VERSION ""

NS_ :

BS_:

BU_: ICC_ICE DVR EPC BBCM PCL PLG EAMP CMSM SBOX AVAS FLZCU RXCU_HCU CGW TBOX BNCM CWC FRZCU

BO_ 1211 FLZCU_26: 32 FLZCU
 SG_ FLZCU_FLSeatHeiFb : 23|7@0+ (1,-1) [-1|100] "%"  ICC_ICE,BBCM,PCL
 SG_ FLZCU_FLSeatLvlFb : 31|7@0+ (1,-1) [-1|100] "%"  ICC_ICE,BBCM,PCL
 SG_ FLZCU_FLSeatBackAgFb : 39|7@0+ (1,-1) [-1|100] "%"  ICC_ICE,BBCM,PCL
 SG_ FLZCU_FLSeatCushFb : 47|7@0+ (1,-1) [-1|100] "%"  ICC_ICE,BBCM,PCL
 SG_ FLZCU_FLSeatLegSpprtFb : 55|7@0+ (1,-1) [-1|100] "%"  ICC_ICE
 SG_ FLZCU_SeatNeedMemory : 63|2@0+ (1,0) [0|3] ""  ICC_ICE
 SG_ FLZCU_MemoryFb : 61|2@0+ (1,0) [0|3] ""  ICC_ICE
 SG_ FLZCU_RecoverFb : 59|2@0+ (1,0) [0|3] ""  ICC_ICE
 SG_ FLZCU_DriverSeatMovFailCause : 87|4@0+ (1,0) [0|15] ""  ICC_ICE
 SG_ FLZCU_CurrSeatMemoryPos : 95|5@0+ (1,0) [0|31] ""  ICC_ICE

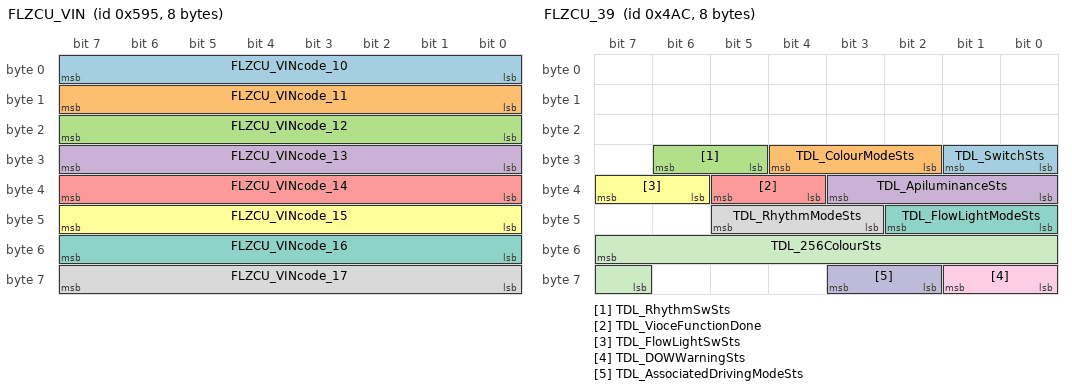
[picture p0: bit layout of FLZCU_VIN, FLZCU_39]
BO_ 1429 FLZCU_VIN: 8 FLZCU
 SG_ FLZCU_VINcode_10 : 7|8@0+ (1,0) [0|127] ""  ICC_ICE
 SG_ FLZCU_VINcode_11 : 15|8@0+ (1,0) [0|127] ""  ICC_ICE
 SG_ FLZCU_VINcode_12 : 23|8@0+ (1,0) [0|127] ""  ICC_ICE
 SG_ FLZCU_VINcode_13 : 31|8@0+ (1,0) [0|127] ""  ICC_ICE
 SG_ FLZCU_VINcode_14 : 39|8@0+ (1,0) [0|127] ""  ICC_ICE
 SG_ FLZCU_VINcode_15 : 47|8@0+ (1,0) [0|127] ""  ICC_ICE
 SG_ FLZCU_VINcode_16 : 55|8@0+ (1,0) [0|127] ""  ICC_ICE
 SG_ FLZCU_VINcode_17 : 63|8@0+ (1,0) [0|127] ""  ICC_ICE

BO_ 1072 FLZCU_31: 16 FLZCU
 SG_ LHFdoorSts_430h : 23|2@0+ (1,0) [0|3] ""  ICC_ICE
 SG_ LHFSeatBeltSW_430h : 31|1@0+ (1,0) [0|1] ""  ICC_ICE,DVR
 SG_ TrunkSts_430h : 37|2@0+ (1,0) [0|3] ""  ICC_ICE
 SG_ RLWinPosn_430h : 47|7@0+ (1,0) [0|100] "%"  ICC_ICE
 SG_ SeatHeatLevelsFL_430h : 49|2@0+ (1,0) [0|3] ""  ICC_ICE
 SG_ SeatHeatLevelsRL_430h : 61|2@0+ (1,0) [0|3] ""  ICC_ICE
 SG_ SeatVentLevelsFL_430h : 63|2@0+ (1,0) [0|3] ""  ICC_ICE
 SG_ SeatVentLevelsRL_430h : 87|2@0+ (1,0) [0|3] ""  ICC_ICE
 SG_ FLWinPosn_430h : 94|7@0+ (1,0) [0|100] "%"  ICC_ICE
 SG_ FLZCU_FrontWiperMaintenanceSts : 109|2@0+ (1,0) [0|3] ""  ICC_ICE
 SG_ FLZCU_RearWiperMaintenanceSts : 107|2@0+ (1,0) [0|3] ""  ICC_ICE

BO_ 1043 FLZCU_8: 8 FLZCU
 SG_ EBS_U_BATT : 7|14@0+ (0.0009765625,3) [3|18] "V"  ICC_ICE

BO_ 1022 FLZCU_40: 64 FLZCU
 SG_ FLZCU_CarMode : 23|3@0+ (1,0) [0|7] ""  ICC_ICE,BBCM,PCL
 SG_ FLZCU_SteerWhlposSts : 20|3@0+ (1,0) [0|7] ""  ICC_ICE
 SG_ FLZCU_MedStatusFb : 17|2@0+ (1,0) [0|3] ""  ICC_ICE,BBCM,PCL
 SG_ FLZCU_MedFailCause : 31|4@0+ (1,0) [0|15] ""  ICC_ICE
 SG_ FLZCU_MedAreaFb : 27|4@0+ (1,0) [0|15] ""  ICC_ICE
 SG_ FLZCU_MedClosePrompt : 39|2@0+ (1,0) [0|3] ""  ICC_ICE
 SG_ FLZCU_NapArea2Fb : 37|3@0+ (1,0) [0|7] ""  ICC_ICE
 SG_ FLZCU_2LSeatLvltargetCmd : 34|7@0+ (1,-1) [-1|100] "%"  ICC_ICE
 SG_ FLZCU_2LSeatBackAgtargetCmd : 43|7@0+ (1,-1) [-1|100] "%"  ICC_ICE
 SG_ FLZCU_2LSeatLegSpprttargetCmd : 52|7@0+ (1,-1) [-1|100] "%"  ICC_ICE
 SG_ FLZCU_FLWinThermalStatus : 61|1@0+ (1,0) [0|1] ""  ICC_ICE
 SG_ FLZCU_RLWinThermalStatus : 60|1@0+ (1,0) [0|1] ""  ICC_ICE
 SG_ FLZCU_MonoAmbLigSts : 59|1@0+ (1,0) [0|1] ""  ICC_ICE
 SG_ FLZCU_LogoChargingSts : 58|2@0+ (1,0) [0|3] ""  ICC_ICE
 SG_ FLZCU_2RSeatLvltargetCmd : 87|7@0+ (1,-1) [-1|100] "%"  ICC_ICE
 SG_ FLZCU_2RSeatBackAgtargetCmd : 80|7@0+ (1,-1) [-1|100] "%"  ICC_ICE
 SG_ FLZCU_2RSeatLegSpprttargetCmd : 89|7@0+ (1,-1) [-1|100] "%"  ICC_ICE
 SG_ FLZCU_SeatVentLvlFL2 : 111|4@0+ (1,0) [0|15] ""  ICC_ICE
 SG_ FLZCU_SeatVentLvlRL2 : 107|4@0+ (1,0) [0|15] ""  ICC_ICE
 SG_ FLZCU_SeatHeatLvlFL2 : 119|4@0+ (1,0) [0|15] ""  ICC_ICE
 SG_ FLZCU_SeatHeatLvlRL2 : 115|4@0+ (1,0) [0|15] ""  ICC_ICE
 SG_ FLZCU_FLSitPosnSts : 98|3@0+ (1,0) [0|7] ""  ICC_ICE
 SG_ FLZCU_SteerOverHeatWarn : 134|1@0+ (1,0) [0|1] ""  ICC_ICE
 SG_ FLZCU_FLogolightInhibitSts : 130|1@0+ (1,0) [0|1] ""  ICC_ICE
 SG_ MaintenanceOdometer_Backup_3FEh : 175|24@0+ (0.1,0) [0|999999.9] "KM"  ICC_ICE

BO_ 1020 FLZCU_41: 64 FLZCU
 SG_ SAM_1_SteeringAngleSpeed : 23|8@0+ (4,0) [0|1016] "deg/Sec"  ICC_ICE
 SG_ SAM_1_SteeringAngle : 31|16@0+ (0.0625,-2048) [-2048|2047.875] "deg"  ICC_ICE
 SG_ BMSH_MaxChgPwrPeak : 47|12@0+ (0.1,0) [0|320] "KW"  ICC_ICE
 SG_ BMSH_MaxDchgPwrPeak : 51|12@0+ (0.1,0) [0|320] "KW"  ICC_ICE
 SG_ FMCU_8_ISGF_SpdAct : 71|16@0+ (1,-32767) [-32767|32766] "rpm"  ICC_ICE
 SG_ RMCU_1_Speed : 87|16@0+ (1,-32767) [-32767|32766] "rpm"  ICC_ICE
 SG_ SAM_1_SteeringAngleVD : 96|1@0+ (1,0) [0|1] ""  ICC_ICE
 SG_ SAM_1_SteeringAngleSpeedVD : 97|1@0+ (1,0) [0|1] ""  ICC_ICE
 SG_ CSA_2_AllWarningInfo : 100|3@0+ (1,0) [0|7] ""  ICC_ICE
 SG_ RMCU_1_TCURErrLvlDis : 127|3@0+ (1,0) [0|4] ""  ICC_ICE
 SG_ ASU_2_sensorErrorSts : 143|4@0+ (1,0) [0|15] ""  ICC_ICE
 SG_ ASU_2_LFHeight : 151|12@0+ (0.1,-150) [0|259.4] "mm"  ICC_ICE
 SG_ ASU_2_RFHeight : 155|12@0+ (0.1,-150) [0|259.4] "mm"  ICC_ICE
 SG_ ASU_2_LRHeight : 175|12@0+ (0.1,-150) [0|259.4] "mm"  ICC_ICE
 SG_ ASU_2_RRHeight : 179|12@0+ (0.1,-150) [0|259.4] "mm"  ICC_ICE
 SG_ CSA_2_WiprFrntCmd : 209|2@0+ (1,0) [0|3] ""  ICC_ICE

BO_ 1035 VCC_1: 8 FLZCU
 SG_ VCC_1_OTASts : 17|2@0+ (1,0) [0|3] ""  ICC_ICE
 SG_ VCC_1_DriveMode : 36|5@0+ (1,0) [0|31] ""  ICC_ICE

BO_ 1075 VCC_2: 8 FLZCU
 SG_ VCC_2_ConfigurationMessageTrg : 23|1@0+ (1,0) [0|1] ""  ICC_ICE,BBCM,PCL,PLG

BO_ 1136 VCC_3: 32 FLZCU
 SG_ VCC_3_CRC : 7|8@0+ (1,0) [0|255] ""  ICC_ICE,BBCM,PCL,PLG
 SG_ VCC_3_RollgCntr : 11|4@0+ (1,0) [0|14] ""  ICC_ICE,BBCM,PCL,PLG
 SG_ VCC_3_Resd1 : 15|4@0+ (1,0) [0|15] ""  ICC_ICE,BBCM,PCL,PLG
 SG_ VCC_3_SN : 23|8@0+ (1,0) [1|32] ""  ICC_ICE,BBCM,PCL,PLG

BO_ 1196 FLZCU_39: 8 FLZCU
 SG_ TDL_SwitchSts : 25|2@0+ (1,0) [0|3] ""  ICC_ICE
 SG_ TDL_ColourModeSts : 28|3@0+ (1,0) [0|7] ""  ICC_ICE
 SG_ TDL_RhythmSwSts : 30|2@0+ (1,0) [0|3] ""  ICC_ICE
 SG_ TDL_ApiluminanceSts : 35|4@0+ (1,0) [0|15] ""  ICC_ICE
 SG_ TDL_VioceFunctionDone : 37|2@0+ (1,0) [0|3] ""  ICC_ICE
 SG_ TDL_FlowLightSwSts : 39|2@0+ (1,0) [0|3] ""  ICC_ICE
 SG_ TDL_FlowLightModeSts : 42|3@0+ (1,0) [0|7] ""  ICC_ICE
 SG_ TDL_RhythmModeSts : 45|3@0+ (1,0) [0|7] ""  ICC_ICE
 SG_ TDL_DOWWarningSts : 57|2@0+ (1,0) [0|3] ""  ICC_ICE
 SG_ TDL_AssociatedDrivingModeSts : 59|2@0+ (1,0) [0|3] ""  ICC_ICE
 SG_ TDL_256ColourSts : 55|9@0+ (1,0) [0|256] ""  ICC_ICE

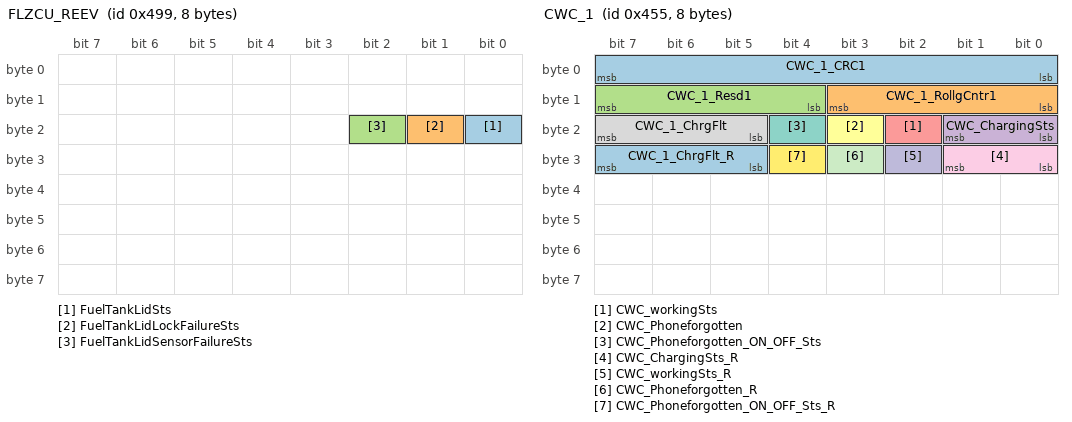
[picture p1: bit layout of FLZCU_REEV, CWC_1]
BO_ 1177 FLZCU_REEV: 8 FLZCU
 SG_ FuelTankLidSts : 16|1@0+ (1,0) [0|1] ""  ICC_ICE
 SG_ FuelTankLidLockFailureSts : 17|1@0+ (1,0) [0|1] ""  ICC_ICE
 SG_ FuelTankLidSensorFailureSts : 18|1@0+ (1,0) [0|1] ""  ICC_ICE

BO_ 2015 OBD_REQ_Broadcast: 64 CGW
 SG_ Diag_Functional_REQ : 7|64@0+ (1,0) [0|1.84467440737096E+19] ""  ICC_ICE,DVR,EPC,BBCM,PCL,PLG,EAMP,CMSM,SBOX

BO_ 1109 CWC_1: 8 CGW
 SG_ CWC_1_CRC1 : 7|8@0+ (1,0) [0|255] ""  ICC_ICE
 SG_ CWC_1_RollgCntr1 : 11|4@0+ (1,0) [0|14] ""  ICC_ICE
 SG_ CWC_1_Resd1 : 15|4@0+ (1,0) [0|15] ""  ICC_ICE
 SG_ CWC_ChargingSts : 17|2@0+ (1,0) [0|3] ""  ICC_ICE
 SG_ CWC_workingSts : 18|1@0+ (1,0) [0|1] ""  ICC_ICE
 SG_ CWC_Phoneforgotten : 19|1@0+ (1,0) [0|1] ""  ICC_ICE
 SG_ CWC_Phoneforgotten_ON_OFF_Sts : 20|1@0+ (1,0) [0|1] ""  ICC_ICE
 SG_ CWC_1_ChrgFlt : 23|3@0+ (1,0) [0|7] ""  ICC_ICE
 SG_ CWC_ChargingSts_R : 25|2@0+ (1,0) [0|3] ""  ICC_ICE
 SG_ CWC_workingSts_R : 26|1@0+ (1,0) [0|1] ""  ICC_ICE
 SG_ CWC_Phoneforgotten_R : 27|1@0+ (1,0) [0|1] ""  ICC_ICE
 SG_ CWC_Phoneforgotten_ON_OFF_Sts_R : 28|1@0+ (1,0) [0|1] ""  ICC_ICE
 SG_ CWC_1_ChrgFlt_R : 31|3@0+ (1,0) [0|7] ""  ICC_ICE

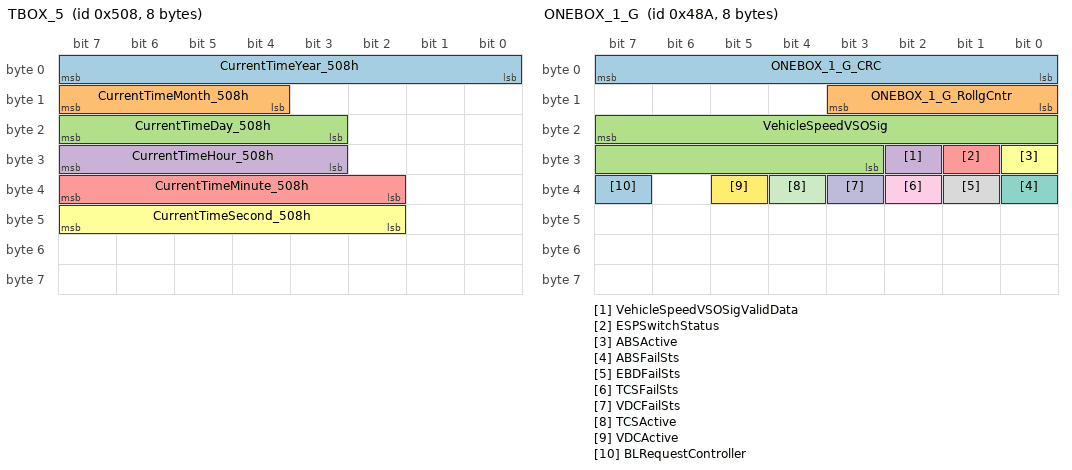
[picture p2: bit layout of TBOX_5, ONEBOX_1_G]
BO_ 1288 TBOX_5: 8 CGW
 SG_ CurrentTimeYear_508h : 7|8@0+ (1,2000) [2000|2255] ""  ICC_ICE,SBOX
 SG_ CurrentTimeMonth_508h : 15|4@0+ (1,0) [1|12] ""  ICC_ICE,SBOX
 SG_ CurrentTimeDay_508h : 23|5@0+ (1,0) [1|31] ""  ICC_ICE,SBOX
 SG_ CurrentTimeHour_508h : 31|5@0+ (1,0) [0|23] ""  ICC_ICE,SBOX
 SG_ CurrentTimeMinute_508h : 39|6@0+ (1,0) [0|59] ""  ICC_ICE,SBOX
 SG_ CurrentTimeSecond_508h : 47|6@0+ (1,0) [0|59] ""  ICC_ICE,SBOX

BO_ 1063 TBOX_6: 8 CGW
 SG_ TBOX_PetmodeSwitch : 19|2@0+ (1,0) [0|3] ""  ICC_ICE
 SG_ TBOX_SentinelModeSw : 21|2@0+ (1,0) [0|3] ""  ICC_ICE

BO_ 1148 TBOX_7: 32 CGW
 SG_ TBOX_GPSSwitchSts : 33|2@0+ (1,0) [0|3] ""  ICC_ICE
 SG_ TBOX_KeepWarmStrtMin : 151|6@0+ (1,0) [0|59] "分钟"  ICC_ICE
 SG_ TimeToStartSentinelDayFed_47Ch : 153|2@0+ (1,0) [0|3] "日"  ICC_ICE
 SG_ TimeToStartSentinelHourFed_47Ch : 158|5@0+ (1,0) [0|31] "小时"  ICC_ICE
 SG_ TimeToStartSentinelMinutFed_47Ch : 165|6@0+ (1,0) [0|63] "分钟"  ICC_ICE
 SG_ TimeToStopSentinelHourFed_47Ch : 172|5@0+ (1,0) [0|31] "小时"  ICC_ICE
 SG_ TimeToStopSentinelMinutFed_47Ch : 181|6@0+ (1,0) [0|63] "分钟"  ICC_ICE
 SG_ ReservationSentinelSts_Fed_47Ch : 183|2@0+ (1,0) [0|3] ""  ICC_ICE

BO_ 1162 ONEBOX_1_G: 8 CGW
 SG_ ONEBOX_1_G_CRC : 7|8@0+ (1,0) [0|255] ""  ICC_ICE,BBCM,PCL,PLG
 SG_ ONEBOX_1_G_RollgCntr : 11|4@0+ (1,0) [0|14] ""  ICC_ICE,BBCM,PCL,PLG
 SG_ VehicleSpeedVSOSig : 23|13@0+ (0.0625,0) [0|511.875] "km/h"  ICC_ICE,DVR,EPC,BBCM,PCL,PLG,EAMP,CMSM,SBOX,AVAS
 SG_ VehicleSpeedVSOSigValidData : 26|1@0+ (1,0) [0|1] ""  ICC_ICE,DVR,EPC,BBCM,PCL,PLG,EAMP,CMSM,SBOX,AVAS
 SG_ ESPSwitchStatus : 25|1@0+ (1,0) [0|1] ""  ICC_ICE
 SG_ ABSActive : 24|1@0+ (1,0) [0|1] ""  ICC_ICE
 SG_ ABSFailSts : 32|1@0+ (1,0) [0|1] ""  ICC_ICE
 SG_ EBDFailSts : 33|1@0+ (1,0) [0|1] ""  ICC_ICE
 SG_ TCSFailSts : 34|1@0+ (1,0) [0|1] ""  ICC_ICE
 SG_ VDCFailSts : 35|1@0+ (1,0) [0|1] ""  ICC_ICE
 SG_ TCSActive : 36|1@0+ (1,0) [0|1] ""  ICC_ICE
 SG_ VDCActive : 37|1@0+ (1,0) [0|1] ""  ICC_ICE
 SG_ BLRequestController : 39|1@0+ (1,0) [0|1] ""  ICC_ICE

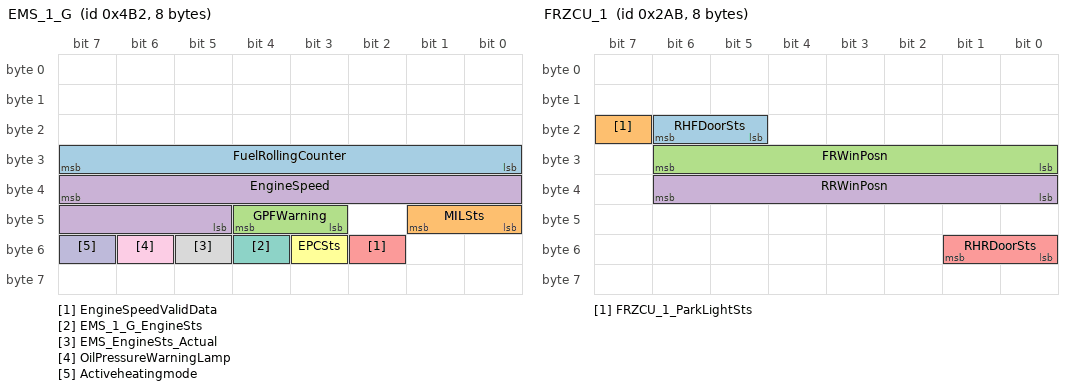
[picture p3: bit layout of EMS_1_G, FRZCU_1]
BO_ 1202 EMS_1_G: 8 CGW
 SG_ FuelRollingCounter : 31|8@0+ (7.88519E-05,0) [0|0.0200283826] "ltr"  ICC_ICE
 SG_ MILSts : 41|2@0+ (1,0) [0|3] ""  ICC_ICE
 SG_ GPFWarning : 44|2@0+ (1,0) [0|3] ""  ICC_ICE
 SG_ EngineSpeed : 39|11@0+ (4,0) [0|8000] "rpm"  ICC_ICE,AVAS
 SG_ EngineSpeedValidData : 50|1@0+ (1,0) [0|1] ""  ICC_ICE
 SG_ EPCSts : 51|1@0+ (1,0) [0|1] ""  ICC_ICE
 SG_ EMS_1_G_EngineSts : 52|1@0+ (1,0) [0|1] ""  ICC_ICE
 SG_ EMS_EngineSts_Actual : 53|1@0+ (1,0) [0|1] ""  ICC_ICE,EAMP
 SG_ OilPressureWarningLamp : 54|1@0+ (1,0) [0|1] ""  ICC_ICE
 SG_ Activeheatingmode : 55|1@0+ (1,0) [0|1] ""  ICC_ICE

BO_ 683 FRZCU_1: 8 CGW
 SG_ RHFDoorSts : 22|2@0+ (1,0) [0|3] ""  ICC_ICE,EPC,BBCM,PCL,CMSM
 SG_ FRZCU_1_ParkLightSts : 23|1@0+ (1,0) [0|1] ""  ICC_ICE
 SG_ FRWinPosn : 30|7@0+ (1,0) [0|100] "%"  ICC_ICE
 SG_ RRWinPosn : 38|7@0+ (1,0) [0|100] "%"  ICC_ICE
 SG_ RHRDoorSts : 49|2@0+ (1,0) [0|3] ""  ICC_ICE,EPC,BBCM,PCL,CMSM

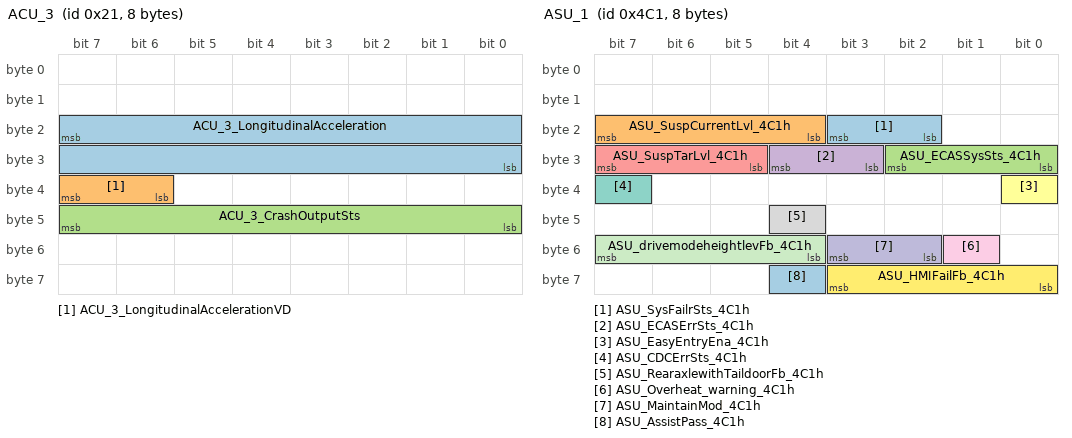
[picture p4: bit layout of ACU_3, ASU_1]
BO_ 33 ACU_3: 8 CGW
 SG_ ACU_3_LongitudinalAcceleration : 23|16@0+ (0.001,-2) [-2|2] "g"  ICC_ICE
 SG_ ACU_3_LongitudinalAccelerationVD : 39|2@0+ (1,0) [0|3] ""  ICC_ICE
 SG_ ACU_3_CrashOutputSts : 47|8@0+ (1,0) [0|255] ""  ICC_ICE,DVR,EPC,BBCM,PCL,SBOX

BO_ 1217 ASU_1: 8 CGW
 SG_ ASU_SysFailrSts_4C1h : 19|2@0+ (1,0) [0|3] ""  ICC_ICE
 SG_ ASU_SuspCurrentLvl_4C1h : 23|4@0+ (1,0) [0|15] ""  ICC_ICE
 SG_ ASU_ECASSysSts_4C1h : 26|3@0+ (1,0) [0|7] ""  ICC_ICE
 SG_ ASU_ECASErrSts_4C1h : 28|2@0+ (1,0) [0|3] ""  ICC_ICE
 SG_ ASU_SuspTarLvl_4C1h : 31|3@0+ (1,0) [0|7] ""  ICC_ICE
 SG_ ASU_EasyEntryEna_4C1h : 32|1@0+ (1,0) [0|1] ""  ICC_ICE
 SG_ ASU_CDCErrSts_4C1h : 39|1@0+ (1,0) [0|1] ""  ICC_ICE
 SG_ ASU_RearaxlewithTaildoorFb_4C1h : 44|1@0+ (1,0) [0|1] ""  ICC_ICE
 SG_ ASU_Overheat_warning_4C1h : 49|1@0+ (1,0) [0|1] ""  ICC_ICE
 SG_ ASU_MaintainMod_4C1h : 51|2@0+ (1,0) [0|3] ""  ICC_ICE
 SG_ ASU_drivemodeheightlevFb_4C1h : 55|4@0+ (1,0) [0|15] ""  ICC_ICE
 SG_ ASU_HMIFailFb_4C1h : 59|4@0+ (1,0) [0|15] ""  ICC_ICE
 SG_ ASU_AssistPass_4C1h : 60|1@0+ (1,0) [0|1] ""  ICC_ICE

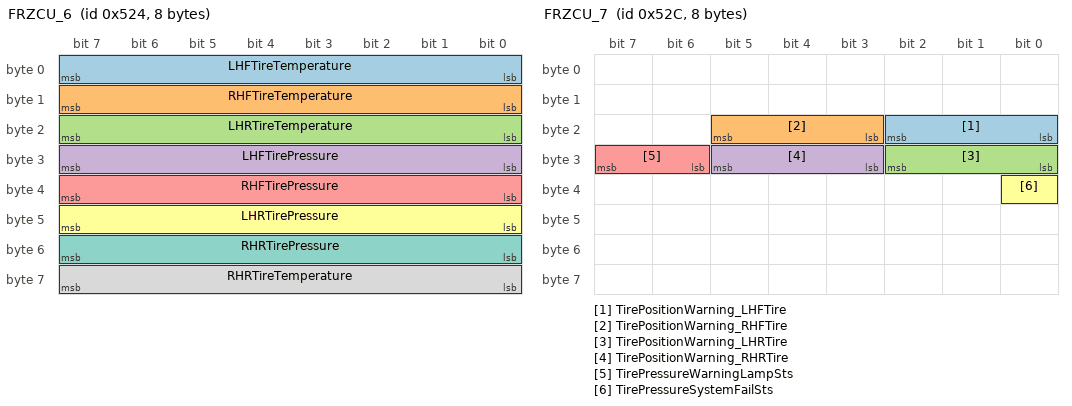
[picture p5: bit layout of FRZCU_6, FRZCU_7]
BO_ 1316 FRZCU_6: 8 CGW
 SG_ LHFTireTemperature : 7|8@0+ (0.65,-40) [-40|125.1] "℃"  ICC_ICE
 SG_ RHFTireTemperature : 15|8@0+ (0.65,-40) [-40|125.1] "℃"  ICC_ICE
 SG_ LHRTireTemperature : 23|8@0+ (0.65,-40) [-40|125.1] "℃"  ICC_ICE
 SG_ LHFTirePressure : 31|8@0+ (2.75,0) [0|701.25] "kPa"  ICC_ICE
 SG_ RHFTirePressure : 39|8@0+ (2.75,0) [0|701.25] "kPa"  ICC_ICE
 SG_ LHRTirePressure : 47|8@0+ (2.75,0) [0|701.25] "kPa"  ICC_ICE
 SG_ RHRTirePressure : 55|8@0+ (2.75,0) [0|701.25] "kPa"  ICC_ICE
 SG_ RHRTireTemperature : 63|8@0+ (0.65,-40) [-40|125.1] "℃"  ICC_ICE

BO_ 1324 FRZCU_7: 8 CGW
 SG_ TirePositionWarning_LHFTire : 18|3@0+ (1,0) [0|7] ""  ICC_ICE
 SG_ TirePositionWarning_RHFTire : 21|3@0+ (1,0) [0|7] ""  ICC_ICE
 SG_ TirePositionWarning_LHRTire : 26|3@0+ (1,0) [0|7] ""  ICC_ICE
 SG_ TirePositionWarning_RHRTire : 29|3@0+ (1,0) [0|7] ""  ICC_ICE
 SG_ TirePressureWarningLampSts : 31|2@0+ (1,0) [0|3] ""  ICC_ICE
 SG_ TirePressureSystemFailSts : 32|1@0+ (1,0) [0|1] ""  ICC_ICE

BO_ 991 TMS_2: 24 CGW
 SG_ TMS_MotorLoopErrorLevel : 126|3@0+ (1,0) [0|7] ""  ICC_ICE
 SG_ TMS_BatteryLoopErrorLevel : 123|3@0+ (1,0) [0|7] ""  ICC_ICE

BO_ 1188 TMS_3: 32 CGW
 SG_ FrontDeforestDisplaySts : 16|1@0+ (1,0) [0|1] ""  ICC_ICE
 SG_ TMS_DisplayActive : 18|1@0+ (1,0) [0|1] ""  ICC_ICE
 SG_ TMS_ZoneSelectionDisplaySts : 19|1@0+ (1,0) [0|1] ""  ICC_ICE
 SG_ TMS_AutoDisplaySts : 20|1@0+ (1,0) [0|1] ""  ICC_ICE
 SG_ TMS_FiltertchangeDisplaySts : 21|1@0+ (1,0) [0|1] ""  ICC_ICE
 SG_ TMS_AUTODefrostOnSts : 22|1@0+ (1,0) [0|1] ""  ICC_ICE
 SG_ TMS_AUTODefrostDisplaySts : 23|1@0+ (1,0) [0|1] ""  ICC_ICE
 SG_ TMS_RefInSufDispSts : 24|1@0+ (1,0) [0|1] ""  ICC_ICE
 SG_ TMS_CooltInSufDispSts : 25|1@0+ (1,0) [0|1] ""  ICC_ICE
 SG_ TMS_DLOnOffSts : 26|1@0+ (1,0) [0|1] ""  ICC_ICE
 SG_ TMS_DROnOffSts : 27|1@0+ (1,0) [0|1] ""  ICC_ICE
 SG_ TMS_PLOnOffSts : 28|1@0+ (1,0) [0|1] ""  ICC_ICE
 SG_ WorkingSts : 29|1@0+ (1,0) [0|1] ""  ICC_ICE
 SG_ TMS_PROnOffSts : 30|1@0+ (1,0) [0|1] ""  ICC_ICE
 SG_ TMS_DCOnOffSts : 31|1@0+ (1,0) [0|1] ""  ICC_ICE
 SG_ TMS_ACFastCool : 48|1@0+ (1,0) [0|1] ""  ICC_ICE
 SG_ TMS_ACFastHeat : 49|1@0+ (1,0) [0|1] ""  ICC_ICE
 SG_ TMS_LoveRemind : 50|1@0+ (1,0) [0|1] ""  ICC_ICE
 SG_ TMS_InteCleanCar : 51|1@0+ (1,0) [0|1] ""  ICC_ICE
 SG_ TMS_ACVentilationSts : 52|1@0+ (1,0) [0|1] ""  ICC_ICE
 SG_ TMS_AutoAirCleanSts : 53|1@0+ (1,0) [0|1] ""  ICC_ICE
 SG_ PM25Sts : 54|1@0+ (1,0) [0|1] ""  ICC_ICE
 SG_ TMS_ACModeCustomSts : 33|2@0+ (1,0) [0|3] ""  ICC_ICE
 SG_ TMS_ACRequestDisplaySts : 36|3@0+ (1,0) [0|7] ""  ICC_ICE
 SG_ TMS_AUTODefLevelSts : 39|3@0+ (1,0) [0|7] ""  ICC_ICE
 SG_ TMS_KeepWarm : 41|2@0+ (1,0) [0|3] ""  ICC_ICE
 SG_ TMS_DSwingSts : 44|3@0+ (1,0) [0|7] ""  ICC_ICE
 SG_ TMS_PSwingSts : 47|3@0+ (1,0) [0|7] ""  ICC_ICE
 SG_ TMS_TuisongDispSts : 58|3@0+ (1,0) [0|7] ""  ICC_ICE
 SG_ TMS_SetTemperature_L_C : 63|5@0+ (0.5,15.5) [15.5|30.5] ""  ICC_ICE
 SG_ TMS_SetTemperature_R_C : 68|5@0+ (0.5,15.5) [15.5|30.5] ""  ICC_ICE
 SG_ TMS_ModeAdjustDisplaySts : 75|4@0+ (1,0) [0|15] ""  ICC_ICE
 SG_ TMS_CirculationModeDisplaySts : 79|2@0+ (1,0) [0|3] ""  ICC_ICE
 SG_ TMS_IncarTemp : 87|8@0+ (0.5,-40) [-40|85] ""  ICC_ICE
 SG_ TMS_FliterLife : 94|7@0+ (1,0) [0|100] ""  ICC_ICE
 SG_ TMS_DLSwingUpDwnWPosn : 102|7@0+ (1,0) [0|100] ""  ICC_ICE
 SG_ TMS_DLSwingLeRiWPosn : 110|7@0+ (1,0) [0|100] ""  ICC_ICE
 SG_ TMS_DRSwingUpDwnWPosn : 118|7@0+ (1,0) [0|100] ""  ICC_ICE
 SG_ TMS_DRSwingLeRiWPosn : 126|7@0+ (1,0) [0|100] ""  ICC_ICE
 SG_ TMS_PLSwingUpDwnWPosn : 134|7@0+ (1,0) [0|100] ""  ICC_ICE
 SG_ TMS_PLSwingLeRiWPosn : 142|7@0+ (1,0) [0|100] ""  ICC_ICE
 SG_ TMS_PRSwingUpDwnWPosn : 150|7@0+ (1,0) [0|100] ""  ICC_ICE
 SG_ TMS_PRSwingLeRiWPosn : 158|7@0+ (1,0) [0|100] ""  ICC_ICE
 SG_ TMS_DCSwingLeRiWPosn : 166|7@0+ (1,0) [0|100] ""  ICC_ICE
 SG_ AirSwingSts : 168|1@0+ (1,0) [0|1] ""  ICC_ICE
 SG_ TemperatureUnit : 169|1@0+ (1,0) [0|1] ""  ICC_ICE
 SG_ BlowAdvanceOnSts : 170|1@0+ (1,0) [0|1] ""  ICC_ICE
 SG_ BlowDelayOffSts : 171|1@0+ (1,0) [0|1] ""  ICC_ICE
 SG_ TMS_PM25_ExtSts : 172|1@0+ (1,0) [0|1] ""  ICC_ICE
 SG_ TMS_PM25_IncarSts : 173|1@0+ (1,0) [0|1] ""  ICC_ICE
 SG_ TMS_AQS_Sts : 174|1@0+ (1,0) [0|1] ""  ICC_ICE
 SG_ PM25overproofDisplaySts : 175|1@0+ (1,0) [0|1] ""  ICC_ICE
 SG_ AQSDisplaySts : 176|1@0+ (1,0) [0|1] ""  ICC_ICE
 SG_ PM25AutoRunSts : 177|1@0+ (1,0) [0|1] ""  ICC_ICE
 SG_ PM25AutoRunSetSts : 178|1@0+ (1,0) [0|1] ""  ICC_ICE
 SG_ FragranceWelcomeModeSts : 179|1@0+ (1,0) [0|1] ""  ICC_ICE
 SG_ FragranceDisplaysts : 180|1@0+ (1,0) [0|1] ""  ICC_ICE
 SG_ TMS_AQS_Level : 185|2@0+ (1,0) [0|3] ""  ICC_ICE
 SG_ ACRequestCommand : 188|3@0+ (1,0) [0|7] ""  ICC_ICE
 SG_ PM25_Outcar_Level : 191|3@0+ (1,0) [0|7] ""  ICC_ICE
 SG_ PM25_Incar_Level : 194|3@0+ (1,0) [0|7] ""  ICC_ICE
 SG_ SetTemperature_L_F : 215|5@0+ (1,63) [63|93] ""  ICC_ICE
 SG_ SetTemperature_R_F : 223|5@0+ (1,63) [63|93] ""  ICC_ICE
 SG_ TMS_PM25_incar : 231|10@0+ (1,0) [0|1000] ""  ICC_ICE
 SG_ TMS_PM25_ext : 237|10@0+ (1,0) [0|1000] ""  ICC_ICE
 SG_ TMS_KeepWarmMemoryFb : 243|2@0+ (1,0) [0|3] ""  ICC_ICE

BO_ 612 EPB_R_1: 24 CGW
 SG_ CRC1_264h : 7|8@0+ (1,0) [0|255] ""  ICC_ICE
 SG_ RollgCntr1_264h : 11|4@0+ (1,0) [0|14] ""  ICC_ICE
 SG_ FltLamp_264h : 18|2@0+ (1,0) [0|3] ""  ICC_ICE
 SG_ ParkLamp_264h : 20|2@0+ (1,0) [0|3] ""  ICC_ICE
 SG_ ActrSt_264h : 23|3@0+ (1,0) [0|7] ""  ICC_ICE,DVR
 SG_ RWUSt_264h : 25|1@0+ (1,0) [0|1] ""  ICC_ICE
 SG_ TextDisp_264h : 35|4@0+ (1,0) [0|15] ""  ICC_ICE
 SG_ IPB_EPBErrorStatus : 41|1@0+ (1,0) [0|1] ""  ICC_ICE

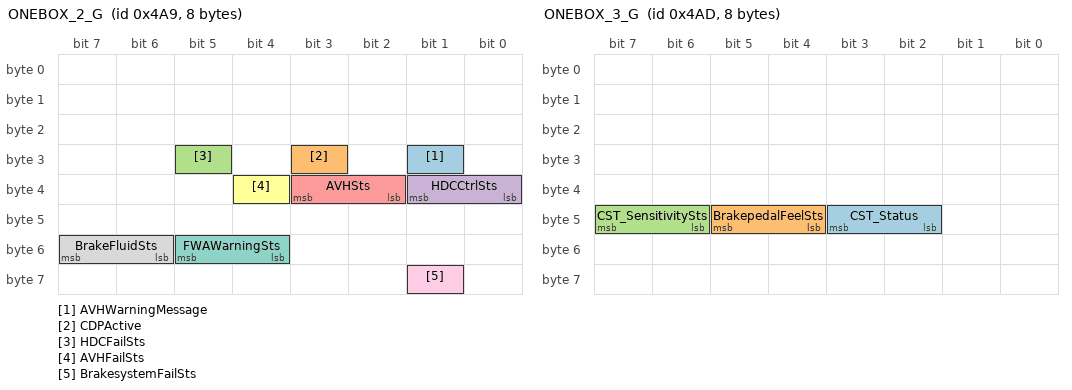
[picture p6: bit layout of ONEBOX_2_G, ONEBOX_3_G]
BO_ 1193 ONEBOX_2_G: 8 CGW
 SG_ AVHWarningMessage : 25|1@0+ (1,0) [0|1] ""  ICC_ICE
 SG_ CDPActive : 27|1@0+ (1,0) [0|1] ""  ICC_ICE
 SG_ HDCFailSts : 29|1@0+ (1,0) [0|1] ""  ICC_ICE
 SG_ HDCCtrlSts : 33|2@0+ (1,0) [0|3] ""  ICC_ICE
 SG_ AVHSts : 35|2@0+ (1,0) [0|3] ""  ICC_ICE
 SG_ AVHFailSts : 36|1@0+ (1,0) [0|1] ""  ICC_ICE
 SG_ FWAWarningSts : 53|2@0+ (1,0) [0|3] ""  ICC_ICE
 SG_ BrakeFluidSts : 55|2@0+ (1,0) [0|3] ""  ICC_ICE
 SG_ BrakesystemFailSts : 57|1@0+ (1,0) [0|1] ""  ICC_ICE

BO_ 1197 ONEBOX_3_G: 8 CGW
 SG_ CST_Status : 43|2@0+ (1,0) [0|3] ""  ICC_ICE
 SG_ BrakepedalFeelSts : 45|2@0+ (1,0) [0|3] ""  ICC_ICE
 SG_ CST_SensitivitySts : 47|2@0+ (1,0) [0|3] ""  ICC_ICE

BO_ 1200 FLZCU_6: 8 CGW
 SG_ SOC : 7|8@0+ (1,0) [0|100] "%"  ICC_ICE

BO_ 1061 FLZCU_18: 8 CGW
 SG_ DriverSeatMsgStr_LvlSts : 18|3@0+ (1,0) [0|7] ""  ICC_ICE
 SG_ DriverSeatMsg_ModeSts : 23|4@0+ (1,0) [0|15] ""  ICC_ICE

BO_ 1065 FLZCU_19: 8 CGW
 SG_ LeftSeatMsgStr_LvlSts : 18|3@0+ (1,0) [0|7] ""  ICC_ICE
 SG_ LeftSeatMsg_ModeSts : 23|4@0+ (1,0) [0|15] ""  ICC_ICE

BO_ 1069 FLZCU_20: 8 CGW
 SG_ PassSeatMsgStr_LvlSts : 18|3@0+ (1,0) [0|7] ""  ICC_ICE
 SG_ PassSeatMsg_ModeSts : 23|4@0+ (1,0) [0|15] ""  ICC_ICE

BO_ 1087 FLZCU_21: 8 CGW
 SG_ RightSeatMsgStr_LvlSts : 18|3@0+ (1,0) [0|7] ""  ICC_ICE
 SG_ RightSeatMsg_ModeSts : 23|4@0+ (1,0) [0|15] ""  ICC_ICE

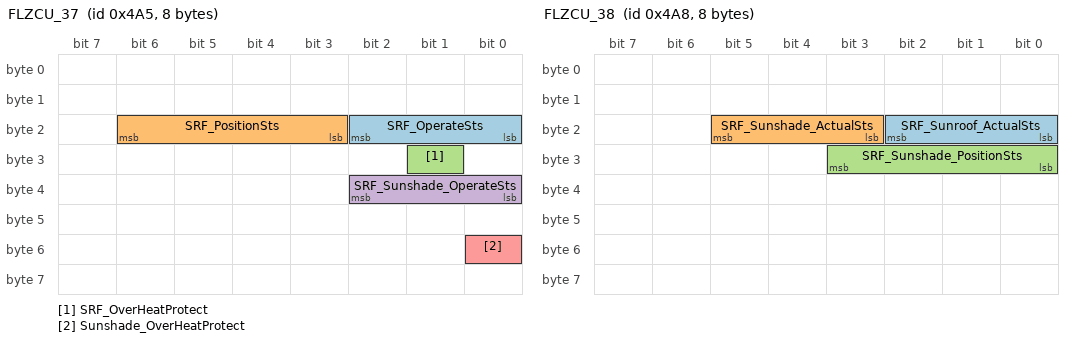
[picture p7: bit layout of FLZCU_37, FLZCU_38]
BO_ 1189 FLZCU_37: 8 CGW
 SG_ SRF_OperateSts : 18|3@0+ (1,0) [0|7] ""  ICC_ICE
 SG_ SRF_PositionSts : 22|4@0+ (1,0) [0|12] ""  ICC_ICE
 SG_ SRF_OverHeatProtect : 25|1@0+ (1,0) [0|1] ""  ICC_ICE
 SG_ SRF_Sunshade_OperateSts : 34|3@0+ (1,0) [0|7] ""  ICC_ICE
 SG_ Sunshade_OverHeatProtect : 48|1@0+ (1,0) [0|1] ""  ICC_ICE

BO_ 1192 FLZCU_38: 8 CGW
 SG_ SRF_Sunroof_ActualSts : 18|3@0+ (1,0) [0|7] ""  ICC_ICE
 SG_ SRF_Sunshade_ActualSts : 21|3@0+ (1,0) [0|7] ""  ICC_ICE
 SG_ SRF_Sunshade_PositionSts : 27|4@0+ (1,0) [0|12] ""  ICC_ICE

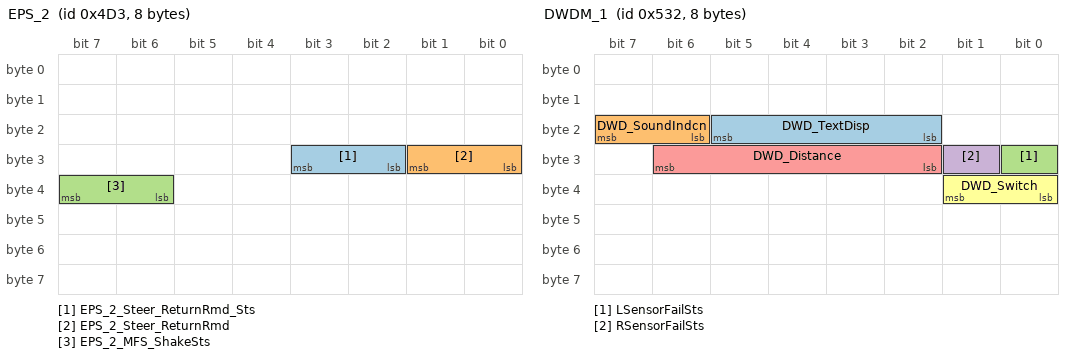
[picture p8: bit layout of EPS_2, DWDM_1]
BO_ 1235 EPS_2: 8 CGW
 SG_ EPS_2_Steer_ReturnRmd_Sts : 27|2@0+ (1,0) [0|3] ""  ICC_ICE
 SG_ EPS_2_Steer_ReturnRmd : 25|2@0+ (1,0) [0|3] ""  ICC_ICE
 SG_ EPS_2_MFS_ShakeSts : 39|2@0+ (1,0) [0|3] ""  ICC_ICE

BO_ 1330 DWDM_1: 8 CGW
 SG_ DWD_TextDisp : 21|4@0+ (1,0) [0|15] ""  ICC_ICE
 SG_ DWD_SoundIndcn : 23|2@0+ (1,0) [0|3] ""  ICC_ICE
 SG_ LSensorFailSts : 24|1@0+ (1,0) [0|1] ""  ICC_ICE
 SG_ RSensorFailSts : 25|1@0+ (1,0) [0|1] ""  ICC_ICE
 SG_ DWD_Distance : 30|5@0+ (1,0) [0|31] ""  ICC_ICE
 SG_ DWD_Switch : 33|2@0+ (1,0) [0|3] ""  ICC_ICE

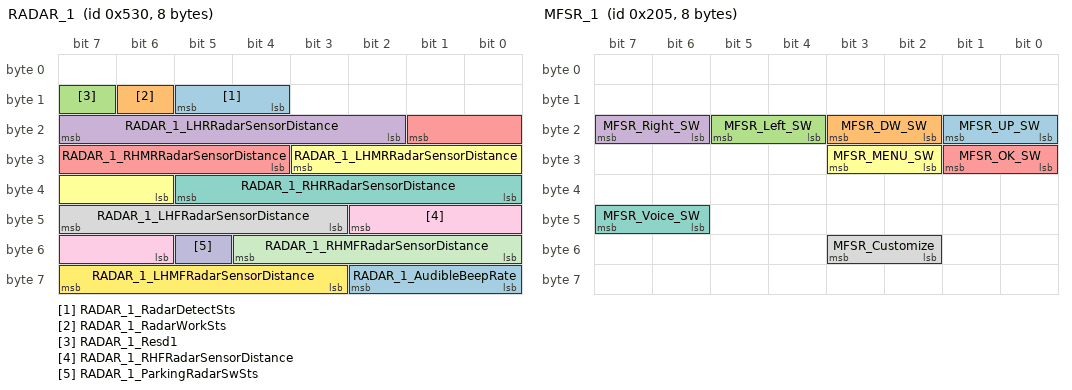
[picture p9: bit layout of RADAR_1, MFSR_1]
BO_ 1328 RADAR_1: 8 CGW
 SG_ RADAR_1_RadarDetectSts : 13|2@0+ (1,0) [0|3] ""  ICC_ICE
 SG_ RADAR_1_RadarWorkSts : 14|1@0+ (1,0) [0|1] ""  ICC_ICE
 SG_ RADAR_1_Resd1 : 15|1@0+ (1,0) [0|1] ""  ICC_ICE
 SG_ RADAR_1_LHRRadarSensorDistance : 23|6@0+ (5,25) [25|180] "Cm"  ICC_ICE
 SG_ RADAR_1_RHMRRadarSensorDistance : 17|6@0+ (5,25) [25|180] "Cm"  ICC_ICE
 SG_ RADAR_1_LHMRRadarSensorDistance : 27|6@0+ (5,25) [25|180] "Cm"  ICC_ICE
 SG_ RADAR_1_RHRRadarSensorDistance : 37|6@0+ (5,25) [25|180] "Cm"  ICC_ICE
 SG_ RADAR_1_LHFRadarSensorDistance : 47|5@0+ (5,25) [25|160] "Cm"  ICC_ICE
 SG_ RADAR_1_RHFRadarSensorDistance : 42|5@0+ (5,25) [25|160] "Cm"  ICC_ICE
 SG_ RADAR_1_ParkingRadarSwSts : 53|1@0+ (1,0) [0|1] ""  ICC_ICE
 SG_ RADAR_1_RHMFRadarSensorDistance : 52|5@0+ (5,25) [25|160] "Cm"  ICC_ICE
 SG_ RADAR_1_LHMFRadarSensorDistance : 63|5@0+ (5,25) [25|160] "Cm"  ICC_ICE
 SG_ RADAR_1_AudibleBeepRate : 58|3@0+ (1,0) [0|7] ""  ICC_ICE

BO_ 1234 FRZCU_11: 32 CGW
 SG_ FRZCU_FRSeatHeiFb : 23|7@0+ (1,-1) [-1|100] "%"  ICC_ICE,BBCM,PCL
 SG_ FRZCU_FRSeatLvlFb : 31|7@0+ (1,-1) [-1|100] "%"  ICC_ICE,BBCM,PCL
 SG_ FRZCU_FRSeatBackAgFb : 39|7@0+ (1,-1) [-1|100] "%"  ICC_ICE,BBCM,PCL
 SG_ FRZCU_FRSeatLegSpprtFb : 47|7@0+ (1,-1) [-1|100] "%"  ICC_ICE
 SG_ FRZCU_FRWinSts : 55|3@0+ (1,0) [0|7] ""  ICC_ICE
 SG_ FRZCU_RRWinSts : 52|3@0+ (1,0) [0|7] ""  ICC_ICE
 SG_ FRZCU_FRSeatLegRestAngleFb : 62|7@0+ (1,-1) [-1|100] "%"  ICC_ICE
 SG_ FRZCU_FRSeatCushFb : 86|7@0+ (1,-1) [-1|100] "%"  ICC_ICE,BBCM,PCL
 SG_ FRZCU_FRSeatNeedMemory : 105|2@0+ (1,0) [0|3] ""  ICC_ICE
 SG_ FRZCU_FRMemoryFb : 107|2@0+ (1,0) [0|3] ""  ICC_ICE
 SG_ FRZCU_FRRecoverFb : 109|2@0+ (1,0) [0|3] ""  ICC_ICE
 SG_ FRZCU_EasyEntryExitFb : 111|2@0+ (1,0) [0|3] ""  ICC_ICE
 SG_ FRZCU_EnjoyableSeatWarning : 113|2@0+ (1,0) [0|3] ""  ICC_ICE
 SG_ FRZCU_EnjoyableSeatSts : 115|2@0+ (1,0) [0|3] ""  ICC_ICE
 SG_ SeatHeatLevelsFR_4D2h : 127|3@0+ (1,0) [0|7] ""  ICC_ICE
 SG_ SeatVentLevelsFR_4D2h : 123|2@0+ (1,0) [0|3] ""  ICC_ICE
 SG_ SeatHeatLevelsRR : 151|3@0+ (1,0) [0|7] ""  ICC_ICE
 SG_ SeatVentLevelsRR : 147|2@0+ (1,0) [0|3] ""  ICC_ICE
 SG_ NonPwrOffSwtSts_4D2h : 157|2@0+ (1,0) [0|3] ""  ICC_ICE
 SG_ FRZCU_FRSeatFoldFb : 167|7@0+ (1,-1) [-1|100] "%"  ICC_ICE

BO_ 517 MFSR_1: 8 CGW
 SG_ MFSR_UP_SW : 17|2@0+ (1,0) [0|3] ""  ICC_ICE
 SG_ MFSR_DW_SW : 19|2@0+ (1,0) [0|3] ""  ICC_ICE
 SG_ MFSR_Left_SW : 21|2@0+ (1,0) [0|3] ""  ICC_ICE
 SG_ MFSR_Right_SW : 23|2@0+ (1,0) [0|3] ""  ICC_ICE
 SG_ MFSR_OK_SW : 25|2@0+ (1,0) [0|3] ""  ICC_ICE
 SG_ MFSR_MENU_SW : 27|2@0+ (1,0) [0|3] ""  ICC_ICE
 SG_ MFSR_Voice_SW : 47|2@0+ (1,0) [0|3] ""  ICC_ICE
 SG_ MFSR_Customize : 51|2@0+ (1,0) [0|3] ""  ICC_ICE

BO_ 1096 TMS_11: 32 CGW
 SG_ TMS_AirPurgeReminderSts : 17|2@0+ (1,0) [0|3] ""  ICC_ICE
 SG_ TMS_BT_Reduce_Wind_SpeedSts : 23|2@0+ (1,0) [0|3] ""  ICC_ICE
 SG_ TMS_First_BlowingSts : 21|2@0+ (1,0) [0|3] ""  ICC_ICE
 SG_ TMS_CirculationInTunnelsSts : 19|2@0+ (1,0) [0|3] ""  ICC_ICE
 SG_ TMS_crosscountry_coolingSts : 29|2@0+ (1,0) [0|3] ""  ICC_ICE
 SG_ TMS_ParkingAirConditioningStatus : 27|2@0+ (1,0) [0|3] ""  ICC_ICE
 SG_ TMS_CoolantFillSts : 25|2@0+ (1,0) [0|3] ""  ICC_ICE
 SG_ TMS_UVC_ControlSts : 39|2@0+ (1,0) [0|3] ""  ICC_ICE
 SG_ TMS_UVC_LuminanceSts : 36|3@0+ (1,0) [0|7] ""  ICC_ICE
 SG_ TMS_ICC_Lightoff_Sts : 33|2@0+ (1,0) [0|3] ""  ICC_ICE
 SG_ TMS_ICC_Memoff_Sts : 47|2@0+ (1,0) [0|3] ""  ICC_ICE
 SG_ TMS_keepwarmSet_TemperatureSts : 55|8@0+ (1,0) [0|254] ""  ICC_ICE
 SG_ TMS_AutoDefogActiveSts : 37|1@0+ (1,0) [0|1] ""  ICC_ICE
 SG_ TMS_BiochemicalFuncSts : 95|2@0+ (1,0) [0|3] ""  ICC_ICE
 SG_ TMS_TimedVentilationSts : 97|2@0+ (1,0) [0|3] ""  ICC_ICE

BO_ 1240 TDU_9: 32 CGW
 SG_ TMS_CFSSwitchFb : 17|2@0+ (1,0) [0|3] ""  ICC_ICE
 SG_ TDU_CFSPosOneType : 21|4@0+ (1,0) [0|15] ""  ICC_ICE
 SG_ TDU_CFSPosTwoType : 27|4@0+ (1,0) [0|15] ""  ICC_ICE
 SG_ TDU_CFSPosThreeType : 31|4@0+ (1,0) [0|15] ""  ICC_ICE
 SG_ TDU_CFSRunOut : 39|4@0+ (1,0) [0|15] ""  ICC_ICE
 SG_ TMS_CFSShortWarn : 43|4@0+ (1,0) [0|15] ""  ICC_ICE
 SG_ TMS_CFSLevelSetFb : 47|4@0+ (1,0) [0|15] ""  ICC_ICE
 SG_ TMS_CFSPosSetFb : 49|2@0+ (1,0) [0|3] ""  ICC_ICE
 SG_ TMS_CFSPosOneLife : 63|8@0+ (1,0) [0|100] "%"  ICC_ICE
 SG_ TMS_CFSPosTwoLife : 87|8@0+ (1,0) [0|100] "%"  ICC_ICE
 SG_ TMS_CFSPosThreeLife : 95|8@0+ (1,0) [0|100] "%"  ICC_ICE
 SG_ TMS_PM25SwitchFb : 97|2@0+ (1,0) [0|3] ""  ICC_ICE
 SG_ TMS_ThrModeStsFb : 122|3@0+ (1,0) [0|6] ""  ICC_ICE
 SG_ TMS_ThrSetTempFb_C : 127|5@0+ (0.5,15.5) [15.5|30.5] "℃"  ICC_ICE
 SG_ TMS_ThrCLMSwitchFb : 145|2@0+ (1,0) [0|3] ""  ICC_ICE
 SG_ TMS_ThrAutoSwitchFb : 147|2@0+ (1,0) [0|3] ""  ICC_ICE
 SG_ TMS_ThrBlowSpeedLevelKeyStsFb : 151|4@0+ (1,0) [0|15] ""  ICC_ICE

BO_ 638 FRZCU_9: 16 CGW
 SG_ FRZCU_HoodSts : 45|2@0+ (1,0) [0|3] ""  ICC_ICE
 SG_ FRZCU_AuthenResult : 48|1@0+ (1,0) [0|1] ""  ICC_ICE
 SG_ FRZCU_9_PowerMode : 51|2@0+ (1,0) [0|3] ""  ICC_ICE
 SG_ FRZCU_TrunkSts : 53|2@0+ (1,0) [0|3] ""  ICC_ICE
 SG_ FRZCU_HandleSwitchStsFL : 57|2@0+ (1,0) [0|3] ""  ICC_ICE,BBCM,PCL
 SG_ FRZCU_HandleSwitchStsFR : 59|2@0+ (1,0) [0|3] ""  ICC_ICE,BBCM,PCL
 SG_ FRZCU_HandleSwitchStsRR : 61|2@0+ (1,0) [0|3] ""  ICC_ICE
 SG_ FRZCU_HandleSwitchStsRL : 63|2@0+ (1,0) [0|3] ""  ICC_ICE
 SG_ SeatLength_target_Passenger : 87|4@0+ (1,0) [0|15] ""  ICC_ICE
 SG_ SeatBackrest_target_Passenger : 95|5@0+ (1,0) [0|15] ""  ICC_ICE
 SG_ FRZCU_TrunkLockSts : 89|2@0+ (1,0) [0|3] ""  ICC_ICE
 SG_ FRZCU_HoodLockSts : 103|2@0+ (1,0) [0|3] ""  ICC_ICE
 SG_ FrontBackSpeedAdj_Cmd : 101|3@0+ (1,0) [0|7] ""  ICC_ICE
 SG_ FRZCU_GloveboxSW : 98|1@0+ (1,0) [0|1] ""  ICC_ICE
 SG_ FRZCU_FRReleaseLockSts : 111|3@0+ (1,0) [0|7] ""  ICC_ICE
 SG_ FRZCU_RRReleaseLockSts : 108|3@0+ (1,0) [0|7] ""  ICC_ICE
 SG_ FRZCU_PELockInKeyWarning : 105|1@0+ (1,0) [0|1] ""  ICC_ICE
 SG_ FRZCU_PowerOFFWarning : 118|1@0+ (1,0) [0|1] ""  ICC_ICE
 SG_ FRZCU_KeylessWarning : 116|1@0+ (1,0) [0|1] ""  ICC_ICE
 SG_ FRZCU_OTAPwrDwnReqFb : 113|2@0+ (1,0) [0|3] ""  ICC_ICE
 SG_ FRZCU_OTAPwrOnReqFb : 127|2@0+ (1,0) [0|3] ""  ICC_ICE

BO_ 949 PEPS_1: 16 CGW
 SG_ PEPS_InformationSource : 23|2@0+ (1,0) [0|3] ""  ICC_ICE,BBCM,PCL,PLG
 SG_ PEPS_OrderInformation : 21|4@0+ (1,0) [0|15] ""  ICC_ICE,BBCM,PCL,PLG
 SG_ PEPS_IDInformation : 31|4@0+ (1,0) [0|15] ""  ICC_ICE,BBCM,PCL,PLG
 SG_ PEPS_KeySts : 27|3@0+ (1,0) [0|7] ""  ICC_ICE,BBCM,PCL,PLG
 SG_ PEPS_ETRUnLockReq : 39|2@0+ (1,0) [0|3] ""  ICC_ICE,BBCM,PCL,PLG

BO_ 1028 PEPS_2: 16 CGW
 SG_ PEPS_WelcomeON : 17|2@0+ (1,0) [0|3] ""  ICC_ICE,BBCM,PCL
 SG_ PEPS_VehicleSearchReq : 19|2@0+ (1,0) [0|3] ""  ICC_ICE,BBCM,PCL
 SG_ PEPS_SATOReminder : 21|2@0+ (1,0) [0|3] ""  ICC_ICE,BBCM,PCL
 SG_ PEPS_PLGUnlockReq : 23|2@0+ (1,0) [0|3] ""  ICC_ICE,BBCM,PCL
 SG_ PEPS_RKETrunkSts : 25|2@0+ (1,0) [0|3] ""  ICC_ICE,BBCM,PCL
 SG_ PEPS_SSBInhibitCWCSts : 27|2@0+ (1,0) [0|3] ""  ICC_ICE,BBCM,PCL
 SG_ PEPS_WirelessChargingCtrSts : 29|2@0+ (1,0) [0|3] ""  ICC_ICE,BBCM,PCL
 SG_ PEPS_EmgyShutdown : 35|2@0+ (1,0) [0|3] ""  ICC_ICE,BBCM,PCL
 SG_ PEPS_SSBInputFailure : 37|2@0+ (1,0) [0|3] ""  ICC_ICE,BBCM,PCL
 SG_ PEPS_SmartSystemWarning1_1 : 39|2@0+ (1,0) [0|3] ""  ICC_ICE,BBCM,PCL
 SG_ PEPS_SmartSystemWarning2_2 : 41|2@0+ (1,0) [0|3] ""  ICC_ICE,BBCM,PCL
 SG_ PEPS_SmartSystemWarning3_1 : 43|2@0+ (1,0) [0|3] ""  ICC_ICE,BBCM,PCL
 SG_ PEPS_SmartSystemWarning3_2 : 45|2@0+ (1,0) [0|3] ""  ICC_ICE,BBCM,PCL
 SG_ PEPS_SmartSystemWarning4_2 : 47|2@0+ (1,0) [0|3] ""  ICC_ICE,BBCM,PCL
 SG_ PEPS_SmartSystemWarning4_3 : 49|2@0+ (1,0) [0|3] ""  ICC_ICE,BBCM,PCL
 SG_ PEPS_SystemWarning : 51|2@0+ (1,0) [0|3] ""  ICC_ICE,BBCM,PCL
 SG_ PEPS_BLTKeyPESts : 53|2@0+ (1,0) [0|3] ""  ICC_ICE,BBCM,PCL

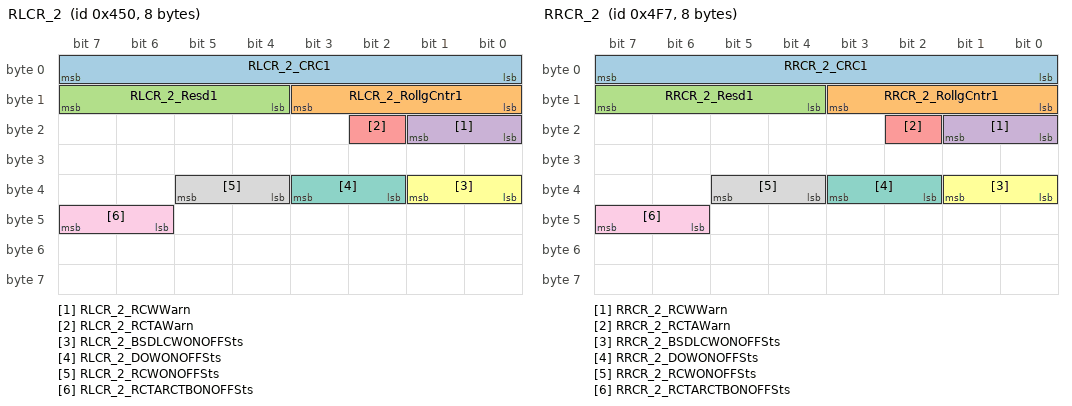
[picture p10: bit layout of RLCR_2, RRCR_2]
BO_ 1104 RLCR_2: 8 CGW
 SG_ RLCR_2_CRC1 : 7|8@0+ (1,0) [0|255] ""  ICC_ICE
 SG_ RLCR_2_RollgCntr1 : 11|4@0+ (1,0) [0|14] ""  ICC_ICE
 SG_ RLCR_2_Resd1 : 15|4@0+ (1,0) [0|15] ""  ICC_ICE
 SG_ RLCR_2_RCWWarn : 17|2@0+ (1,0) [0|3] ""  ICC_ICE
 SG_ RLCR_2_RCTAWarn : 18|1@0+ (1,0) [0|1] ""  ICC_ICE
 SG_ RLCR_2_BSDLCWONOFFSts : 33|2@0+ (1,0) [0|3] ""  ICC_ICE
 SG_ RLCR_2_DOWONOFFSts : 35|2@0+ (1,0) [0|3] ""  ICC_ICE
 SG_ RLCR_2_RCWONOFFSts : 37|2@0+ (1,0) [0|3] ""  ICC_ICE
 SG_ RLCR_2_RCTARCTBONOFFSts : 47|2@0+ (1,0) [0|3] ""  ICC_ICE

BO_ 1271 RRCR_2: 8 CGW
 SG_ RRCR_2_CRC1 : 7|8@0+ (1,0) [0|255] ""  ICC_ICE
 SG_ RRCR_2_RollgCntr1 : 11|4@0+ (1,0) [0|14] ""  ICC_ICE
 SG_ RRCR_2_Resd1 : 15|4@0+ (1,0) [0|15] ""  ICC_ICE
 SG_ RRCR_2_RCWWarn : 17|2@0+ (1,0) [0|3] ""  ICC_ICE
 SG_ RRCR_2_RCTAWarn : 18|1@0+ (1,0) [0|1] ""  ICC_ICE
 SG_ RRCR_2_BSDLCWONOFFSts : 33|2@0+ (1,0) [0|3] ""  ICC_ICE
 SG_ RRCR_2_DOWONOFFSts : 35|2@0+ (1,0) [0|3] ""  ICC_ICE
 SG_ RRCR_2_RCWONOFFSts : 37|2@0+ (1,0) [0|3] ""  ICC_ICE
 SG_ RRCR_2_RCTARCTBONOFFSts : 47|2@0+ (1,0) [0|3] ""  ICC_ICE

BO_ 587 ONEBOX_4: 48 CGW
 SG_ ONEBOX_4_LHFWheelSpeedRPM : 23|16@0+ (0.0625,0) [0|4095.875] "rpm"  ICC_ICE
 SG_ ONEBOX_4_RHFWheelSpeedRPM : 39|16@0+ (0.0625,0) [0|4095.875] "rpm"  ICC_ICE
 SG_ LHRWheelSpeedRPM : 55|16@0+ (0.0625,0) [0|4095.875] "rpm"  ICC_ICE
 SG_ RHRWheelSpeedRPM : 87|16@0+ (0.0625,0) [0|4095.875] "rpm"  ICC_ICE
 SG_ LHRPulseCounterFailSts : 106|1@0+ (1,0) [0|1] ""  ICC_ICE
 SG_ LHRPulseCounter : 103|13@0+ (1,0) [0|8191] "pulse"  ICC_ICE
 SG_ RHRPulseCounterFailSts : 122|1@0+ (1,0) [0|1] ""  ICC_ICE
 SG_ RHRPulseCounter : 119|13@0+ (1,0) [0|8191] "pulse"  ICC_ICE
 SG_ RHFPulseCounterFailSts : 154|1@0+ (1,0) [0|1] ""  ICC_ICE
 SG_ RHFPulseCounter : 151|13@0+ (1,0) [0|8191] "pulse"  ICC_ICE
 SG_ LHFPulseCounterFailSts : 170|1@0+ (1,0) [0|1] ""  ICC_ICE
 SG_ LHFPulseCounter : 167|13@0+ (1,0) [0|8191] "pulse"  ICC_ICE
 SG_ LHFWheelDriveDirection : 187|3@0+ (1,0) [0|7] ""  ICC_ICE
 SG_ RHFWheelDriveDirection : 219|3@0+ (1,0) [0|7] ""  ICC_ICE
 SG_ LHRWheelDriveDirection : 235|3@0+ (1,0) [0|7] ""  ICC_ICE
 SG_ RHRWheelDriveDirection : 251|3@0+ (1,0) [0|7] ""  ICC_ICE

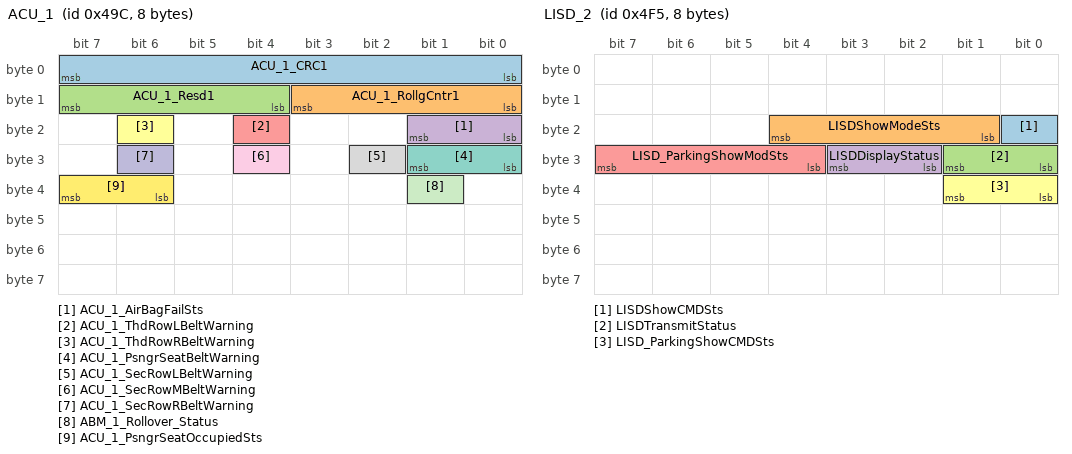
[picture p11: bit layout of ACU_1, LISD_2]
BO_ 1180 ACU_1: 8 CGW
 SG_ ACU_1_CRC1 : 7|8@0+ (1,0) [0|255] ""  ICC_ICE
 SG_ ACU_1_RollgCntr1 : 11|4@0+ (1,0) [0|14] ""  ICC_ICE
 SG_ ACU_1_Resd1 : 15|4@0+ (1,0) [0|15] ""  ICC_ICE
 SG_ ACU_1_AirBagFailSts : 17|2@0+ (1,0) [0|3] ""  ICC_ICE
 SG_ ACU_1_ThdRowLBeltWarning : 20|1@0+ (1,0) [0|1] ""  ICC_ICE
 SG_ ACU_1_ThdRowRBeltWarning : 22|1@0+ (1,0) [0|1] ""  ICC_ICE
 SG_ ACU_1_PsngrSeatBeltWarning : 25|2@0+ (1,0) [0|3] ""  ICC_ICE
 SG_ ACU_1_SecRowLBeltWarning : 26|1@0+ (1,0) [0|1] ""  ICC_ICE
 SG_ ACU_1_SecRowMBeltWarning : 28|1@0+ (1,0) [0|1] ""  ICC_ICE
 SG_ ACU_1_SecRowRBeltWarning : 30|1@0+ (1,0) [0|1] ""  ICC_ICE
 SG_ ABM_1_Rollover_Status : 33|1@0+ (1,0) [0|1] ""  ICC_ICE
 SG_ ACU_1_PsngrSeatOccupiedSts : 39|2@0+ (1,0) [0|3] ""  ICC_ICE,BBCM,PCL

BO_ 1269 LISD_2: 8 CGW
 SG_ LISDShowCMDSts : 16|1@0+ (1,0) [0|1] ""  ICC_ICE
 SG_ LISDShowModeSts : 20|4@0+ (1,0) [0|15] ""  ICC_ICE
 SG_ LISDTransmitStatus : 25|2@0+ (1,0) [0|3] ""  ICC_ICE
 SG_ LISDDisplayStatus : 27|2@0+ (1,0) [0|3] ""  ICC_ICE
 SG_ LISD_ParkingShowModSts : 31|4@0+ (1,0) [0|15] ""  ICC_ICE
 SG_ LISD_ParkingShowCMDSts : 33|2@0+ (1,0) [0|3] ""  ICC_ICE

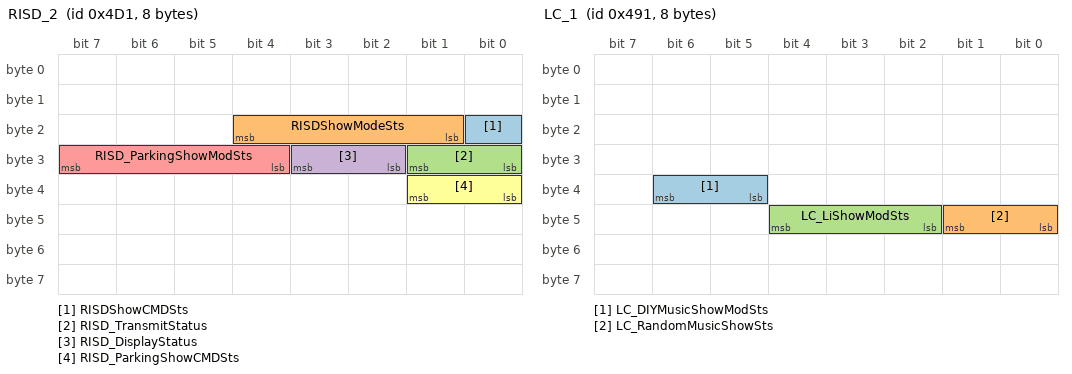
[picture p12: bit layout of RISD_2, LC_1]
BO_ 1233 RISD_2: 8 CGW
 SG_ RISDShowCMDSts : 16|1@0+ (1,0) [0|1] ""  ICC_ICE
 SG_ RISDShowModeSts : 20|4@0+ (1,0) [0|15] ""  ICC_ICE
 SG_ RISD_TransmitStatus : 25|2@0+ (1,0) [0|3] ""  ICC_ICE
 SG_ RISD_DisplayStatus : 27|2@0+ (1,0) [0|3] ""  ICC_ICE
 SG_ RISD_ParkingShowModSts : 31|4@0+ (1,0) [0|15] ""  ICC_ICE
 SG_ RISD_ParkingShowCMDSts : 33|2@0+ (1,0) [0|3] ""  ICC_ICE

BO_ 1169 LC_1: 8 CGW
 SG_ LC_DIYMusicShowModSts : 38|2@0+ (1,0) [0|3] ""  ICC_ICE
 SG_ LC_RandomMusicShowSts : 41|2@0+ (1,0) [0|3] ""  ICC_ICE
 SG_ LC_LiShowModSts : 44|3@0+ (1,0) [0|7] ""  ICC_ICE

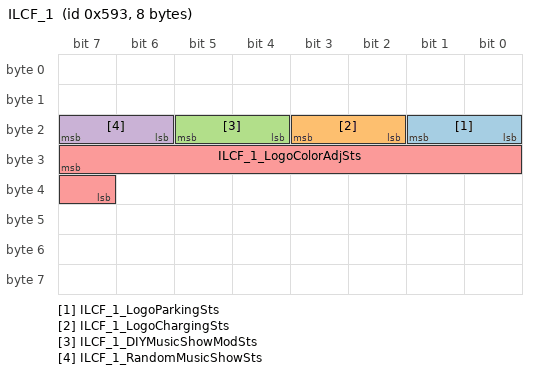
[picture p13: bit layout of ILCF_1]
BO_ 1427 ILCF_1: 8 CGW
 SG_ ILCF_1_LogoParkingSts : 17|2@0+ (1,0) [0|3] ""  ICC_ICE
 SG_ ILCF_1_LogoChargingSts : 19|2@0+ (1,0) [0|3] ""  ICC_ICE
 SG_ ILCF_1_DIYMusicShowModSts : 21|2@0+ (1,0) [0|3] ""  ICC_ICE
 SG_ ILCF_1_RandomMusicShowSts : 23|2@0+ (1,0) [0|3] ""  ICC_ICE
 SG_ ILCF_1_LogoColorAdjSts : 31|9@0+ (1,0) [0|511] ""  ICC_ICE

BO_ 821 ADS_5: 48 CGW
 SG_ ADS_5_CRC1 : 7|8@0+ (1,0) [0|255] ""  ICC_ICE
 SG_ ADS_5_RollgCntr1 : 11|4@0+ (1,0) [0|14] ""  ICC_ICE
 SG_ ADS_5_Resd1 : 15|4@0+ (1,0) [0|15] ""  ICC_ICE
 SG_ ADS_5_ILOASts : 18|3@0+ (1,0) [0|7] ""  ICC_ICE
 SG_ ADS_5_ICAQuitReason : 21|3@0+ (1,0) [0|7] ""  ICC_ICE
 SG_ ADS_5_ISLISt : 23|2@0+ (1,0) [0|3] ""  ICC_ICE
 SG_ ADS_5_ILOATextInfo : 28|2@0+ (1,0) [0|3] ""  ICC_ICE
 SG_ ADS_5_ILOAActdirection : 30|2@0+ (1,0) [0|3] ""  ICC_ICE
 SG_ ADS_5_LKS_warning : 31|1@0+ (1,0) [0|1] ""  ICC_ICE
 SG_ ADS_5_ISLIOverSpeedWarn : 34|2@0+ (1,0) [0|3] ""  ICC_ICE
 SG_ ADS_5_ISLISpeedLimitSign : 26|8@0+ (1,0) [0|255] ""  ICC_ICE
 SG_ ADS_5_EgoLeftLineHeatgAg : 32|9@0+ (0.004,-1.02) [-1.02|1.02] "Rad"  ICC_ICE
 SG_ ADS_5_EgoLeLineID : 51|1@0+ (1,0) [0|1] ""  ICC_ICE
 SG_ ADS_5_EgoLeLineColor : 53|2@0+ (1,0) [0|3] ""  ICC_ICE
 SG_ ADS_5_EgoLeLineTyp : 55|2@0+ (1,0) [0|3] ""  ICC_ICE
 SG_ ADS_5_EgoLeLineHozlDst : 48|9@0+ (0.1,-25) [-25|25] "m"  ICC_ICE
 SG_ ADS_5_CRC2 : 71|8@0+ (1,0) [0|255] ""  ICC_ICE
 SG_ ADS_5_RollgCntr2 : 75|4@0+ (1,0) [0|14] ""  ICC_ICE
 SG_ ADS_5_Resd2 : 79|4@0+ (1,0) [0|15] ""  ICC_ICE
 SG_ ADS_5_NeborLeLineID : 89|1@0+ (1,0) [0|1] ""  ICC_ICE
 SG_ ADS_5_NeborLeLineColor : 91|2@0+ (1,0) [0|3] ""  ICC_ICE
 SG_ ADS_5_NeborLeLineTyp : 93|2@0+ (1,0) [0|3] ""  ICC_ICE
 SG_ ADS_5_EgoLeLineCrvt : 87|10@0+ (6E-05,-0.0156) [-0.0156|0.0156] "1/m"  ICC_ICE
 SG_ ADS_5_NeborLeLineHozlDst : 88|9@0+ (0.1,-25) [-25|25] "m"  ICC_ICE
 SG_ ADS_5_NeborRiLineID : 113|1@0+ (1,0) [0|1] ""  ICC_ICE
 SG_ ADS_5_NeborRiLineColor : 115|2@0+ (1,0) [0|3] ""  ICC_ICE
 SG_ ADS_5_NeborRiLineTyp : 117|2@0+ (1,0) [0|3] ""  ICC_ICE
 SG_ ADS_5_NeborLeLineCrvt : 111|10@0+ (6E-05,-0.0156) [-0.0156|0.0156] "1/m"  ICC_ICE
 SG_ ADS_5_NeborRiLineHozlDst : 112|9@0+ (0.1,-25) [-25|25] "m"  ICC_ICE
 SG_ ADS_5_CRC3 : 135|8@0+ (1,0) [0|255] ""  ICC_ICE
 SG_ ADS_5_RollgCntr3 : 139|4@0+ (1,0) [0|14] ""  ICC_ICE
 SG_ ADS_5_Resd3 : 143|4@0+ (1,0) [0|15] ""  ICC_ICE
 SG_ ADS_5_ELKSettingSt : 153|2@0+ (1,0) [0|3] ""  ICC_ICE
 SG_ ADS_5_LDWLDPSnvtySet : 155|2@0+ (1,0) [0|3] ""  ICC_ICE
 SG_ ADS_5_LDWWarnType : 157|2@0+ (1,0) [0|3] ""  ICC_ICE
 SG_ ADS_5_NeborRiLineCrvt : 151|10@0+ (6E-05,-0.0156) [-0.0156|0.0156] "1/m"  ICC_ICE
 SG_ ADS_5_IESSwtSet : 161|2@0+ (1,0) [0|3] ""  ICC_ICE
 SG_ ADS_5_IHCSettingSt : 163|2@0+ (1,0) [0|3] ""  ICC_ICE
 SG_ ADS_5_ISLIWarningMod : 165|2@0+ (1,0) [0|3] ""  ICC_ICE
 SG_ ADS_5_ICAEnableBtnSts : 167|2@0+ (1,0) [0|3] ""  ICC_ICE
 SG_ ADS_5_FCM_Camera_textinfo : 175|2@0+ (1,0) [0|3] ""  ICC_ICE
 SG_ ADS_5_EgoRiLineID : 183|2@0+ (1,0) [0|1] ""  ICC_ICE
 SG_ ADS_5_EgoRiLineTyp : 169|2@0+ (1,0) [0|3] ""  ICC_ICE
 SG_ ADS_5_EgoRiLineColor : 181|2@0+ (1,0) [0|3] ""  ICC_ICE
 SG_ ADS_5_EgoRiLineHozlDst : 179|9@0+ (0.1,-25) [-25|25] "m"  ICC_ICE
 SG_ ADS_5_CRC4 : 199|8@0+ (1,0) [0|255] ""  ICC_ICE
 SG_ ADS_5_RollgCntr4 : 203|4@0+ (1,0) [0|14] ""  ICC_ICE
 SG_ ADS_5_Resd4 : 207|4@0+ (1,0) [0|15] ""  ICC_ICE
 SG_ ADS_5_EgoRightLineHeatgAg : 215|9@0+ (0.004,-1.02) [-1.02|1.02] "Rad"  ICC_ICE
 SG_ ADS_5_EgoRiLineCrvt : 222|10@0+ (6E-05,-0.0156) [-0.0156|0.0156] "1/m"  ICC_ICE
 SG_ ADS_5_NeborLeftLineHeatgAg : 228|9@0+ (0.004,-1.02) [-1.02|1.02] "Rad"  ICC_ICE
 SG_ ADS_5_NeborRightLineHeatgAg : 235|9@0+ (0.004,-1.02) [-1.02|1.02] "Rad"  ICC_ICE

BO_TX_BU_ 2015 : ICC_ICE,CGW;
CM_ SG_ 1211 FLZCU_FLSeatHeiFb "主驾座椅高度调节目标位置
0x0:Not active";
CM_ SG_ 1211 FLZCU_FLSeatLvlFb "主驾座椅水平调节目标值
0x0:Not active";
CM_ SG_ 1211 FLZCU_FLSeatBackAgFb "主驾座椅靠背角度调节目标值
0x0:Not active";
CM_ SG_ 1211 FLZCU_FLSeatCushFb "主驾座椅坐垫角度调节目标值
0x0:Not active";
CM_ SG_ 1211 FLZCU_FLSeatLegSpprtFb "主驾座椅腿托
0x0:Not active";
CM_ SG_ 1211 FLZCU_SeatNeedMemory "主驾座椅记忆弹框请求";
CM_ SG_ 1211 FLZCU_MemoryFb "记忆保存状态";
CM_ SG_ 1211 FLZCU_RecoverFb "记忆恢复状态";
CM_ SG_ 1211 FLZCU_DriverSeatMovFailCause "主驾调节失败原因
0x0：Not active
0x1：座椅未学习
0x2：触发防夹（调节过程中任意一轴触发防夹）
0x3：硬开关未释放（所有开关）
0x4：非P档
0x5：电机线路故障（开路、短路、霍尔丢失）
0x6：优先级不满足";
CM_ SG_ 1211 FLZCU_CurrSeatMemoryPos "主驾记忆坐姿位置反馈";
CM_ SG_ 1072 LHFdoorSts_430h "主驾门状态（PT3阶段可发）";
CM_ SG_ 1072 LHFSeatBeltSW_430h "安全带检测开关，0为未插入，1为插入";
CM_ SG_ 1072 TrunkSts_430h "（由27E拆帧)";
CM_ SG_ 1072 RLWinPosn_430h "Rear Left Window Position车窗（当前可发）";
CM_ SG_ 1072 SeatHeatLevelsFL_430h "捷途需要改9档";
CM_ SG_ 1072 SeatHeatLevelsRL_430h "捷途需要改9档";
CM_ SG_ 1072 SeatVentLevelsFL_430h "捷途需要改9档";
CM_ SG_ 1072 SeatVentLevelsRL_430h "捷途需要改9档";
CM_ SG_ 1072 FLWinPosn_430h "Front Left Window Position车窗（当前可发）";
CM_ SG_ 1072 FLZCU_FrontWiperMaintenanceSts "前雨刮维修模式开关状态反馈（当前可发）";
CM_ SG_ 1072 FLZCU_RearWiperMaintenanceSts "后雨刮维修模式开关状态反馈（当前可发）";
CM_ SG_ 1043 EBS_U_BATT "Current measured battery voltage, max value is 18V.Invalid Raw Value:16383.";
CM_ SG_ 1022 FLZCU_CarMode "整车模式";
CM_ SG_ 1022 FLZCU_SteerWhlposSts "管柱电机运行状态
0x0:不工作
0x1:伸长调节中
0x2:缩短调节中
0x3:角度上调中
0x4:角度下调中";
CM_ SG_ 1022 FLZCU_MedStatusFb "冥想模式状态反馈";
CM_ SG_ 1022 FLZCU_MedFailCause "冥想模式开启失败 原因反馈
0x0:Not Active 
0x1:档位非P 档 
0x2:车速≠0km/h 
0x3:前舱盖未关 
0x4:后背门未关 
0x5:左前门未关 
0x6:右前门未关 
0x7:左后门未关 
0x8:右后门未关 
0x9:低压电池电压低，不满足开启条件 
0xA:高压电池电量低，不满足开启条件 
0xB:制动踏板被踩下，不满足开启条件
0xC:电源档位非Comfortable档，不满足开启条件(新增)";
CM_ SG_ 1022 FLZCU_MedAreaFb "冥想模式开启区域设置反馈";
CM_ SG_ 1022 FLZCU_MedClosePrompt "冥想模式关闭提示信号
0x0:Not Active
0x1:低压电池电量低，关闭冥想模式 
0x2:高压电池电量低，关闭冥想模式";
CM_ SG_ 1022 FLZCU_NapArea2Fb "小憩模式开启区域2设置反馈";
CM_ SG_ 1022 FLZCU_2LSeatLvltargetCmd "小憩模式二排左前后设置
0x0:Not active";
CM_ SG_ 1022 FLZCU_2LSeatBackAgtargetCmd "小憩模式二排左靠背设置
0x0:Not active";
CM_ SG_ 1022 FLZCU_2LSeatLegSpprttargetCmd "小憩模式二排左腿托设置
0x0:Not active";
CM_ SG_ 1022 FLZCU_FLWinThermalStatus "左前车窗热保护状态
0：未触发热保护
1：热保护触发中";
CM_ SG_ 1022 FLZCU_RLWinThermalStatus "左后车窗热保护状态
0：未触发热保护
1：热保护触发中";
CM_ SG_ 1022 FLZCU_MonoAmbLigSts "单色氛围灯状态";
CM_ SG_ 1022 FLZCU_LogoChargingSts "前LOGO充电灯效开关状态反馈";
CM_ SG_ 1022 FLZCU_2RSeatLvltargetCmd "小憩模式二排右前后设置
0x0:Not active";
CM_ SG_ 1022 FLZCU_2RSeatBackAgtargetCmd "小憩模式二排右靠背设置
0x0:Not active";
CM_ SG_ 1022 FLZCU_2RSeatLegSpprttargetCmd "小憩模式二排右腿托设置
0x0:Not active";
CM_ SG_ 1022 FLZCU_SeatVentLvlFL2 "主驾座椅通风状态--捷途使用
9档通风给TBOX和ICC";
CM_ SG_ 1022 FLZCU_SeatVentLvlRL2 "二排左侧座椅通风状态--捷途使用
9档通风给TBOX和ICC";
CM_ SG_ 1022 FLZCU_SeatHeatLvlFL2 "主驾座椅加热状态--捷途使用
9档加热给TBOX和ICC";
CM_ SG_ 1022 FLZCU_SeatHeatLvlRL2 "二排左侧座椅加热状态--捷途使用
9档加热给TBOX和ICC";
CM_ SG_ 1022 FLZCU_FLSitPosnSts "主驾座椅记忆位置反馈（含后视镜、管柱）
车机座椅记忆页面有三个位置显示，需新增该信号";
CM_ SG_ 1022 FLZCU_SteerOverHeatWarn "管柱热保护提醒";
CM_ SG_ 1022 FLZCU_FLogolightInhibitSts "前LOGO灯禁止状态（D01P增加 高法规地区不允许亮）";
CM_ SG_ 1020 BMSH_MaxChgPwrPeak "Maximum Charge Power Peak";
CM_ SG_ 1020 BMSH_MaxDchgPwrPeak "Maximum Discharge Power Peak";
CM_ SG_ 1020 FMCU_8_ISGF_SpdAct "ISG motor actual speed前发电机实际转速";
CM_ SG_ 1020 RMCU_1_Speed "RMCU motor actual speed后驱动电机转速";
CM_ SG_ 1020 CSA_2_AllWarningInfo "EGS全部报警信号
T1C项目，EGS此信号发0x0、0x1、0x4，仪表接收";
CM_ SG_ 1020 RMCU_1_TCURErrLvlDis "TCUR故障等级";
CM_ SG_ 1020 ASU_2_sensorErrorSts "Sensor Error Status.";
CM_ SG_ 1020 ASU_2_LFHeight "Height of front left wheel.";
CM_ SG_ 1020 ASU_2_RFHeight "Height of front right wheel.";
CM_ SG_ 1020 ASU_2_LRHeight "Height of rear left wheel.";
CM_ SG_ 1020 ASU_2_RRHeight "Height of rear right wheel.";
CM_ SG_ 1020 CSA_2_WiprFrntCmd "Wiper front command for CSA..";
CM_ SG_ 1035 VCC_1_OTASts "OTA status";
CM_ SG_ 1035 VCC_1_DriveMode "驾驶模式状态信号/原股份信号
（此信号为驾驶模式真实状态反馈）";
CM_ SG_ 1136 VCC_3_CRC "Profile1A:E2E CRC (SAE J1850 CRC-8) for 32 Bytes
DataID:0x0070";
CM_ SG_ 1136 VCC_3_RollgCntr "Profile1A:E2E Rolling message counter(the maximum value of Alive counter is 14)";
CM_ SG_ 1136 VCC_3_Resd1 "Profile1A:E2E Reserved";
CM_ SG_ 1136 VCC_3_SN "Message ID信号值.当VCC成功被写入配置信息时，VCC以100ms的周期滚动发送报文，Message ID信号值从1到32循环发送。";
CM_ SG_ 1196 TDL_SwitchSts "氛围灯开关状态反馈";
CM_ SG_ 1196 TDL_ColourModeSts "氛围灯颜色模式反馈";
CM_ SG_ 1196 TDL_RhythmSwSts "氛围灯音乐律动状态反馈";
CM_ SG_ 1196 TDL_ApiluminanceSts "氛围灯亮度反馈";
CM_ SG_ 1196 TDL_VioceFunctionDone "语音唤醒功能反馈";
CM_ SG_ 1196 TDL_FlowLightSwSts "流水灯开关状态反馈";
CM_ SG_ 1196 TDL_FlowLightModeSts "流水灯模式状态反馈";
CM_ SG_ 1196 TDL_RhythmModeSts "音乐律动模式反馈";
CM_ SG_ 1196 TDL_DOWWarningSts "DOW预警开关反馈";
CM_ SG_ 1196 TDL_AssociatedDrivingModeSts "驾驶模式开关反馈";
CM_ SG_ 1196 TDL_256ColourSts "多元颜色状态反馈";
CM_ SG_ 1177 FuelTankLidSts "加油小门开关状态";
CM_ SG_ 1177 FuelTankLidLockFailureSts "加油小门门锁故障状态";
CM_ SG_ 1177 FuelTankLidSensorFailureSts "油箱门位置传感器故障信号";
CM_ SG_ 1109 CWC_1_CRC1 "Profile1A:E2E CRC (SAE J1850 CRC-8) for 8 Bytes
DataID:No ASIL requirements.Not configure
CRC Reserved.";
CM_ SG_ 1109 CWC_1_RollgCntr1 "Profile1A:E2E Rolling message counter(the maximum value of Alive counter is 14)";
CM_ SG_ 1109 CWC_1_Resd1 "Profile1A:E2E Reserved";
CM_ SG_ 1109 CWC_ChargingSts "无线充电器充电状态(DVD接收显示)
0x0: 没有充电
0x1: 充电中
0x2: 充电完成
0x3：充电故障";
CM_ SG_ 1109 CWC_workingSts "无线充电器工作状态(DVD接收显示)
0x0: 无线充电器关闭
0x1: 无线充电器打开";
CM_ SG_ 1109 CWC_Phoneforgotten "手机是否遗忘在无线充电器上(DVD接收驱动手机遗忘报警)
0x0:手机没有遗忘
0x1:手机遗忘提醒";
CM_ SG_ 1109 CWC_Phoneforgotten_ON_OFF_Sts "手机遗忘提醒功能是否打开
0x0:功能关闭
0x1:功能打开";
CM_ SG_ 1109 CWC_1_ChrgFlt "无线充电器充电故障
charge fault
0x5:NFC_card_protect_L(左舵车，右侧信号无效)";
CM_ SG_ 1109 CWC_ChargingSts_R "无线充电器充电状态(DVD接收显示)
0x0: 副驾手机没有充电
0x1: 副驾手机充电中
0x2: 副驾手机充电完成
0x3：副驾手机充电故障";
CM_ SG_ 1109 CWC_workingSts_R "无线充电器工作状态(DVD接收显示)
0x0: 副驾无线充电器关闭
0x1: 副驾无线充电器打开";
CM_ SG_ 1109 CWC_Phoneforgotten_R "手机是否遗忘在无线充电器上(DVD接收驱动手机遗忘报警)
0x0:副驾手机没有遗忘
0x1:副驾手机遗忘提醒";
CM_ SG_ 1109 CWC_Phoneforgotten_ON_OFF_Sts_R "副驾手机遗忘提醒功能是否打开
0x0:功能关闭
0x1:功能打开";
CM_ SG_ 1109 CWC_1_ChrgFlt_R "副驾手机无线充电器充电故障
charge fault
0x5:NFC_card_protect_R(右舵车，左侧信号无效)";
CM_ SG_ 1288 CurrentTimeYear_508h "GPS时间（年）";
CM_ SG_ 1288 CurrentTimeMonth_508h "GPS时间（月）";
CM_ SG_ 1288 CurrentTimeDay_508h "GPS时间（日）";
CM_ SG_ 1288 CurrentTimeHour_508h "GPS时间（时）";
CM_ SG_ 1288 CurrentTimeMinute_508h "GPS时间（分）";
CM_ SG_ 1288 CurrentTimeSecond_508h "GPS时间（秒）";
CM_ SG_ 1063 TBOX_PetmodeSwitch "宠物模式远程开关信号";
CM_ SG_ 1063 TBOX_SentinelModeSw "哨兵开关";
CM_ SG_ 1148 TBOX_GPSSwitchSts "GPS定位开关设置";
CM_ SG_ 1148 TBOX_KeepWarmStrtMin "插枪保温开始时间设置-分";
CM_ SG_ 1148 TimeToStartSentinelDayFed_47Ch "哨兵模式预约开始时间反馈(日)";
CM_ SG_ 1148 TimeToStartSentinelHourFed_47Ch "哨兵模式预约开始时间反馈(小时)";
CM_ SG_ 1148 TimeToStartSentinelMinutFed_47Ch "哨兵模式预约开始时间反馈(分钟)";
CM_ SG_ 1148 TimeToStopSentinelHourFed_47Ch "哨兵模式预约结束时间设置(小时)";
CM_ SG_ 1148 TimeToStopSentinelMinutFed_47Ch "哨兵模式预约结束时间设置（分钟）";
CM_ SG_ 1148 ReservationSentinelSts_Fed_47Ch "哨兵模式预约反馈
0x1:预约
0x2:取消预约";
CM_ SG_ 1162 ONEBOX_1_G_CRC "Profile1A:E2E CRC (SAE J1850 CRC-8) for 8 Bytes
DataID:0x0056";
CM_ SG_ 1162 ONEBOX_1_G_RollgCntr "Profile1A:E2E Rolling message counter(the maximum value of Alive counter is 14)";
CM_ SG_ 1162 VehicleSpeedVSOSig "Vehicle Speed";
CM_ SG_ 1162 VehicleSpeedVSOSigValidData "Valid check bit of the signal VehicleSpeedVSOSig";
CM_ SG_ 1162 ESPSwitchStatus "“1” means VDC and Engine Traction Control System (PTC) Function and Brake Traction Control System (BTC) Function disabled and Ignit ESP lamp.";
CM_ SG_ 1162 ABSActive "ABS Active";
CM_ SG_ 1162 ABSFailSts "ABS Fail Status";
CM_ SG_ 1162 EBDFailSts "EBD Fail Status";
CM_ SG_ 1162 TCSFailSts "After IGN OFF, this signal should be set to 0 for avoiding ICM ESP warning.";
CM_ SG_ 1162 VDCFailSts "After IGN OFF, this signal should be set to 0 for avoiding ICM ESP warning.";
CM_ SG_ 1162 TCSActive "TCS Active";
CM_ SG_ 1162 VDCActive "VDC Active";
CM_ SG_ 1162 BLRequestController "BL Request Controller";
CM_ SG_ 1202 FuelRollingCounter "Instantaneous fuel consumption pulse signal
瞬时油耗脉冲信号";
CM_ SG_ 1202 MILSts "MIL Status";
CM_ SG_ 1202 GPFWarning "This signal indicates the status of GPF warning which need ICM to  inform driver. 
0x1: Green light, may display 'GPF is full. Need  highspeed road drive to clean GPF”
0x2: Yellow light, may display'GPF is overlimited. Need to contact 4s to check and repair GPF'";
CM_ SG_ 1202 EngineSpeed "Engine Speed
PHEV上此信号发送真实转速（给BCM使用）";
CM_ SG_ 1202 EngineSpeedValidData "Valid check bit of the signal EngineSpeed";
CM_ SG_ 1202 EPCSts "EPC status";
CM_ SG_ 1202 EMS_1_G_EngineSts "Engine Status
If this value is 1, indicate that  the engine is started successfully. 
在PHEV上，此信号发送模拟的发动机状态；";
CM_ SG_ 1202 EMS_EngineSts_Actual "PHEV上，根据发动机真实的状态发送";
CM_ SG_ 1202 OilPressureWarningLamp "Oil Pressure Worning Lamp
机油压力报警灯";
CM_ SG_ 1202 Activeheatingmode "0x0:Notactive,即不显示；0x1:active,即显示，仪表显示文字提示“进入机油热机润滑模式”";
CM_ SG_ 683 FRZCU_1_ParkLightSts "位置灯状态";
CM_ SG_ 683 FRWinPosn "Front_Right_Window_Position";
CM_ SG_ 683 RRWinPosn "Rear_Right_Window_Position";
CM_ SG_ 33 ACU_3_LongitudinalAcceleration "Longitudinal acceleration signal
Sensor accuracy：0.0027680342857143 g";
CM_ SG_ 33 ACU_3_LongitudinalAccelerationVD "If hasn’t been calibrated, after initialization, this signal ‘s value is always10(invalid)";
CM_ SG_ 33 ACU_3_CrashOutputSts "Crash signal indicates the status according to bit:
If multiple directions collide at the same time, each collision flag bit representing each direction will be set to 1.For example, if left crash is superimposed with right crash, the output signal is 00001100
此信号发到ECU停止工作为止";
CM_ SG_ 1217 ASU_SysFailrSts_4C1h "ASU System failure state.";
CM_ SG_ 1217 ASU_SuspCurrentLvl_4C1h "Suspension Current High Level
0x0：无效
0x1：高3的等级
0x2：介于高3和高2的等级之间
0x3：高2等级
0x4：介于高2等级和高1等级之间
0x5：高1等级
0x6：介于高1等级和正常等级之间
0x7：正常等级
0x8：介于正常和低等级之间
0x9：低等级
0xA：介于低等级和极低等级之间
0xB：非常低的等级
0xC：便捷上下车高度等级
0xD：便捷载物高度等级
0xE~0xF：预留";
CM_ SG_ 1217 ASU_ECASSysSts_4C1h "ECAS System State";
CM_ SG_ 1217 ASU_ECASErrSts_4C1h "ECAS Error Status";
CM_ SG_ 1217 ASU_SuspTarLvl_4C1h "Suspension Target High Level
0x0：无要求
0x1：非常高的等级
0x2：高等级
0x3：正常等级
0x4：低等级
0x5：非常低的等级
0x6：方便上下车高度等级
0x7：便利装载高度等级";
CM_ SG_ 1217 ASU_EasyEntryEna_4C1h "easy Entry Enable.";
CM_ SG_ 1217 ASU_CDCErrSts_4C1h "CDC error Satus";
CM_ SG_ 1217 ASU_RearaxlewithTaildoorFb_4C1h "自动便利装载";
CM_ SG_ 1217 ASU_Overheat_warning_4C1h "空气弹簧过热保护提示";
CM_ SG_ 1217 ASU_MaintainMod_4C1h "indicate the AirSuspension is in maintain mode or not.";
CM_ SG_ 1217 ASU_drivemodeheightlevFb_4C1h "高度调节与驾驶模式关联反馈
0x0:不显示
0x1:极高（脱困）
0x2:高2
0x3:高1??
0x4:标准????
0x5:低
0x6:极低
0x7:便捷上下车
0x8:便捷装载
0x9-0xF:Reserved";
CM_ SG_ 1217 ASU_HMIFailFb_4C1h "ASU HMI failure feedback
悬架人机交互失效反馈";
CM_ SG_ 1217 ASU_AssistPass_4C1h "Assist in passing feedback
辅助通过反馈";
CM_ SG_ 1316 LHFTireTemperature "左前轮胎温度";
CM_ SG_ 1316 RHFTireTemperature "右前轮胎温度";
CM_ SG_ 1316 LHRTireTemperature "左后轮胎温度";
CM_ SG_ 1316 LHFTirePressure "左前轮胎胎压";
CM_ SG_ 1316 RHFTirePressure "右前轮胎胎压";
CM_ SG_ 1316 LHRTirePressure "左后轮胎胎压";
CM_ SG_ 1316 RHRTirePressure "左后轮胎胎压";
CM_ SG_ 1316 RHRTireTemperature "右后轮胎温度";
CM_ SG_ 1324 TirePositionWarning_LHFTire "左前方位轮胎胎压报警，含快速失压、低压、高压、高温。";
CM_ SG_ 1324 TirePositionWarning_RHFTire "右前方位轮胎胎压报警，含快速失压、低压、高压、高温。";
CM_ SG_ 1324 TirePositionWarning_LHRTire "左后方位轮胎胎压报警，含快速失压、低压、高压、高温。";
CM_ SG_ 1324 TirePositionWarning_RHRTire "右后方位轮胎胎压报警，含快速失压、低压、高压、高温。";
CM_ SG_ 1324 TirePressureWarningLampSts "胎压报警灯状态，含熄灭、闪烁（快速失压）、常亮（低压）三种状态";
CM_ SG_ 1324 TirePressureSystemFailSts "胎压系统故障";
CM_ SG_ 991 TMS_MotorLoopErrorLevel "Motor Loop Error Level
电驱回路故障等级";
CM_ SG_ 991 TMS_BatteryLoopErrorLevel "Battery Loop Error Level
电池回路故障等级";
CM_ SG_ 1188 FrontDeforestDisplaySts "前除霜工作指示灯
0x0:Off
0x1:On";
CM_ SG_ 1188 TMS_DisplayActive "空调信息显示状态
CLM检测到有面板击键或DVD控制命令，则发送active-1，DVD切屏显示空调信息；如果10秒没有检测到击键或命令，空调发_not_active-0，DVD停止显示空调信息；";
CM_ SG_ 1188 TMS_ZoneSelectionDisplaySts "Zone_Display_Status
空调温区状态显示";
CM_ SG_ 1188 TMS_AutoDisplaySts "Auto_Display_Status
空调自动状态显示";
CM_ SG_ 1188 TMS_FiltertchangeDisplaySts "Filter_replacement_reminder
滤芯重置提示";
CM_ SG_ 1188 TMS_AUTODefrostOnSts "AutoDefrost_Status
自动除雾开关状态";
CM_ SG_ 1188 TMS_AUTODefrostDisplaySts "When_the_AC_is_turned_on,_the_automatic_defogging_function_is_turned_on,_and_sends_this_signal
自动除雾工作状态";
CM_ SG_ 1188 TMS_RefInSufDispSts "Refrigerant_Insufficient_Display_Status
冷媒不足弹窗提醒";
CM_ SG_ 1188 TMS_CooltInSufDispSts "coolant_Insufficient_Display_Status
冷却液不足弹窗提醒";
CM_ SG_ 1188 TMS_DLOnOffSts "Driver_Left_On_Off_Status
主驾左出风口开关状态";
CM_ SG_ 1188 TMS_DROnOffSts "Driver_Right_On_Off_Status
主驾右出风口开关状态";
CM_ SG_ 1188 TMS_PLOnOffSts "Passenger_Left_On_Off_Status
副驾左出风口开关状态";
CM_ SG_ 1188 WorkingSts "Not_active-关闭空调
Active--打开空调
0x0:Off
0x1:On";
CM_ SG_ 1188 TMS_PROnOffSts "Passenger_Right_On_Off_Status
副驾右出风口开关状态";
CM_ SG_ 1188 TMS_DCOnOffSts "Driver_Center_On_Off_Status
中上出风口开关状态";
CM_ SG_ 1188 TMS_ACFastCool "AC_Fast_Cooling_Working_Status
空调极速降温工作状态";
CM_ SG_ 1188 TMS_ACFastHeat "AC_Fast_Heating_Working_Status
空调快速升温工作状态";
CM_ SG_ 1188 TMS_LoveRemind "Love_Remind_Working_Status
爱心提醒工作状态";
CM_ SG_ 1188 TMS_InteCleanCar "Intelligent_Clean_Car_Working_Status
智能除味工作状态";
CM_ SG_ 1188 TMS_ACVentilationSts "AC_Ventilation_Working_Status
新风系统通风状态";
CM_ SG_ 1188 TMS_AutoAirCleanSts "Auto_Air_Clean_Status
座舱自动清洁设置项状态";
CM_ SG_ 1188 PM25Sts "PM2.5_Status
0x0:Off
0x1:On";
CM_ SG_ 1188 TMS_ACModeCustomSts "AC_custom_mode_status_feedback
空调定制模式状态反馈";
CM_ SG_ 1188 TMS_ACRequestDisplaySts "AC请求指示
压缩机状态显示信号,和发给EMS的AC请求信号需区分开";
CM_ SG_ 1188 TMS_AUTODefLevelSts "AUTO_Defrost_Level_Status
自动除雾等级信息";
CM_ SG_ 1188 TMS_KeepWarm "Keep_Warm_Working_Status
恒温模式工作状态";
CM_ SG_ 1188 TMS_DSwingSts "Driver_Air_Swing_Mode_Status
主驾扫风模式显示";
CM_ SG_ 1188 TMS_PSwingSts "Passenge_rAir_Swing_Mode_Status
副驾扫风模式显示";
CM_ SG_ 1188 TMS_TuisongDispSts "Tuisong_Display_Status
不当操作体现";
CM_ SG_ 1188 TMS_SetTemperature_L_C "在单区模式下，调节左旋钮可以同时设定左右两边的温度设定。在双区模式下，左旋钮设定左区温度，右旋钮设定右区温度。
DVD未收到设定温值时，以及收到设定温值为startup_对应的1F时，DVD屏幕上温度显示区域均显示空白。";
CM_ SG_ 1188 TMS_ModeAdjustDisplaySts "Blower_Mode_Display_Status
出风模式现实状态";
CM_ SG_ 1188 TMS_CirculationModeDisplaySts "Circulation_Mode_Status
循环风门状态";
CM_ SG_ 1188 TMS_IncarTemp "Incar_Temperature
车内温度";
CM_ SG_ 1188 TMS_FliterLife "Fliter_Life
滤芯寿命";
CM_ SG_ 1188 TMS_DLSwingUpDwnWPosn "Driver_Left_Swing_Up_Down_Working_Position
主驾左上下扫风电机工作位置";
CM_ SG_ 1188 TMS_DLSwingLeRiWPosn "Driver_Left_Swing_Left_Right_Working_Position
主驾左左右扫风电机工作位置";
CM_ SG_ 1188 TMS_DRSwingUpDwnWPosn "Driver_Right_Swing_Up_Down_Working_Position
主驾右上下扫风电机工作位置";
CM_ SG_ 1188 TMS_DRSwingLeRiWPosn "Driver_Right_Swing_Left_Right_Working_Position
主驾右左右扫风电机工作位置";
CM_ SG_ 1188 TMS_PLSwingUpDwnWPosn "Passenger_Left_Swing_Up_Down_Working_Position
副驾左上下扫风电机工作位置";
CM_ SG_ 1188 TMS_PLSwingLeRiWPosn "Passenger_Left_Swing_Left_Right_Working_Position
副驾左左右扫风电机工作位置";
CM_ SG_ 1188 TMS_PRSwingUpDwnWPosn "Passenger_Right_Swing_Up_Down_Working_Position
副驾右上下扫风电机工作位置";
CM_ SG_ 1188 TMS_PRSwingLeRiWPosn "Passenger_Right_Swing_Left_Right_Working_Position
副驾右左右扫风电机工作位置";
CM_ SG_ 1188 TMS_DCSwingLeRiWPosn "Driver_Center_Swing_Left_Right_Working_Position
主驾中上左右扫风电机工作位置";
CM_ SG_ 1188 AirSwingSts "Air_Swing_Status
扫风状态显示";
CM_ SG_ 1188 BlowAdvanceOnSts "Blower_Advance_On_Status
鼓风机提前通风运行状态";
CM_ SG_ 1188 BlowDelayOffSts "Blower_Delay_Off_Status
鼓风机延迟关闭状态
0x0：开启延时
0x1：关闭延时";
CM_ SG_ 1188 TMS_PM25_ExtSts "External_PM2.5_sensor_fault_signal,_send_0X1_to_indicate_short_circuit_or_open_circuit_fault
车外PM2.5传感器故障状态";
CM_ SG_ 1188 TMS_PM25_IncarSts "Incar_PM2.5_sensor_fault_signal,_send_0X1_to_indicate_short_circuit_or_open_circuit_fault
车内PM2.5传感器故障状态";
CM_ SG_ 1188 TMS_AQS_Sts "Send_0X1_to_indicate_a_sensor_failure
AQS传感器故障状态";
CM_ SG_ 1188 PM25overproofDisplaySts "When_the_air_purification_is_not_turned_on_and_the_INcar_PM2.5_exceeds_the_upper_limit,_the_DVD_pop-up_window_prompts_the_user_to_turn_on_the_air_purification_function
PM2.5超标提醒";
CM_ SG_ 1188 AQSDisplaySts "AQS_Display_Status
AQS状态显示";
CM_ SG_ 1188 PM25AutoRunSts "When_the_air_quality_is_poor_and_the_air_purification_automatic_operation_setting_item_is_turned_on,This_signal_indicates_the_actual_working_mode_of_air_purification
PM2.5自动运行状态";
CM_ SG_ 1188 PM25AutoRunSetSts "Air_purification_automatic_operation_status_feedback
PM2.5自动运行开关状态";
CM_ SG_ 1188 FragranceWelcomeModeSts "Welcome_mode_status_feedback
迎宾模式状态反馈";
CM_ SG_ 1188 FragranceDisplaysts "Indicates_the_display_status_of_the_fragrance_interface";
CM_ SG_ 1188 TMS_AQS_Level "AQS_Level
AQS污染等级";
CM_ SG_ 1188 ACRequestCommand "AC_Request
AC请求指示";
CM_ SG_ 1188 PM25_Outcar_Level "Six_levels_of_out-car_air_quality_assessed_according_to_out-car_PM2.5
车外PM2.5等级";
CM_ SG_ 1188 PM25_Incar_Level "Six_levels_of_in-car_air_quality_assessed_according_to_in-car_PM2.5
车内PM2.5等级";
CM_ SG_ 1188 SetTemperature_L_F "SetLTemp_Fahrenheit";
CM_ SG_ 1188 SetTemperature_R_F "SetRTemp_Fahrenheit";
CM_ SG_ 1188 TMS_PM25_incar "In-car_PM2.5_value
车内PM2.5数值";
CM_ SG_ 1188 TMS_PM25_ext "OUTcar_PM2.5_value
车外PM2.5数值";
CM_ SG_ 1188 TMS_KeepWarmMemoryFb "Keep_Warm_Memory_Status
恒温模式记忆状态";
CM_ SG_ 612 CRC1_264h "Profile1A:E2E CRC (SAE J1850 CRC-8) for 8 Bytes
DataID:0x002B";
CM_ SG_ 612 RollgCntr1_264h "Profile1A:E2E Rolling message counter(the maximum value of Alive counter is 14)";
CM_ SG_ 612 FltLamp_264h "EPB故障状态
诊断和转毂测试模式时闪烁";
CM_ SG_ 612 ParkLamp_264h "EPB驻车灯状态
动态制动时闪烁";
CM_ SG_ 612 ActrSt_264h "Current state of APB actuator connected to ECU
EPB卡钳执行状态

备注：
①一边夹紧一边释放，按博世最新平台策略，一按照Applied外发。
②0x5:CompletelyReleased（IPB2.0实际按照Reserved）
③0x6:Half Applied（IPB2.0实际按照Reserved）";
CM_ SG_ 612 RWUSt_264h "EPB 后轮防抱死工作状态：
0x1:active仪表持续提示“紧急制动开启”且仪表红“P”灯闪烁，同时点亮制动尾灯，最后1帧信号显示完后结束";
CM_ SG_ 612 TextDisp_264h "EPB文本提示
备注：
0x1:驻车坡度过大，请注意安全
0x2:IPB2.0实际按照Reserved
0x3:请关好车门并系好安全带
0x4:请同时踩下制动踏板
0x5:IPB2.0新增禁止P档手动释放EPB文字提示“请切换到非P档解除电子驻车”";
CM_ SG_ 612 IPB_EPBErrorStatus "用于EPB故障显示";
CM_ SG_ 1193 AVHWarningMessage "AVH Warning Message";
CM_ SG_ 1193 CDPActive "CDP Active";
CM_ SG_ 1193 HDCFailSts "After IGN OFF, this signal should be set to 0 for avoiding ICM HDC warning.";
CM_ SG_ 1193 HDCCtrlSts "HDC Ctrl Sts";
CM_ SG_ 1193 AVHSts "Auto Hold Status";
CM_ SG_ 1193 AVHFailSts "AVH Fail Status";
CM_ SG_ 1193 FWAWarningSts "FWA:Fading warning Assist
Indicate FWA state, dashboard need warn driver";
CM_ SG_ 1197 CST_Status "CST:Comfortable stop";
CM_ SG_ 1200 SOC "Battery state of charge calculated from IBS; 101-254 reserved;Invalid Raw Value:255.";
CM_ SG_ 1061 DriverSeatMsgStr_LvlSts "0x0:关
0x1:低
0x2:中
0x3:高";
CM_ SG_ 1061 DriverSeatMsg_ModeSts "0x0:无动作
0x1:脉冲模式
0x2:波浪模式
0x3:猫步模式
0x4:单排模式
0x5:交叉模式
0x6:蝶形模式
0x7:腰部按摩模式
0x8:蛇形模式
0x9:特殊模式1
0xA:特殊模式2
0xB:特殊模式3
0xC:特殊模式4";
CM_ SG_ 1065 LeftSeatMsgStr_LvlSts "0x0:关
0x1:低
0x2:中
0x3:高";
CM_ SG_ 1065 LeftSeatMsg_ModeSts "0x0:无动作
0x1:脉冲模式
0x2:波浪模式
0x3:猫步模式
0x4:单排模式
0x5:交叉模式
0x6:蝶形模式
0x7:腰部按摩模式
0x8:蛇形模式
0x9:特殊模式1
0xA:特殊模式2
0xB:特殊模式3
0xC:特殊模式4";
CM_ SG_ 1069 PassSeatMsgStr_LvlSts "0x0:关
0x1:低
0x2:中
0x3:高";
CM_ SG_ 1069 PassSeatMsg_ModeSts "0x0:无动作
0x1:脉冲模式
0x2:波浪模式
0x3:猫步模式
0x4:单排模式
0x5:交叉模式
0x6:蝶形模式
0x7:腰部按摩模式
0x8:蛇形模式
0x9:特殊模式1
0xA:特殊模式2
0xB:特殊模式3
0xC:特殊模式4";
CM_ SG_ 1087 RightSeatMsgStr_LvlSts "0x0:关
0x1:低
0x2:中
0x3:高";
CM_ SG_ 1087 RightSeatMsg_ModeSts "0x0:无动作
0x1:脉冲模式
0x2:波浪模式
0x3:猫步模式
0x4:单排模式
0x5:交叉模式
0x6:蝶形模式
0x7:腰部按摩模式
0x8:蛇形模式
0x9:特殊模式1
0xA:特殊模式2
0xB:特殊模式3
0xC:特殊模式4";
CM_ SG_ 1189 SRF_OperateSts "天窗玻璃运行状态";
CM_ SG_ 1189 SRF_PositionSts "天窗玻璃开度值";
CM_ SG_ 1189 SRF_OverHeatProtect "天窗过热保护激活状态";
CM_ SG_ 1189 SRF_Sunshade_OperateSts "遮阳帘状运行状态";
CM_ SG_ 1189 Sunshade_OverHeatProtect "遮阳帘过热保护激活状态";
CM_ SG_ 1192 SRF_Sunroof_ActualSts "天窗的实际状态";
CM_ SG_ 1192 SRF_Sunshade_ActualSts "遮阳帘的实际状态";
CM_ SG_ 1192 SRF_Sunshade_PositionSts "遮阳帘开度值";
CM_ SG_ 1235 EPS_2_Steer_ReturnRmd_Sts "Steer  wheeel return Sts(捷途D01）";
CM_ SG_ 1235 EPS_2_Steer_ReturnRmd "Steer  wheeel return remind(捷途D01）";
CM_ SG_ 1235 EPS_2_MFS_ShakeSts "方向盘震动反馈(捷途D01）";
CM_ SG_ 1330 DWD_TextDisp "报警提示内容";
CM_ SG_ 1330 DWD_SoundIndcn "报警声音提示";
CM_ SG_ 1330 LSensorFailSts "0x0：传感器正常
0x1：传感器故障";
CM_ SG_ 1330 RSensorFailSts "0x0：传感器正常
0x1：传感器故障";
CM_ SG_ 1330 DWD_Distance "报警距离分段";
CM_ SG_ 1330 DWD_Switch "涉水雷达开关状态";
CM_ SG_ 1328 RADAR_1_RadarDetectSts "雷达探测状态
当发01，IHU_以前探头音讯蜂鸣扬声器；
当发10，IHU_以后探头音讯蜂鸣扬声器
ICM_接收此信号，但前_后探头均用一种音讯蜂鸣。";
CM_ SG_ 1328 RADAR_1_RadarWorkSts "雷达系统工作状态
1、Active:当打开PAS_开关或打到倒文件，雷达模块开始工作，此时发1，
IHU_接收到后即便用户未打开IHU，也会通过此信号自动点亮屏幕；
2、Not_Active:当不在倒档且PAS_开关关闭，或者车速大于15km_h_时，发0(Not_Active)。
3、自检提示音:雷达工作状态位由0_变化为1_时，仪表根据探头状态信息发出相应提示音，如果探头有故障则长鸣2_秒提示探头故障，如果探头没有故障则鸣叫，0.5_秒提示雷达进入工作状态。";
CM_ SG_ 1328 RADAR_1_Resd1 "Profile1A:E2E Reserved";
CM_ SG_ 1328 RADAR_1_LHRRadarSensorDistance "左后探头信息
自检故障:发送Sensor_Err
自检正常或雷达待机:发送0x3
E正常测距:距离=(D)*5+25
无障碍物:发送0x3E
0x20~0x3D:无效数据";
CM_ SG_ 1328 RADAR_1_RHMRRadarSensorDistance "右中后探头信息
自检故障:发送Sensor_Err
自检正常或雷达待机:发送0x3
E正常测距:距离=(D)*5+25
无障碍物:发送0x3E
0x20~0x3D:无效数据";
CM_ SG_ 1328 RADAR_1_LHMRRadarSensorDistance "左中后探头信息
自检故障:发送Sensor_Err
自检正常或雷达待机:发送0x3
E正常测距:距离=(D)*5+25
无障碍物:发送0x3E
0x20~0x3D:无效数据";
CM_ SG_ 1328 RADAR_1_RHRRadarSensorDistance "右后探头信息
自检故障:发送Sensor_Err
自检正常或雷达待机:发送0x3
E正常测距:距离=(D)*5+25
无障碍物:发送0x3E
0x20~0x3D:无效数据";
CM_ SG_ 1328 RADAR_1_LHFRadarSensorDistance "左前探头信息
自检故障:发送Sensor_Err
自检正常或雷达待机:发送0x3
E正常测距:距离=(D)*5+25
无障碍物:发送0x1E
0x20~0x3D:无效数据";
CM_ SG_ 1328 RADAR_1_RHFRadarSensorDistance "右前探头信息
自检故障:发送Sensor_Err
自检正常或雷达待机:发送0x3
E正常测距:距离=(D)*5+25
无障碍物:发送0x1E
0x20~0x3D:无效数据";
CM_ SG_ 1328 RADAR_1_RHMFRadarSensorDistance "右中前探头信息
自检故障:发送Sensor_Err
自检正常或雷达待机:发送0x1E
正常测距:距离=(D)*5+25
无障碍物:发送0x1E
低配雷达(后4_探头):发送0x1E
0x1C~0x1D:无效数据";
CM_ SG_ 1328 RADAR_1_LHMFRadarSensorDistance "左中前探头信息
自检故障:发送Sensor_Err
自检正常或雷达待机:发送0x1E
正常测距:距离=(D)*5+25
无障碍物:发送0x1E
低配雷达(后4_探头):发送0x1E
0x1C~0x1D:无效数据";
CM_ SG_ 1328 RADAR_1_AudibleBeepRate "报警频率
1、自检过程或雷达待机时发送Startup
2、进入测距模式后:发送频率信息
3、自检提示音见
RadarWorkSts_详细说明";
CM_ SG_ 1234 FRZCU_FRSeatHeiFb "副驾座椅高度调节目标位置
0x0:Not active";
CM_ SG_ 1234 FRZCU_FRSeatLvlFb "副驾座椅水平调节目标值
0x0:Not active";
CM_ SG_ 1234 FRZCU_FRSeatBackAgFb "副驾座椅靠背角度调节目标值
0x0:Not active";
CM_ SG_ 1234 FRZCU_FRSeatLegSpprtFb "副驾座椅腿托
0x0:Not active";
CM_ SG_ 1234 FRZCU_FRWinSts "右前车窗运行状态反馈";
CM_ SG_ 1234 FRZCU_RRWinSts "右后车窗运行状态反馈";
CM_ SG_ 1234 FRZCU_FRSeatLegRestAngleFb "副驾座椅腿托延伸调节目标
0x0:Not active";
CM_ SG_ 1234 FRZCU_FRSeatCushFb "副驾座椅坐垫角度调节目标
0x0:Not active";
CM_ SG_ 1234 FRZCU_FRSeatNeedMemory "副驾座椅记忆弹框请求";
CM_ SG_ 1234 FRZCU_FRMemoryFb "副驾记忆保存状态";
CM_ SG_ 1234 FRZCU_FRRecoverFb "副驾记忆恢复状态";
CM_ SG_ 1234 FRZCU_EasyEntryExitFb "副驾便捷进入\离车";
CM_ SG_ 1234 FRZCU_EnjoyableSeatWarning "一键尊享警示提示";
CM_ SG_ 1234 FRZCU_EnjoyableSeatSts "一键尊享状态反馈";
CM_ SG_ 1234 SeatHeatLevelsFR_4D2h "座椅加热-副驾";
CM_ SG_ 1234 SeatVentLevelsFR_4D2h "座椅通风-副驾";
CM_ SG_ 1234 SeatHeatLevelsRR "座椅加热-二排右侧";
CM_ SG_ 1234 SeatVentLevelsRR "座椅通风-二排右侧";
CM_ SG_ 1234 NonPwrOffSwtSts_4D2h "驻车不下电设置反馈";
CM_ SG_ 1234 FRZCU_FRSeatFoldFb "副驾座椅放倒调节目标
0x0:Not active";
CM_ SG_ 517 MFSR_MENU_SW "仪表菜单(T1V)";
CM_ SG_ 517 MFSR_Voice_SW "语音唤醒";
CM_ SG_ 1096 TMS_AirPurgeReminderSts "空气净化提醒开关状态";
CM_ SG_ 1096 TMS_BT_Reduce_Wind_SpeedSts "蓝牙通话降低风速状态";
CM_ SG_ 1096 TMS_First_BlowingSts "空调启动时第一口风状态";
CM_ SG_ 1096 TMS_CirculationInTunnelsSts "隧道内循环状态";
CM_ SG_ 1096 TMS_crosscountry_coolingSts "越野散热状态";
CM_ SG_ 1096 TMS_ParkingAirConditioningStatus "驻车空调状态工作状态";
CM_ SG_ 1096 TMS_CoolantFillSts "一键除气";
CM_ SG_ 1096 TMS_UVC_ControlSts "UVC控制反馈";
CM_ SG_ 1096 TMS_UVC_LuminanceSts "UVC亮度反馈";
CM_ SG_ 1096 TMS_ICC_Lightoff_Sts "香氛氛围灯开关状态";
CM_ SG_ 1096 TMS_ICC_Memoff_Sts "香氛记忆开关状态";
CM_ SG_ 1096 TMS_keepwarmSet_TemperatureSts "恒温模式温度设置";
CM_ SG_ 1096 TMS_AutoDefogActiveSts "自动除雾开启后激活功能弹窗使用";
CM_ SG_ 1096 TMS_BiochemicalFuncSts "生化功能开关反馈";
CM_ SG_ 1096 TMS_TimedVentilationSts "大屏定时换气开关状态反馈";
CM_ SG_ 1240 TMS_CFSSwitchFb "香氛系统开关设置反馈";
CM_ SG_ 1240 TDU_CFSPosOneType "香氛位置1香型";
CM_ SG_ 1240 TDU_CFSPosTwoType "香氛位置2香型";
CM_ SG_ 1240 TDU_CFSPosThreeType "香氛位置3香型";
CM_ SG_ 1240 TDU_CFSRunOut "香氛已用完提醒";
CM_ SG_ 1240 TMS_CFSShortWarn "香氛不足提醒";
CM_ SG_ 1240 TMS_CFSLevelSetFb "香氛工作浓度";
CM_ SG_ 1240 TMS_CFSPosSetFb "香氛工作位置反馈";
CM_ SG_ 1240 TMS_CFSPosOneLife "通道一香氛寿命";
CM_ SG_ 1240 TMS_CFSPosTwoLife "通道二香氛寿命";
CM_ SG_ 1240 TMS_CFSPosThreeLife "通道三香氛寿命";
CM_ SG_ 1240 TMS_PM25SwitchFb "PM2.5状态反馈";
CM_ SG_ 1240 TMS_ThrModeStsFb "三排模式反馈";
CM_ SG_ 1240 TMS_ThrSetTempFb_C "三排温度反馈";
CM_ SG_ 1240 TMS_ThrCLMSwitchFb "三排空调状态反馈";
CM_ SG_ 1240 TMS_ThrAutoSwitchFb "空调自动状态显示";
CM_ SG_ 1240 TMS_ThrBlowSpeedLevelKeyStsFb "三排鼓风机档位";
CM_ SG_ 638 FRZCU_HoodSts "前舱盖状态";
CM_ SG_ 638 FRZCU_9_PowerMode "低压电源状态";
CM_ SG_ 638 SeatLength_target_Passenger "座椅水平位置调节";
CM_ SG_ 638 SeatBackrest_target_Passenger "座椅靠背角度调节";
CM_ SG_ 638 FrontBackSpeedAdj_Cmd "Front_Back_Speed_Adjust_Command
座椅前后调节速度信号";
CM_ SG_ 638 FRZCU_GloveboxSW "上报手套箱开关状态";
CM_ SG_ 638 FRZCU_FRReleaseLockSts "右前电释放状态
0x0:None
0x1:已释放
0x2:释放中
0x3:已复位
0x4:复位中";
CM_ SG_ 638 FRZCU_RRReleaseLockSts "右后电释放状态
0x0:None
0x1:已释放
0x2:释放中
0x3:已复位
0x4:复位中";
CM_ SG_ 638 FRZCU_PELockInKeyWarning "PE闭锁车内有钥匙提醒";
CM_ SG_ 638 FRZCU_PowerOFFWarning "电源下电提醒";
CM_ SG_ 638 FRZCU_KeylessWarning "无合法钥匙提醒";
CM_ SG_ 638 FRZCU_OTAPwrDwnReqFb "OTA_Power_Down_Request_FeedBack";
CM_ SG_ 638 FRZCU_OTAPwrOnReqFb "OTA_Power_On_Request_FeedBack";
CM_ SG_ 949 PEPS_InformationSource "To_show_the_lock/unlock_information_is_from_Smart_or_RKE_.";
CM_ SG_ 949 PEPS_OrderInformation "PEPS_do_not_add_any_additional_logic._Just_reflect_the_status_of_the_switch_state.";
CM_ SG_ 949 PEPS_KeySts "PEPS钥匙位置状态";
CM_ SG_ 949 PEPS_ETRUnLockReq "尾门靠近解锁请求";
CM_ SG_ 1028 PEPS_WelcomeON "welcome_light_request
迎宾开启请求";
CM_ SG_ 1028 PEPS_VehicleSearchReq "寻车请VehicleSearchRequest
寻车请求";
CM_ SG_ 1028 PEPS_SATOReminder "Easy_trunk_function_start_light
进入后备箱区域激活ETR功能闪灯信号";
CM_ SG_ 1028 PEPS_PLGUnlockReq "PLG解锁指令";
CM_ SG_ 1028 PEPS_RKETrunkSts "实体钥匙尾门按键";
CM_ SG_ 1028 PEPS_SSBInhibitCWCSts "OFF档时点按SSB，发送1值。
OFF档，CWC接收到SSBInhibitCWCSts=1后屏蔽无线充电功能；";
CM_ SG_ 1028 PEPS_WirelessChargingCtrSts "发送1时，PEPS处于搜索遥控钥匙的状态，无线充电功能应关闭";
CM_ SG_ 1028 PEPS_EmgyShutdown "Emergency_shut_down._If_happen_,Send_three_frame_continuous_signal_1
此信号代表发生过紧急熄火功能。如果没发生都是发0，如果发生了，连续发3帧1出来。";
CM_ SG_ 1028 PEPS_SSBInputFailure "The_warning_indicator_the_SSB_is_faulty";
CM_ SG_ 1028 PEPS_SmartSystemWarning1_1 "非OFF档关门钥匙不在车内报警";
CM_ SG_ 1028 PEPS_SmartSystemWarning2_2 "车速无钥匙报警";
CM_ SG_ 1028 PEPS_SmartSystemWarning3_1 "钥匙电池电量低报警";
CM_ SG_ 1028 PEPS_SmartSystemWarning3_2 "用于SSB启动时，非P档时启动报警";
CM_ SG_ 1028 PEPS_SmartSystemWarning4_2 "用于SSB启动时，未踩刹车提醒报警";
CM_ SG_ 1028 PEPS_SmartSystemWarning4_3 "下电不在P档报警";
CM_ SG_ 1028 PEPS_SystemWarning "PEPS系统故障提醒";
CM_ SG_ 1028 PEPS_BLTKeyPESts "蓝牙钥匙的PE功能开启关闭状态信号";
CM_ SG_ 1104 RLCR_2_CRC1 "Profile1A:E2E CRC (SAE J1850 CRC-8) for 8 Bytes
DataID:0x0045";
CM_ SG_ 1104 RLCR_2_RollgCntr1 "Profile1A:E2E Rolling message counter(the maximum value of Alive counter is 14)";
CM_ SG_ 1104 RLCR_2_Resd1 "Profile1A:E2E Reserved";
CM_ SG_ 1104 RLCR_2_RCWWarn "Rear Collision Warning Warning";
CM_ SG_ 1104 RLCR_2_RCTAWarn "RCTA Warning（高配不发）";
CM_ SG_ 1104 RLCR_2_BSDLCWONOFFSts "BSD/LCA Switch status";
CM_ SG_ 1104 RLCR_2_DOWONOFFSts "Door open warning Switch status";
CM_ SG_ 1104 RLCR_2_RCWONOFFSts "Rear Collision Warning Switch Status";
CM_ SG_ 1104 RLCR_2_RCTARCTBONOFFSts "RCTA/RCTB Switch status（高配不发，低配无0x2）";
CM_ SG_ 1271 RRCR_2_CRC1 "Profile1A:E2E CRC (SAE J1850 CRC-8) for 8 Bytes
DataID:0x0047";
CM_ SG_ 1271 RRCR_2_RollgCntr1 "Profile1A:E2E Rolling message counter(the maximum value of Alive counter is 14)";
CM_ SG_ 1271 RRCR_2_Resd1 "Profile1A:E2E Reserved";
CM_ SG_ 1271 RRCR_2_RCWWarn "Rear Collision Warning Warning";
CM_ SG_ 1271 RRCR_2_RCTAWarn "FCTA Warning";
CM_ SG_ 1271 RRCR_2_BSDLCWONOFFSts "BSD/LCA Switch status";
CM_ SG_ 1271 RRCR_2_DOWONOFFSts "Door open warning Switch status";
CM_ SG_ 1271 RRCR_2_RCWONOFFSts "Rear Collision Warning Switch Status";
CM_ SG_ 1271 RRCR_2_RCTARCTBONOFFSts "RCTA/RCTB Switch status";
CM_ SG_ 587 ONEBOX_4_LHFWheelSpeedRPM "left front Wheel Speed(the unit is RPM)";
CM_ SG_ 587 ONEBOX_4_RHFWheelSpeedRPM "right front  Wheel Speed(the unit is RPM)";
CM_ SG_ 587 LHRWheelSpeedRPM "Left Rear Wheel Speed(the unit is RPM)";
CM_ SG_ 587 RHRWheelSpeedRPM "right Rear  Wheel Speed(the unit is RPM)";
CM_ SG_ 587 LHRPulseCounterFailSts "left rear wheel Pulse Counter Fail Status";
CM_ SG_ 587 LHRPulseCounter "left rear wheel Pulse Counter";
CM_ SG_ 587 RHRPulseCounterFailSts "right rear wheel Pulse Counter FailSts";
CM_ SG_ 587 RHRPulseCounter "right rear wheel Pulse Counter";
CM_ SG_ 587 RHFPulseCounterFailSts "right front wheel Pulse Counter FailSts";
CM_ SG_ 587 RHFPulseCounter "right front wheel Pulse Counter";
CM_ SG_ 587 LHFPulseCounterFailSts "left front wheel Pulse Counter FailSts";
CM_ SG_ 587 LHFPulseCounter "left front wheel Pulse Counter";
CM_ SG_ 587 LHFWheelDriveDirection "left front Wheel Drive Direction";
CM_ SG_ 587 RHFWheelDriveDirection "right front Wheel Speed Drive Direction";
CM_ SG_ 587 LHRWheelDriveDirection "left rear Wheel Speed Drive Direction";
CM_ SG_ 587 RHRWheelDriveDirection "right rear Wheel Speed Drive Direction";
CM_ SG_ 1180 ACU_1_CRC1 "Profile1A:E2E CRC (SAE J1850 CRC-8) for 8 Bytes
DataID:0x00AD";
CM_ SG_ 1180 ACU_1_RollgCntr1 "Profile1A:E2E Rolling message counter(the maximum value of Alive counter is 14)";
CM_ SG_ 1180 ACU_1_Resd1 "Profile1A:E2E Reserved";
CM_ SG_ 1180 ACU_1_ThdRowLBeltWarning "With Occupancy detection：
Third row (left) safety belt status
0x0:not occupied/occupied and fastened
0x1:occupied and not fastened 
Without Occupancy detection：
0x0:Seat belt is fastened
0x1:Seat belt is not fastened";
CM_ SG_ 1180 ACU_1_ThdRowRBeltWarning "With Occupancy detection：
Third row (right) safety belt status
0x0:not occupied/occupied and fastened
0x1:occupied and not fastened 
Without Occupancy detection：
0x0:Seat belt is fastened
0x1:Seat belt is not fastened";
CM_ SG_ 1180 ACU_1_PsngrSeatBeltWarning "In addition to the corresponding value sent by ACU with copilot safety belt alarm, the signal sent by ACU without alarm configuration sends the startup value.
The signal is judged in combination with SBR";
CM_ SG_ 1180 ACU_1_SecRowLBeltWarning "With Occupancy detection：
Second row (left) safety belt status
0x0:not occupied/occupied and fastened
0x1:occupied and not fastened 
Without Occupancy detection：
0x0:Seat belt is fastened
0x1:Seat belt is not fastened";
CM_ SG_ 1180 ACU_1_SecRowMBeltWarning "With Occupancy detection：
Second row (middle) safety belt status
0x0:not occupied/occupied and fastened
0x1:occupied and not fastened 
Without Occupancy detection：
0x0:Seat belt is fastened
0x1:Seat belt is not fastened";
CM_ SG_ 1180 ACU_1_SecRowRBeltWarning "With Occupancy detection：
Second row (right) safety belt status
0x0:not occupied/occupied and fastened
0x1:occupied and not fastened 
Without Occupancy detection：
0x0:Seat belt is fastened
0x1:Seat belt is not fastened";
CM_ SG_ 1180 ABM_1_Rollover_Status "气囊翻滚点爆状态
0x0:RolloverEnable 翻滚点爆不抑制
0x1:RolloverDisable 翻滚点爆被抑制";
CM_ SG_ 1180 ACU_1_PsngrSeatOccupiedSts "副驾座椅占位状态，0为未占位，1为占位
E03：国内\国际非欧盟一、二阶段都体现，类欧盟\欧盟不分阶段都体现；
E0Y：国内\国际非欧盟，类欧盟\欧盟都体现；
0x2:open circuit (03仅欧盟、类欧盟做，0Y都做)
0x3:short circuit (03仅欧盟、类欧盟做，0Y都做)";
CM_ SG_ 1269 LISDShowCMDSts "ISD灯光开启状态";
CM_ SG_ 1269 LISDShowModeSts "ISD灯光模式状态";
CM_ SG_ 1269 LISDTransmitStatus "灯具反馈信息：反馈当前数据帧是否接收成功、数据校验是否正确、图片显示是否成功。";
CM_ SG_ 1269 LISDDisplayStatus "灯具反馈信息：反馈当前图片显示状态。";
CM_ SG_ 1269 LISD_ParkingShowModSts "LISD驻车动画状态反馈";
CM_ SG_ 1269 LISD_ParkingShowCMDSts "驻车动画开关反馈";
CM_ SG_ 1233 RISDShowCMDSts "ISD灯光开启状态";
CM_ SG_ 1233 RISDShowModeSts "ISD灯光模式状态";
CM_ SG_ 1233 RISD_TransmitStatus "灯具反馈信息：反馈当前数据帧是否接收成功、数据校验是否正确、图片显示是否成功。";
CM_ SG_ 1233 RISD_DisplayStatus "灯具反馈信息：反馈当前图片显示状态。";
CM_ SG_ 1233 RISD_ParkingShowModSts "RISD驻车动画状态反馈";
CM_ SG_ 1233 RISD_ParkingShowCMDSts "驻车动画开关反馈";
CM_ SG_ 1169 LC_DIYMusicShowModSts "固定灯光秀状态反馈信号";
CM_ SG_ 1169 LC_RandomMusicShowSts "随机灯光秀状态反馈信号";
CM_ SG_ 1169 LC_LiShowModSts "解闭锁模式状态反馈信号";
CM_ SG_ 1427 ILCF_1_LogoParkingSts "前LOGO驻车点亮开关状态反馈";
CM_ SG_ 1427 ILCF_1_LogoChargingSts "前LOGO充电灯效开关状态反馈";
CM_ SG_ 1427 ILCF_1_DIYMusicShowModSts "固定灯光秀状态反馈信号";
CM_ SG_ 1427 ILCF_1_RandomMusicShowSts "随机灯光秀状态反馈信号";
CM_ SG_ 1427 ILCF_1_LogoColorAdjSts "Logo灯颜色设置反馈，1-256分别对应256种颜色";
CM_ SG_ 821 ADS_5_CRC1 "Profile1A:E2E CRC (SAE J1850 CRC-8) for 8 Bytes
DataID:No ASIL requirements.Not configure
CRC Reserved.";
CM_ SG_ 821 ADS_5_RollgCntr1 "Profile1A:E2E Rolling message counter(the maximum value of Alive counter is 14)";
CM_ SG_ 821 ADS_5_Resd1 "Profile1A:E2E Reserved";
CM_ SG_ 821 ADS_5_ILOASts "智慧躲闪功能执行状态";
CM_ SG_ 821 ADS_5_ICAQuitReason "ICA 退出原因";
CM_ SG_ 821 ADS_5_ISLISt "超速报警功能状态";
CM_ SG_ 821 ADS_5_ILOATextInfo "智慧躲闪提示信息";
CM_ SG_ 821 ADS_5_ILOAActdirection "智慧躲闪方向";
CM_ SG_ 821 ADS_5_LKS_warning "LKS声音报警信号";
CM_ SG_ 821 ADS_5_ISLIOverSpeedWarn "超速报警状态";
CM_ SG_ 821 ADS_5_ISLISpeedLimitSign "限速标志值";
CM_ SG_ 821 ADS_5_EgoLeftLineHeatgAg "自车中心线与本车道
 车道线的夹角";
CM_ SG_ 821 ADS_5_EgoLeLineID "左侧车道线有效信号";
CM_ SG_ 821 ADS_5_EgoLeLineColor "本车道左侧车道线颜色";
CM_ SG_ 821 ADS_5_EgoLeLineTyp "本车道左侧车道线类型";
CM_ SG_ 821 ADS_5_EgoLeLineHozlDst "自车中心线与本车道左侧车道线横向距离";
CM_ SG_ 821 ADS_5_CRC2 "Profile1A:E2E CRC (SAE J1850 CRC-8) for 8 Bytes
DataID:No ASIL requirements.Not configure
CRC Reserved.";
CM_ SG_ 821 ADS_5_RollgCntr2 "Profile1A:E2E Rolling message counter(the maximum value of Alive counter is 14)";
CM_ SG_ 821 ADS_5_Resd2 "Profile1A:E2E Reserved";
CM_ SG_ 821 ADS_5_NeborLeLineID "左侧相邻车道线有效信号";
CM_ SG_ 821 ADS_5_NeborLeLineColor "左侧相邻车道线颜色";
CM_ SG_ 821 ADS_5_NeborLeLineTyp "左侧相邻车道线类型";
CM_ SG_ 821 ADS_5_EgoLeLineCrvt "本车道左侧车道线曲率";
CM_ SG_ 821 ADS_5_NeborLeLineHozlDst "自车中心线与左侧相邻车 
 道线横向距离";
CM_ SG_ 821 ADS_5_NeborRiLineID "右侧相邻车道线有效信号";
CM_ SG_ 821 ADS_5_NeborRiLineColor "右侧相邻车道线颜色";
CM_ SG_ 821 ADS_5_NeborRiLineTyp "右侧相邻车道线类型";
CM_ SG_ 821 ADS_5_NeborLeLineCrvt "左侧相邻车道线曲率";
CM_ SG_ 821 ADS_5_NeborRiLineHozlDst "自车中心线与右侧相邻车 
 道线横向距离";
CM_ SG_ 821 ADS_5_CRC3 "Profile1A:E2E CRC (SAE J1850 CRC-8) for 8 Bytes
DataID:No ASIL requirements.Not configure
CRC Reserved.";
CM_ SG_ 821 ADS_5_RollgCntr3 "Profile1A:E2E Rolling message counter(the maximum value of Alive counter is 14)";
CM_ SG_ 821 ADS_5_Resd3 "Profile1A:E2E Reserved";
CM_ SG_ 821 ADS_5_ELKSettingSt "ELK功能设置状态反馈";
CM_ SG_ 821 ADS_5_LDWLDPSnvtySet "车道偏离敏感度反馈";
CM_ SG_ 821 ADS_5_LDWWarnType "LDW/LDP报警方式反馈";
CM_ SG_ 821 ADS_5_NeborRiLineCrvt "右侧相邻车道线曲率";
CM_ SG_ 821 ADS_5_IESSwtSet "智慧躲闪反馈开关（预留默认开）";
CM_ SG_ 821 ADS_5_IHCSettingSt "智能远光辅助开关反馈";
CM_ SG_ 821 ADS_5_ISLIWarningMod "智能限速提醒方式反馈";
CM_ SG_ 821 ADS_5_ICAEnableBtnSts "ICA功能使能开关反馈（车道居中辅助）";
CM_ SG_ 821 ADS_5_EgoRiLineID "右侧车道线有效信号";
CM_ SG_ 821 ADS_5_EgoRiLineTyp "本车道右侧车道线类型";
CM_ SG_ 821 ADS_5_EgoRiLineColor "本车道右侧车道线颜色";
CM_ SG_ 821 ADS_5_EgoRiLineHozlDst "自车中心线与本车道右侧车道线横向距离";
CM_ SG_ 821 ADS_5_CRC4 "Profile1A:E2E CRC (SAE J1850 CRC-8) for 8 Bytes
DataID:No ASIL requirements.Not configure
CRC Reserved.";
CM_ SG_ 821 ADS_5_RollgCntr4 "Profile1A:E2E Rolling message counter(the maximum value of Alive counter is 14)";
CM_ SG_ 821 ADS_5_Resd4 "Profile1A:E2E Reserved";
CM_ SG_ 821 ADS_5_EgoRightLineHeatgAg "自车中心线与本车道右侧车道线的夹角";
CM_ SG_ 821 ADS_5_EgoRiLineCrvt "本车道右侧车道线曲率";
CM_ SG_ 821 ADS_5_NeborLeftLineHeatgAg "自车中心线与相邻车道左侧车道线的夹角";
CM_ SG_ 821 ADS_5_NeborRightLineHeatgAg "自车中心线与相邻车道右侧车道线的夹角";
BA_DEF_ BO_  "GenMsgCycleTimeFast" INT 0 50000;
BA_DEF_ BO_  "GenMsgNrOfRepetition" INT 0 999999;
BA_DEF_ BO_  "GenMsgDelayTime" INT 0 1000;
BA_DEF_ BO_  "VFrameFormat" ENUM  "StandardCAN","ExtendedCAN","reserved","reserved","reserved","reserved","reserved","reserved","reserved","reserved","reserved","reserved","reserved","reserved","StandardCAN_FD","ExtendedCAN_FD";
BA_DEF_ BO_  "GenMsgILSupport" ENUM  "No","Yes";
BA_DEF_ BO_  "NmMessage" ENUM  "No","Yes";
BA_DEF_ BO_  "DiagMessage" ENUM  "No","Yes";
BA_DEF_ BO_  "GenMsgSendType" ENUM  "Cyclic","Event","IfActive","CE","CA","NoMsgSendType";
BA_DEF_ BO_  "GenMsgCycleTime" INT 0 50000;
BA_DEF_ BO_  "CANFD_BRS" INT 0 1;
BA_DEF_ BO_  "NmAsrMessage" ENUM  "No","Yes";
BA_DEF_ BO_  "DiagState" ENUM  "No","Yes";
BA_DEF_ BO_  "DiagRequest" ENUM  "No","Yes";
BA_DEF_ BO_  "DiagResponse" ENUM  "No","Yes";
BA_DEF_ BO_  "MsgType" ENUM  "IL","NM","DIAG","APPL";
BA_DEF_ BO_  "Msg_ASIL" ENUM  "vector_leerstring","QM","A","B","C","D";
BA_DEF_ BO_  "GRC_History" STRING ;
BA_DEF_ SG_  "GenSigStartValue" FLOAT 0 100000000000;
BA_DEF_ SG_  "GenSigInactiveValue" INT 0 100000;
BA_DEF_ SG_  "GenSigInvalidValue" INT 0 100000;
BA_DEF_ SG_  "GenSigSendType" ENUM  "Cyclic","OnChange","OnWrite","IfActive","OnChangeWithRepetition","OnWriteWithRepetition","IfActiveWithRepetition","NoSigSendType","OnChangeAndIfActive","OnChangeAndIfActiveWithRepetition","CA","CE","Event";
BA_DEF_ SG_  "ASIL" ENUM  "vector_leerstring","QM","A","B","C","D";
BA_DEF_DEF_  "GenMsgCycleTimeFast" 0;
BA_DEF_DEF_  "GenMsgNrOfRepetition" 0;
BA_DEF_DEF_  "GenMsgDelayTime" 0;
BA_DEF_DEF_  "VFrameFormat" "StandardCAN";
BA_DEF_DEF_  "GenMsgILSupport" "No";
BA_DEF_DEF_  "NmMessage" "No";
BA_DEF_DEF_  "DiagMessage" "No";
BA_DEF_DEF_  "GenMsgSendType" "NoMsgSendType";
BA_DEF_DEF_  "GenMsgCycleTime" 0;
BA_DEF_DEF_  "CANFD_BRS" 0;
BA_DEF_DEF_  "NmAsrMessage" "No";
BA_DEF_DEF_  "DiagState" "No";
BA_DEF_DEF_  "DiagRequest" "No";
BA_DEF_DEF_  "DiagResponse" "No";
BA_DEF_DEF_  "MsgType" "";
BA_DEF_DEF_  "Msg_ASIL" "";
BA_DEF_DEF_  "GRC_History" "";
BA_DEF_DEF_  "GenSigStartValue" 0;
BA_DEF_DEF_  "GenSigInactiveValue" 0;
BA_DEF_DEF_  "GenSigInvalidValue" 0;
BA_DEF_DEF_  "GenSigSendType" "NoSigSendType";
BA_DEF_DEF_  "ASIL" "";
BA_ "GRC_History" BO_ 1211 "[{'approvedBy':'贾少辉','author':'吴俊祥','changesComments':'FLZCU_DriverSeatMovFailCause主驾调节失败原因，ICC接收\n5.1全平台新增','date':'2025/11/13','ecu':'FLZCU_26(0x4BB)','ecuName':'ICC,ICC_ICE,FLZCU','reviewedBy':'杨华','revision':'V1.3.1'},{'approv";
BA_ "GenMsgILSupport" BO_ 1211 1;
BA_ "MsgType" BO_ 1211 0;
BA_ "GenMsgCycleTime" BO_ 1211 100;
BA_ "GenMsgSendType" BO_ 1211 0;
BA_ "CANFD_BRS" BO_ 1211 1;
BA_ "VFrameFormat" BO_ 1211 14;
BA_ "GenMsgILSupport" BO_ 1429 1;
BA_ "MsgType" BO_ 1429 0;
BA_ "GenMsgCycleTime" BO_ 1429 1000;
BA_ "GenMsgSendType" BO_ 1429 0;
BA_ "CANFD_BRS" BO_ 1429 1;
BA_ "VFrameFormat" BO_ 1429 14;
BA_ "GRC_History" BO_ 1072 "[{'approvedBy':'贾少辉','author':'吴俊祥','changesComments':'IC网段0x430信号：LHTurnlightSts、RHTurnlightSts、LHFdoorSts、LHFDoorLockSts、HoodSts、LHFSeatBeltSW、TrunkSts、LHRdoorSts、RLWinPosn、SeatHeatLevelsFL、RearDefrostSts、LHRDoorLockSts、RL_Childr";
BA_ "GenMsgILSupport" BO_ 1072 1;
BA_ "MsgType" BO_ 1072 0;
BA_ "GenMsgCycleTime" BO_ 1072 100;
BA_ "GenMsgSendType" BO_ 1072 0;
BA_ "CANFD_BRS" BO_ 1072 1;
BA_ "VFrameFormat" BO_ 1072 14;
BA_ "GRC_History" BO_ 1043 "[{'approvedBy':'贾少辉','author':'吴俊祥','changesComments':'刘胤翠：（EEA5.1更新，D01&D01P/D01华为/T1J FL2华为未设变不更新）\n1、根据夏祥华反馈\nI_BATT：精度由1更新为0.0078125  \n        偏移量由0更新为-256\n        最小物理值0更新为-200\n        最大物";
BA_ "GenMsgILSupport" BO_ 1043 1;
BA_ "MsgType" BO_ 1043 0;
BA_ "GenMsgCycleTime" BO_ 1043 100;
BA_ "GenMsgSendType" BO_ 1043 0;
BA_ "CANFD_BRS" BO_ 1043 1;
BA_ "VFrameFormat" BO_ 1043 14;
BA_ "GRC_History" BO_ 1022 "[{'approvedBy':'贾少辉','author':'吴俊祥','changesComments':'FLZCU_EnterArmingReason新增枚举值0xC:ADAS_Lock\n0xC:ADAS泊车下电闭锁（5.1全平台新增）-丁阁文[电子电器]','date':'2025/12/9','ecu':'FLZCU_40（0x3FE）','ecuName':'FLZCU','reviewedBy':'杨华','revis";
BA_ "GenMsgILSupport" BO_ 1022 1;
BA_ "MsgType" BO_ 1022 0;
BA_ "GenMsgCycleTime" BO_ 1022 100;
BA_ "GenMsgSendType" BO_ 1022 0;
BA_ "CANFD_BRS" BO_ 1022 1;
BA_ "VFrameFormat" BO_ 1022 14;
BA_ "GRC_History" BO_ 1020 "[{'approvedBy':'贾少辉','author':'吴俊祥','changesComments':'OA：JTPPSYB-QT-2025-87877号&JTPPSYB-QT-2025-87514号\n新增ASU_2_sensorErrorSts、ASU_2_LFHeight、ASU_2_RFHeight、ASU_2_LRHeight、ASU_2_RRHeight五个信号，并增加ICC接收','date':'2025/8/26','ecu':'F";
BA_ "GenMsgILSupport" BO_ 1020 1;
BA_ "MsgType" BO_ 1020 0;
BA_ "GenMsgCycleTime" BO_ 1020 100;
BA_ "GenMsgSendType" BO_ 1020 0;
BA_ "CANFD_BRS" BO_ 1020 1;
BA_ "VFrameFormat" BO_ 1020 14;
BA_ "GRC_History" BO_ 1035 "[{'approvedBy':'贾少辉','author':'吴俊祥','changesComments':'新增信号VCC_1_DriveMode,ICC接收，用于燃油车的驾驶模式','date':'2025/10/29','ecu':'VCC_1(0x40B)','ecuName':'ICC,FLZCU,ICC_ICE','reviewedBy':'杨华','revision':'V1.3'},{'approvedBy':'贾少辉','auth";
BA_ "GenMsgILSupport" BO_ 1035 1;
BA_ "MsgType" BO_ 1035 0;
BA_ "GenMsgCycleTime" BO_ 1035 100;
BA_ "GenMsgSendType" BO_ 1035 0;
BA_ "CANFD_BRS" BO_ 1035 1;
BA_ "VFrameFormat" BO_ 1035 14;
BA_ "GenMsgILSupport" BO_ 1075 1;
BA_ "MsgType" BO_ 1075 0;
BA_ "GenMsgDelayTime" BO_ 1075 5;
BA_ "GenMsgNrOfRepetition" BO_ 1075 3;
BA_ "GenMsgCycleTimeFast" BO_ 1075 100;
BA_ "GenMsgSendType" BO_ 1075 1;
BA_ "CANFD_BRS" BO_ 1075 1;
BA_ "VFrameFormat" BO_ 1075 14;
BA_ "GenMsgILSupport" BO_ 1136 1;
BA_ "MsgType" BO_ 1136 0;
BA_ "GenMsgDelayTime" BO_ 1136 5;
BA_ "GenMsgNrOfRepetition" BO_ 1136 96;
BA_ "GenMsgCycleTimeFast" BO_ 1136 100;
BA_ "GenMsgSendType" BO_ 1136 1;
BA_ "CANFD_BRS" BO_ 1136 1;
BA_ "VFrameFormat" BO_ 1136 14;
BA_ "GRC_History" BO_ 1196 "[{'approvedBy':'贾少辉','author':'吴俊祥','changesComments':'1、DOW预警开关反馈，新增TDL_RhythmModeSts信号，用于ICC接收；[智舱部-刘标]\n2、驾驶模式开关反馈，新增TDL_AssociatedDrivingModeSts信号，用于ICC接收；[智舱部-刘标]','date':'2025/12/23','ecu':'FLZC";
BA_ "GenMsgILSupport" BO_ 1196 1;
BA_ "MsgType" BO_ 1196 0;
BA_ "GenMsgCycleTime" BO_ 1196 100;
BA_ "GenMsgSendType" BO_ 1196 0;
BA_ "CANFD_BRS" BO_ 1196 1;
BA_ "VFrameFormat" BO_ 1196 14;
BA_ "GenMsgILSupport" BO_ 1177 1;
BA_ "MsgType" BO_ 1177 0;
BA_ "GenMsgCycleTime" BO_ 1177 100;
BA_ "GenMsgSendType" BO_ 1177 0;
BA_ "CANFD_BRS" BO_ 1177 1;
BA_ "VFrameFormat" BO_ 1177 14;
BA_ "DiagState" BO_ 2015 1;
BA_ "DiagMessage" BO_ 2015 1;
BA_ "MsgType" BO_ 2015 2;
BA_ "GenMsgSendType" BO_ 2015 1;
BA_ "CANFD_BRS" BO_ 2015 1;
BA_ "VFrameFormat" BO_ 2015 14;
BA_ "GenMsgILSupport" BO_ 1109 1;
BA_ "MsgType" BO_ 1109 0;
BA_ "GenMsgCycleTime" BO_ 1109 100;
BA_ "GenMsgSendType" BO_ 1109 0;
BA_ "CANFD_BRS" BO_ 1109 1;
BA_ "VFrameFormat" BO_ 1109 14;
BA_ "GRC_History" BO_ 1288 "[{'approvedBy':'贾少辉','author':'吴俊祥','changesComments':'DK网段0x508信号：CurrentTimeYear、CurrentTimeMonth、CurrentTimeDay、CurrentTimeHour、CurrentTimeMinute、CurrentTimeSecond与ICC_COM_8的其他ID下信号重复，故添加_508h后缀，共计6条信号-吴俊祥','dat";
BA_ "GenMsgILSupport" BO_ 1288 1;
BA_ "MsgType" BO_ 1288 0;
BA_ "GenMsgCycleTime" BO_ 1288 500;
BA_ "GenMsgSendType" BO_ 1288 0;
BA_ "CANFD_BRS" BO_ 1288 1;
BA_ "VFrameFormat" BO_ 1288 14;
BA_ "GRC_History" BO_ 1063 "[{'approvedBy':'贾少辉','author':'吴俊祥','changesComments':'TBOX_SentinelModeSw信号新增ICC接收-[智舱部-夏超超，刘标，王梓涵][智驾部-张龙]','date':'2026/1/21','ecu':'TBOX_6(0x427)','ecuName':'ICC,ICC_ICE','reviewedBy':'杨华','revision':'V1.5'}]";
BA_ "GenMsgILSupport" BO_ 1063 1;
BA_ "MsgType" BO_ 1063 0;
BA_ "GenMsgDelayTime" BO_ 1063 5;
BA_ "GenMsgNrOfRepetition" BO_ 1063 3;
BA_ "GenMsgCycleTimeFast" BO_ 1063 100;
BA_ "GenMsgSendType" BO_ 1063 1;
BA_ "CANFD_BRS" BO_ 1063 1;
BA_ "VFrameFormat" BO_ 1063 14;
BA_ "GRC_History" BO_ 1148 "[{'approvedBy':'贾少辉','author':'吴俊祥','changesComments':'流水号:JTPPSYB-BG-2026-02932号：\n新增TimeToStartSentinelDayFed_47Ch、TimeToStartSentinelHourFed_47Ch、TimeToStartSentinelMinutFed_47Ch、TimeToStopSentinelHourFed_47Ch、TimeToStopSentinelMinutF";
BA_ "GenMsgILSupport" BO_ 1148 1;
BA_ "MsgType" BO_ 1148 0;
BA_ "GenMsgCycleTime" BO_ 1148 100;
BA_ "GenMsgSendType" BO_ 1148 0;
BA_ "CANFD_BRS" BO_ 1148 1;
BA_ "VFrameFormat" BO_ 1148 14;
BA_ "GRC_History" BO_ 1162 "[{'approvedBy':'贾少辉','author':'吴俊祥','changesComments':'VehicleSpeedVSOSigt新增AVAS接收——[电子电器部-张异莹]\nVehicleSpeedVSOSigValidDatat新增AVAS接收——[电子电器部-张异莹]','date':'2026/2/3','ecu':'ONEBOX_1_G(0x48A)','ecuName':'AVAS','reviewedBy";
BA_ "Msg_ASIL" BO_ 1162 3;
BA_ "GenMsgILSupport" BO_ 1162 1;
BA_ "MsgType" BO_ 1162 0;
BA_ "GenMsgCycleTime" BO_ 1162 100;
BA_ "GenMsgSendType" BO_ 1162 0;
BA_ "CANFD_BRS" BO_ 1162 1;
BA_ "VFrameFormat" BO_ 1162 14;
BA_ "GRC_History" BO_ 1202 "[{'approvedBy':'贾少辉','author':'吴俊祥','changesComments':'根据电控系统部储成云申请(OA:JTPPSYB-QT-2025-135618)根据发动机硬件功能需求，开发机油稀释功能新增信号:1、Activeheatingmode','date':'2026/1/7','ecu':'EMS_1_G(0x4B2)','ecuName':'CGW,ICC,ICC_ICE','r";
BA_ "GenMsgILSupport" BO_ 1202 1;
BA_ "MsgType" BO_ 1202 0;
BA_ "GenMsgCycleTime" BO_ 1202 100;
BA_ "GenMsgSendType" BO_ 1202 0;
BA_ "CANFD_BRS" BO_ 1202 1;
BA_ "VFrameFormat" BO_ 1202 14;
BA_ "GRC_History" BO_ 683 "[{'approvedBy':'贾少辉','author':'吴俊祥','changesComments':'同步D01华为信号：\n新增信号RHFDoorSts_Valid、RHRDoorSts_Valid','date':'2025/9/22','ecu':'FRZCU_1(0x2AB)','ecuName':'CGW','reviewedBy':'杨华','revision':'V1.2'}]";
BA_ "Msg_ASIL" BO_ 683 2;
BA_ "GenMsgILSupport" BO_ 683 1;
BA_ "MsgType" BO_ 683 0;
BA_ "GenMsgCycleTime" BO_ 683 20;
BA_ "GenMsgSendType" BO_ 683 0;
BA_ "CANFD_BRS" BO_ 683 1;
BA_ "VFrameFormat" BO_ 683 14;
BA_ "GRC_History" BO_ 33 "[{'approvedBy':'贾少辉','author':'吴俊祥','changesComments':'ACU_3_CrashOutputSts信号新增ICC和ICC_ICE接收-[智舱部 刘标]','date':'2026/1/7','ecu':'ACU_3(0x021)','ecuName':'ICC,ICC_ICE','reviewedBy':'杨华','revision':'V1.4.1'}]";
BA_ "GenMsgILSupport" BO_ 33 1;
BA_ "MsgType" BO_ 33 0;
BA_ "GenMsgCycleTime" BO_ 33 10;
BA_ "GenMsgSendType" BO_ 33 0;
BA_ "CANFD_BRS" BO_ 33 1;
BA_ "VFrameFormat" BO_ 33 14;
BA_ "GRC_History" BO_ 1217 "[{'approvedBy':'贾少辉','author':'吴俊祥','changesComments':'修改：\n流水号:JTPPSYB-QT-2025-127935号\n1、“ASU_1_SuspCurrentLvl”修改枚举值为“0x0:Invalid\n0x1:High 3 level\n0x2:Between high3 and high2 level\n0x3:High 2 level\n0x4:Between high2 and high1";
BA_ "GenMsgILSupport" BO_ 1217 1;
BA_ "MsgType" BO_ 1217 0;
BA_ "GenMsgCycleTime" BO_ 1217 100;
BA_ "GenMsgSendType" BO_ 1217 0;
BA_ "CANFD_BRS" BO_ 1217 1;
BA_ "VFrameFormat" BO_ 1217 14;
BA_ "GRC_History" BO_ 1316 "[{'approvedBy':'贾少辉','author':'吴俊祥','changesComments':'根据电子电器FRZCU丁阁文需求EEA5.1更新胎压最大值及精度\n1、LHFTirePressure、RHFTirePressure、LHRTirePressure、RHRTirePressure这4个胎压信号精度由1.373更新为2.75，物理最大值由350.115更新为701.25\n";
BA_ "GenMsgILSupport" BO_ 1316 1;
BA_ "MsgType" BO_ 1316 0;
BA_ "GenMsgCycleTime" BO_ 1316 500;
BA_ "GenMsgSendType" BO_ 1316 0;
BA_ "CANFD_BRS" BO_ 1316 1;
BA_ "VFrameFormat" BO_ 1316 14;
BA_ "Msg_ASIL" BO_ 1324 3;
BA_ "GenMsgILSupport" BO_ 1324 1;
BA_ "MsgType" BO_ 1324 0;
BA_ "GenMsgCycleTime" BO_ 1324 500;
BA_ "GenMsgSendType" BO_ 1324 0;
BA_ "CANFD_BRS" BO_ 1324 1;
BA_ "VFrameFormat" BO_ 1324 14;
BA_ "GRC_History" BO_ 991 "[{'approvedBy':'贾少辉','author':'吴俊祥','changesComments':'HVH_DC_curr信号名改为TMS_2_HVH_DC_curr\nHVH_HV_voltage信号名改为TMS_2_HVH_HV_voltage','date':'2025/11/13','ecu':'TMS_2(0x3DF)','ecuName':'CGW','reviewedBy':'杨华','revision':'V1.3.1'}]";
BA_ "GenMsgILSupport" BO_ 991 1;
BA_ "MsgType" BO_ 991 0;
BA_ "GenMsgCycleTime" BO_ 991 50;
BA_ "GenMsgSendType" BO_ 991 0;
BA_ "CANFD_BRS" BO_ 991 1;
BA_ "VFrameFormat" BO_ 991 14;
BA_ "GenMsgILSupport" BO_ 1188 1;
BA_ "MsgType" BO_ 1188 0;
BA_ "GenMsgCycleTime" BO_ 1188 100;
BA_ "GenMsgSendType" BO_ 1188 0;
BA_ "CANFD_BRS" BO_ 1188 1;
BA_ "VFrameFormat" BO_ 1188 14;
BA_ "GRC_History" BO_ 612 "[{'approvedBy':'贾少辉','author':'吴俊祥','changesComments':'同步源网段信号名称更新：\nCRC1_264h、RollgCntr1_264h、Resd1_264h、FltLamp_264h、ParkLamp_264h、ActrSt_264h、RWUSt_264h、TextDisp_264h、Reserved1_264h、EpbSwt_264h、EcdActvSts_264h、EPB_RwuAvl_2";
BA_ "GenMsgILSupport" BO_ 612 1;
BA_ "MsgType" BO_ 612 0;
BA_ "GenMsgCycleTime" BO_ 612 20;
BA_ "GenMsgSendType" BO_ 612 0;
BA_ "CANFD_BRS" BO_ 612 1;
BA_ "VFrameFormat" BO_ 612 14;
BA_ "Msg_ASIL" BO_ 1193 3;
BA_ "GenMsgILSupport" BO_ 1193 1;
BA_ "MsgType" BO_ 1193 0;
BA_ "GenMsgCycleTime" BO_ 1193 100;
BA_ "GenMsgSendType" BO_ 1193 0;
BA_ "CANFD_BRS" BO_ 1193 1;
BA_ "VFrameFormat" BO_ 1193 14;
BA_ "GenMsgILSupport" BO_ 1197 1;
BA_ "MsgType" BO_ 1197 0;
BA_ "GenMsgCycleTime" BO_ 1197 100;
BA_ "GenMsgSendType" BO_ 1197 0;
BA_ "CANFD_BRS" BO_ 1197 1;
BA_ "VFrameFormat" BO_ 1197 14;
BA_ "GRC_History" BO_ 1200 "[{'approvedBy':'贾少辉','author':'吴俊祥','changesComments':'刘胤翠：\n1、根据夏祥华反馈\nSOH_SUL_STATE/SOFV_StopEnable_STATE/SOFV_Restart_STATE更新信号属性值','date':'2025/10/14','ecu':'FLZCU_6(0x4B0)','ecuName':'CGW','reviewedBy':'杨华','revision':'V1.";
BA_ "GenMsgILSupport" BO_ 1200 1;
BA_ "MsgType" BO_ 1200 0;
BA_ "GenMsgCycleTime" BO_ 1200 100;
BA_ "GenMsgSendType" BO_ 1200 0;
BA_ "CANFD_BRS" BO_ 1200 1;
BA_ "VFrameFormat" BO_ 1200 14;
BA_ "GenMsgILSupport" BO_ 1061 1;
BA_ "MsgType" BO_ 1061 0;
BA_ "GenMsgCycleTime" BO_ 1061 100;
BA_ "GenMsgSendType" BO_ 1061 0;
BA_ "CANFD_BRS" BO_ 1061 1;
BA_ "VFrameFormat" BO_ 1061 14;
BA_ "GenMsgILSupport" BO_ 1065 1;
BA_ "MsgType" BO_ 1065 0;
BA_ "GenMsgCycleTime" BO_ 1065 100;
BA_ "GenMsgSendType" BO_ 1065 0;
BA_ "CANFD_BRS" BO_ 1065 1;
BA_ "VFrameFormat" BO_ 1065 14;
BA_ "GenMsgILSupport" BO_ 1069 1;
BA_ "MsgType" BO_ 1069 0;
BA_ "GenMsgCycleTime" BO_ 1069 100;
BA_ "GenMsgSendType" BO_ 1069 0;
BA_ "CANFD_BRS" BO_ 1069 1;
BA_ "VFrameFormat" BO_ 1069 14;
BA_ "GenMsgILSupport" BO_ 1087 1;
BA_ "MsgType" BO_ 1087 0;
BA_ "GenMsgCycleTime" BO_ 1087 100;
BA_ "GenMsgSendType" BO_ 1087 0;
BA_ "CANFD_BRS" BO_ 1087 1;
BA_ "VFrameFormat" BO_ 1087 14;
BA_ "GenMsgILSupport" BO_ 1189 1;
BA_ "MsgType" BO_ 1189 0;
BA_ "GenMsgCycleTime" BO_ 1189 100;
BA_ "GenMsgSendType" BO_ 1189 0;
BA_ "CANFD_BRS" BO_ 1189 1;
BA_ "VFrameFormat" BO_ 1189 14;
BA_ "GenMsgILSupport" BO_ 1192 1;
BA_ "MsgType" BO_ 1192 0;
BA_ "GenMsgCycleTime" BO_ 1192 100;
BA_ "GenMsgSendType" BO_ 1192 0;
BA_ "CANFD_BRS" BO_ 1192 1;
BA_ "VFrameFormat" BO_ 1192 14;
BA_ "GRC_History" BO_ 1235 "[{'approvedBy':'贾少辉','author':'吴俊祥','changesComments':'同步D01华为信号：\n新增信号EPS_2_AssociWithDriverModeSts','date':'2025/9/22','ecu':'EPS_2（0x4D3)','ecuName':'CGW','reviewedBy':'杨华','revision':'V1.2'},{'approvedBy':'贾少辉','author':'吴俊祥";
BA_ "GenMsgILSupport" BO_ 1235 1;
BA_ "MsgType" BO_ 1235 0;
BA_ "GenMsgCycleTime" BO_ 1235 100;
BA_ "GenMsgSendType" BO_ 1235 0;
BA_ "CANFD_BRS" BO_ 1235 1;
BA_ "VFrameFormat" BO_ 1235 14;
BA_ "GRC_History" BO_ 1330 "[{'approvedBy':'贾少辉','author':'吴俊祥','changesComments':'同步源网段：\nDWD_WorkSts信号初始值由0x1更新为0x0','date':'2026/2/7','ecu':'DWDM_1(0x532)','ecuName':'CGW','reviewedBy':'杨华','revision':'V1.5'}]";
BA_ "GenMsgILSupport" BO_ 1330 1;
BA_ "MsgType" BO_ 1330 0;
BA_ "GenMsgCycleTime" BO_ 1330 100;
BA_ "GenMsgSendType" BO_ 1330 0;
BA_ "CANFD_BRS" BO_ 1330 1;
BA_ "VFrameFormat" BO_ 1330 14;
BA_ "GRC_History" BO_ 1328 "[{'approvedBy':'贾少辉','author':'吴俊祥','changesComments':'同步源网段：\nRADAR_1_RadarWorkSt、RADAR_1_RadarDetectSts、RADAR_1_ParkingRadarSwSts、RADAR_1_AudibleBeepRate删除单位Bit','date':'2026/2/7','ecu':'RADAR_1（0x530)','ecuName':'ICC,ICC_ICE','revi";
BA_ "GenMsgILSupport" BO_ 1328 1;
BA_ "MsgType" BO_ 1328 0;
BA_ "GenMsgCycleTime" BO_ 1328 100;
BA_ "GenMsgSendType" BO_ 1328 0;
BA_ "CANFD_BRS" BO_ 1328 1;
BA_ "VFrameFormat" BO_ 1328 14;
BA_ "GRC_History" BO_ 1234 "[{'approvedBy':'贾少辉','author':'吴俊祥','changesComments':'同步D01华为信号：\n新增信号FRZCU_FRSeatliedownFb','date':'2025/9/22','ecu':'FRZCU_11(0x4D2)','ecuName':'CGW','reviewedBy':'杨华','revision':'V1.2'},{'approvedBy':'贾少辉','author':'吴俊祥','cha";
BA_ "GenMsgILSupport" BO_ 1234 1;
BA_ "MsgType" BO_ 1234 0;
BA_ "GenMsgCycleTime" BO_ 1234 100;
BA_ "GenMsgSendType" BO_ 1234 0;
BA_ "CANFD_BRS" BO_ 1234 1;
BA_ "VFrameFormat" BO_ 1234 14;
BA_ "GRC_History" BO_ 517 "[{'approvedBy':'贾少辉','author':'吴俊祥','changesComments':'同步T1J 华为信号：\n新增信号MFSR_KeyReset_SW','date':'2025/9/22','ecu':'MFSR_1（0x205)','ecuName':'CGW,ICC','reviewedBy':'杨华','revision':'V1.2'},{'approvedBy':'贾少辉','author':'吴俊祥','chan";
BA_ "GenMsgILSupport" BO_ 517 1;
BA_ "MsgType" BO_ 517 0;
BA_ "GenMsgCycleTime" BO_ 517 20;
BA_ "GenMsgSendType" BO_ 517 0;
BA_ "CANFD_BRS" BO_ 517 1;
BA_ "VFrameFormat" BO_ 517 14;
BA_ "GRC_History" BO_ 1096 "[{'approvedBy':'贾少辉','author':'吴俊祥','changesComments':'同步源网段：\nTMS_BT_Reduce_Wind_SpeedSts、TMS_First_BlowingSts、TMS_CirculationInTunnelsSts、TMS_crosscountry_coolingSts、TMS_ParkingAirConditioningStatus、TMS_CoolantFillSts、TMS_UVC_ControlS";
BA_ "GenMsgILSupport" BO_ 1096 1;
BA_ "MsgType" BO_ 1096 0;
BA_ "GenMsgCycleTime" BO_ 1096 100;
BA_ "GenMsgSendType" BO_ 1096 0;
BA_ "CANFD_BRS" BO_ 1096 1;
BA_ "VFrameFormat" BO_ 1096 14;
BA_ "GRC_History" BO_ 1240 "[{'approvedBy':'贾少辉','author':'吴俊祥','changesComments':'同步T1J 华为信号：\n新增信号TMS_AQSCOSts_2、TMS_AQSNO2Sts_2、TMS_AQSN02SnsrSts_2、TMS_AQSLifeCntr_2、TMS_AQSErrSts_2、TMS_AQSErrRespAQSM_2、TMS_AQSAirQlySts_2','date':'2025/9/22','ecu':'TDU_9（";
BA_ "GenMsgILSupport" BO_ 1240 1;
BA_ "MsgType" BO_ 1240 0;
BA_ "GenMsgCycleTime" BO_ 1240 100;
BA_ "GenMsgSendType" BO_ 1240 0;
BA_ "CANFD_BRS" BO_ 1240 1;
BA_ "VFrameFormat" BO_ 1240 14;
BA_ "GRC_History" BO_ 638 "[{'approvedBy':'贾少辉','author':'吴俊祥','changesComments':'同步T1J 华为信号：\n新增信号FRZCU_HoodSts_Valid','date':'2025/9/22','ecu':'FRZCU_9(0x27E)','ecuName':'CGW','reviewedBy':'杨华','revision':'V1.2'},{'approvedBy':'贾少辉','author':'吴俊祥','chang";
BA_ "GenMsgILSupport" BO_ 638 1;
BA_ "MsgType" BO_ 638 0;
BA_ "GenMsgCycleTime" BO_ 638 20;
BA_ "GenMsgSendType" BO_ 638 0;
BA_ "CANFD_BRS" BO_ 638 1;
BA_ "VFrameFormat" BO_ 638 14;
BA_ "GRC_History" BO_ 949 "[{'approvedBy':'贾少辉','author':'吴俊祥','changesComments':'根据电子电器FLZCU、FRZCU丁阁文、冯万涛需求\n新增7个信号CrankingRequest、CrankingRequestValidData、RemoteStartSts、RemoteStartFailCode、Start_StopRequest、StarterSwitchFlag、ISS_Switch，GL网段FL";
BA_ "GenMsgILSupport" BO_ 949 1;
BA_ "MsgType" BO_ 949 0;
BA_ "GenMsgDelayTime" BO_ 949 5;
BA_ "GenMsgNrOfRepetition" BO_ 949 3;
BA_ "GenMsgCycleTimeFast" BO_ 949 50;
BA_ "GenMsgCycleTime" BO_ 949 50;
BA_ "GenMsgSendType" BO_ 949 3;
BA_ "CANFD_BRS" BO_ 949 1;
BA_ "VFrameFormat" BO_ 949 14;
BA_ "GRC_History" BO_ 1028 "[{'approvedBy':'贾少辉','author':'吴俊祥','changesComments':'根据电子电器FLZCU、FRZCU丁阁文、冯万涛需求\n新增5个信号PEPS_UIRUnLockRequest、PEPS_WALLockRequest、SmartSystemWarning1_0、SmartSystemWarning2_0、Smartsystemwarning6_5，GL网段FLZCU接收','date':'";
BA_ "GenMsgILSupport" BO_ 1028 1;
BA_ "MsgType" BO_ 1028 0;
BA_ "GenMsgDelayTime" BO_ 1028 5;
BA_ "GenMsgNrOfRepetition" BO_ 1028 3;
BA_ "GenMsgCycleTimeFast" BO_ 1028 50;
BA_ "GenMsgCycleTime" BO_ 1028 100;
BA_ "GenMsgSendType" BO_ 1028 3;
BA_ "CANFD_BRS" BO_ 1028 1;
BA_ "VFrameFormat" BO_ 1028 14;
BA_ "GenMsgILSupport" BO_ 1104 1;
BA_ "MsgType" BO_ 1104 0;
BA_ "GenMsgCycleTime" BO_ 1104 100;
BA_ "GenMsgSendType" BO_ 1104 0;
BA_ "CANFD_BRS" BO_ 1104 1;
BA_ "VFrameFormat" BO_ 1104 14;
BA_ "GenMsgILSupport" BO_ 1271 1;
BA_ "MsgType" BO_ 1271 0;
BA_ "GenMsgCycleTime" BO_ 1271 100;
BA_ "GenMsgSendType" BO_ 1271 0;
BA_ "CANFD_BRS" BO_ 1271 1;
BA_ "VFrameFormat" BO_ 1271 14;
BA_ "Msg_ASIL" BO_ 587 5;
BA_ "GenMsgILSupport" BO_ 587 1;
BA_ "MsgType" BO_ 587 0;
BA_ "GenMsgCycleTime" BO_ 587 20;
BA_ "GenMsgSendType" BO_ 587 0;
BA_ "CANFD_BRS" BO_ 587 1;
BA_ "VFrameFormat" BO_ 587 14;
BA_ "GenMsgILSupport" BO_ 1180 1;
BA_ "MsgType" BO_ 1180 0;
BA_ "GenMsgCycleTime" BO_ 1180 100;
BA_ "GenMsgSendType" BO_ 1180 0;
BA_ "CANFD_BRS" BO_ 1180 1;
BA_ "VFrameFormat" BO_ 1180 14;
BA_ "GRC_History" BO_ 1269 "[{'approvedBy':'贾少辉','author':'吴俊祥','changesComments':'LISD_TransmitStatus信号更新为LISDTransmitStatus；\nLISD_DisplayStatus信号更新为LISDDisplayStatus；','date':'2026/2/7','ecu':'LISD_29(0x4F5）','ecuName':'ICC,ICC_ICE','reviewedBy':'杨华','revisi";
BA_ "GenMsgILSupport" BO_ 1269 1;
BA_ "MsgType" BO_ 1269 0;
BA_ "GenMsgCycleTime" BO_ 1269 100;
BA_ "GenMsgSendType" BO_ 1269 0;
BA_ "CANFD_BRS" BO_ 1269 1;
BA_ "VFrameFormat" BO_ 1269 14;
BA_ "GenMsgILSupport" BO_ 1233 1;
BA_ "MsgType" BO_ 1233 0;
BA_ "GenMsgCycleTime" BO_ 1233 100;
BA_ "GenMsgSendType" BO_ 1233 0;
BA_ "CANFD_BRS" BO_ 1233 1;
BA_ "VFrameFormat" BO_ 1233 14;
BA_ "GenMsgILSupport" BO_ 1169 1;
BA_ "MsgType" BO_ 1169 0;
BA_ "GenMsgCycleTime" BO_ 1169 100;
BA_ "GenMsgSendType" BO_ 1169 0;
BA_ "CANFD_BRS" BO_ 1169 1;
BA_ "VFrameFormat" BO_ 1169 14;
BA_ "GenMsgILSupport" BO_ 1427 1;
BA_ "MsgType" BO_ 1427 0;
BA_ "GenMsgCycleTime" BO_ 1427 100;
BA_ "GenMsgSendType" BO_ 1427 0;
BA_ "CANFD_BRS" BO_ 1427 1;
BA_ "VFrameFormat" BO_ 1427 14;
BA_ "GRC_History" BO_ 821 "[{'approvedBy':'贾少辉','author':'吴俊祥','changesComments':'新增：\n流水号:JTPPSYB-TB-2026-03360号\n1、ADS_5(0x335)新增信号“ADS_LightControl_335h”，ADCC发送。[智驾部-汤傲伟]','date':'2026/1/21','ecu':'ADS_5(0x335)','ecuName':'CGW','reviewedBy':'杨华',";
BA_ "GenMsgILSupport" BO_ 821 1;
BA_ "MsgType" BO_ 821 0;
BA_ "GenMsgCycleTime" BO_ 821 50;
BA_ "GenMsgSendType" BO_ 821 0;
BA_ "CANFD_BRS" BO_ 821 1;
BA_ "VFrameFormat" BO_ 821 14;
BA_ "GenSigInvalidValue" SG_ 1211 FLZCU_FLSeatHeiFb 127;
BA_ "GenSigSendType" SG_ 1211 FLZCU_FLSeatHeiFb 0;
BA_ "GenSigInvalidValue" SG_ 1211 FLZCU_FLSeatLvlFb 127;
BA_ "GenSigSendType" SG_ 1211 FLZCU_FLSeatLvlFb 0;
BA_ "GenSigInvalidValue" SG_ 1211 FLZCU_FLSeatBackAgFb 127;
BA_ "GenSigSendType" SG_ 1211 FLZCU_FLSeatBackAgFb 0;
BA_ "GenSigInvalidValue" SG_ 1211 FLZCU_FLSeatCushFb 127;
BA_ "GenSigSendType" SG_ 1211 FLZCU_FLSeatCushFb 0;
BA_ "GenSigInvalidValue" SG_ 1211 FLZCU_FLSeatLegSpprtFb 127;
BA_ "GenSigSendType" SG_ 1211 FLZCU_FLSeatLegSpprtFb 0;
BA_ "GenSigSendType" SG_ 1211 FLZCU_SeatNeedMemory 0;
BA_ "GenSigSendType" SG_ 1211 FLZCU_MemoryFb 0;
BA_ "GenSigSendType" SG_ 1211 FLZCU_RecoverFb 0;
BA_ "GenSigSendType" SG_ 1211 FLZCU_DriverSeatMovFailCause 0;
BA_ "GenSigSendType" SG_ 1211 FLZCU_CurrSeatMemoryPos 0;
BA_ "GenSigInvalidValue" SG_ 1429 FLZCU_VINcode_10 255;
BA_ "GenSigSendType" SG_ 1429 FLZCU_VINcode_10 0;
BA_ "GenSigInvalidValue" SG_ 1429 FLZCU_VINcode_11 255;
BA_ "GenSigSendType" SG_ 1429 FLZCU_VINcode_11 0;
BA_ "GenSigInvalidValue" SG_ 1429 FLZCU_VINcode_12 255;
BA_ "GenSigSendType" SG_ 1429 FLZCU_VINcode_12 0;
BA_ "GenSigInvalidValue" SG_ 1429 FLZCU_VINcode_13 255;
BA_ "GenSigSendType" SG_ 1429 FLZCU_VINcode_13 0;
BA_ "GenSigInvalidValue" SG_ 1429 FLZCU_VINcode_14 255;
BA_ "GenSigSendType" SG_ 1429 FLZCU_VINcode_14 0;
BA_ "GenSigInvalidValue" SG_ 1429 FLZCU_VINcode_15 255;
BA_ "GenSigSendType" SG_ 1429 FLZCU_VINcode_15 0;
BA_ "GenSigInvalidValue" SG_ 1429 FLZCU_VINcode_16 255;
BA_ "GenSigSendType" SG_ 1429 FLZCU_VINcode_16 0;
BA_ "GenSigInvalidValue" SG_ 1429 FLZCU_VINcode_17 255;
BA_ "GenSigSendType" SG_ 1429 FLZCU_VINcode_17 0;
BA_ "GenSigSendType" SG_ 1072 LHFdoorSts_430h 0;
BA_ "ASIL" SG_ 1072 LHFdoorSts_430h 2;
BA_ "GenSigSendType" SG_ 1072 LHFSeatBeltSW_430h 0;
BA_ "ASIL" SG_ 1072 LHFSeatBeltSW_430h 2;
BA_ "GenSigSendType" SG_ 1072 TrunkSts_430h 0;
BA_ "ASIL" SG_ 1072 TrunkSts_430h 2;
BA_ "GenSigStartValue" SG_ 1072 RLWinPosn_430h 127;
BA_ "GenSigInvalidValue" SG_ 1072 RLWinPosn_430h 127;
BA_ "GenSigSendType" SG_ 1072 RLWinPosn_430h 0;
BA_ "GenSigSendType" SG_ 1072 SeatHeatLevelsFL_430h 0;
BA_ "GenSigSendType" SG_ 1072 SeatHeatLevelsRL_430h 0;
BA_ "GenSigSendType" SG_ 1072 SeatVentLevelsFL_430h 0;
BA_ "GenSigSendType" SG_ 1072 SeatVentLevelsRL_430h 0;
BA_ "GenSigStartValue" SG_ 1072 FLWinPosn_430h 127;
BA_ "GenSigInvalidValue" SG_ 1072 FLWinPosn_430h 127;
BA_ "GenSigSendType" SG_ 1072 FLWinPosn_430h 0;
BA_ "GenSigSendType" SG_ 1072 FLZCU_FrontWiperMaintenanceSts 0;
BA_ "GenSigSendType" SG_ 1072 FLZCU_RearWiperMaintenanceSts 0;
BA_ "GenSigStartValue" SG_ 1043 EBS_U_BATT 16383;
BA_ "GenSigInvalidValue" SG_ 1043 EBS_U_BATT 16383;
BA_ "GenSigSendType" SG_ 1043 EBS_U_BATT 0;
BA_ "GenSigSendType" SG_ 1022 FLZCU_CarMode 0;
BA_ "GenSigSendType" SG_ 1022 FLZCU_SteerWhlposSts 0;
BA_ "GenSigSendType" SG_ 1022 FLZCU_MedStatusFb 0;
BA_ "GenSigSendType" SG_ 1022 FLZCU_MedFailCause 0;
BA_ "GenSigSendType" SG_ 1022 FLZCU_MedAreaFb 0;
BA_ "GenSigSendType" SG_ 1022 FLZCU_MedClosePrompt 0;
BA_ "GenSigSendType" SG_ 1022 FLZCU_NapArea2Fb 0;
BA_ "GenSigInvalidValue" SG_ 1022 FLZCU_2LSeatLvltargetCmd 127;
BA_ "GenSigSendType" SG_ 1022 FLZCU_2LSeatLvltargetCmd 0;
BA_ "GenSigInvalidValue" SG_ 1022 FLZCU_2LSeatBackAgtargetCmd 127;
BA_ "GenSigSendType" SG_ 1022 FLZCU_2LSeatBackAgtargetCmd 0;
BA_ "GenSigInvalidValue" SG_ 1022 FLZCU_2LSeatLegSpprttargetCmd 127;
BA_ "GenSigSendType" SG_ 1022 FLZCU_2LSeatLegSpprttargetCmd 0;
BA_ "GenSigSendType" SG_ 1022 FLZCU_FLWinThermalStatus 0;
BA_ "GenSigSendType" SG_ 1022 FLZCU_RLWinThermalStatus 0;
BA_ "GenSigSendType" SG_ 1022 FLZCU_MonoAmbLigSts 0;
BA_ "GenSigSendType" SG_ 1022 FLZCU_LogoChargingSts 0;
BA_ "GenSigInvalidValue" SG_ 1022 FLZCU_2RSeatLvltargetCmd 127;
BA_ "GenSigSendType" SG_ 1022 FLZCU_2RSeatLvltargetCmd 0;
BA_ "GenSigInvalidValue" SG_ 1022 FLZCU_2RSeatBackAgtargetCmd 127;
BA_ "GenSigSendType" SG_ 1022 FLZCU_2RSeatBackAgtargetCmd 0;
BA_ "GenSigInvalidValue" SG_ 1022 FLZCU_2RSeatLegSpprttargetCmd 127;
BA_ "GenSigSendType" SG_ 1022 FLZCU_2RSeatLegSpprttargetCmd 0;
BA_ "GenSigSendType" SG_ 1022 FLZCU_SeatVentLvlFL2 0;
BA_ "GenSigSendType" SG_ 1022 FLZCU_SeatVentLvlRL2 0;
BA_ "GenSigSendType" SG_ 1022 FLZCU_SeatHeatLvlFL2 0;
BA_ "GenSigSendType" SG_ 1022 FLZCU_SeatHeatLvlRL2 0;
BA_ "GenSigSendType" SG_ 1022 FLZCU_FLSitPosnSts 0;
BA_ "GenSigSendType" SG_ 1022 FLZCU_SteerOverHeatWarn 0;
BA_ "GenSigSendType" SG_ 1022 FLZCU_FLogolightInhibitSts 0;
BA_ "GenSigInvalidValue" SG_ 1022 MaintenanceOdometer_Backup_3FEh 16777215;
BA_ "GenSigSendType" SG_ 1022 MaintenanceOdometer_Backup_3FEh 0;
BA_ "GenSigStartValue" SG_ 1020 SAM_1_SteeringAngleSpeed 255;
BA_ "GenSigInvalidValue" SG_ 1020 SAM_1_SteeringAngleSpeed 255;
BA_ "GenSigSendType" SG_ 1020 SAM_1_SteeringAngleSpeed 0;
BA_ "GenSigStartValue" SG_ 1020 SAM_1_SteeringAngle 65535;
BA_ "GenSigInvalidValue" SG_ 1020 SAM_1_SteeringAngle 65535;
BA_ "GenSigSendType" SG_ 1020 SAM_1_SteeringAngle 0;
BA_ "GenSigInvalidValue" SG_ 1020 BMSH_MaxChgPwrPeak 4095;
BA_ "GenSigSendType" SG_ 1020 BMSH_MaxChgPwrPeak 0;
BA_ "GenSigInvalidValue" SG_ 1020 BMSH_MaxDchgPwrPeak 4095;
BA_ "GenSigSendType" SG_ 1020 BMSH_MaxDchgPwrPeak 0;
BA_ "GenSigStartValue" SG_ 1020 FMCU_8_ISGF_SpdAct 32767;
BA_ "GenSigInvalidValue" SG_ 1020 FMCU_8_ISGF_SpdAct 65535;
BA_ "GenSigSendType" SG_ 1020 FMCU_8_ISGF_SpdAct 0;
BA_ "ASIL" SG_ 1020 FMCU_8_ISGF_SpdAct 2;
BA_ "GenSigStartValue" SG_ 1020 RMCU_1_Speed 32767;
BA_ "GenSigInvalidValue" SG_ 1020 RMCU_1_Speed 65535;
BA_ "GenSigSendType" SG_ 1020 RMCU_1_Speed 0;
BA_ "ASIL" SG_ 1020 RMCU_1_Speed 4;
BA_ "GenSigStartValue" SG_ 1020 SAM_1_SteeringAngleVD 1;
BA_ "GenSigSendType" SG_ 1020 SAM_1_SteeringAngleVD 0;
BA_ "GenSigStartValue" SG_ 1020 SAM_1_SteeringAngleSpeedVD 1;
BA_ "GenSigSendType" SG_ 1020 SAM_1_SteeringAngleSpeedVD 0;
BA_ "GenSigStartValue" SG_ 1020 CSA_2_AllWarningInfo 7;
BA_ "GenSigSendType" SG_ 1020 CSA_2_AllWarningInfo 0;
BA_ "ASIL" SG_ 1020 CSA_2_AllWarningInfo 3;
BA_ "GenSigSendType" SG_ 1020 RMCU_1_TCURErrLvlDis 0;
BA_ "ASIL" SG_ 1020 RMCU_1_TCURErrLvlDis 1;
BA_ "GenSigSendType" SG_ 1020 ASU_2_sensorErrorSts 0;
BA_ "ASIL" SG_ 1020 ASU_2_sensorErrorSts 3;
BA_ "GenSigStartValue" SG_ 1020 ASU_2_LFHeight 1500;
BA_ "GenSigInvalidValue" SG_ 1020 ASU_2_LFHeight 4095;
BA_ "GenSigSendType" SG_ 1020 ASU_2_LFHeight 0;
BA_ "ASIL" SG_ 1020 ASU_2_LFHeight 3;
BA_ "GenSigStartValue" SG_ 1020 ASU_2_RFHeight 1500;
BA_ "GenSigInvalidValue" SG_ 1020 ASU_2_RFHeight 4095;
BA_ "GenSigSendType" SG_ 1020 ASU_2_RFHeight 0;
BA_ "ASIL" SG_ 1020 ASU_2_RFHeight 3;
BA_ "GenSigStartValue" SG_ 1020 ASU_2_LRHeight 1500;
BA_ "GenSigInvalidValue" SG_ 1020 ASU_2_LRHeight 4095;
BA_ "GenSigSendType" SG_ 1020 ASU_2_LRHeight 0;
BA_ "ASIL" SG_ 1020 ASU_2_LRHeight 3;
BA_ "GenSigStartValue" SG_ 1020 ASU_2_RRHeight 1500;
BA_ "GenSigInvalidValue" SG_ 1020 ASU_2_RRHeight 4095;
BA_ "GenSigSendType" SG_ 1020 ASU_2_RRHeight 0;
BA_ "ASIL" SG_ 1020 ASU_2_RRHeight 3;
BA_ "GenSigSendType" SG_ 1020 CSA_2_WiprFrntCmd 0;
BA_ "ASIL" SG_ 1020 CSA_2_WiprFrntCmd 2;
BA_ "GenSigSendType" SG_ 1035 VCC_1_OTASts 0;
BA_ "GenSigSendType" SG_ 1035 VCC_1_DriveMode 0;
BA_ "ASIL" SG_ 1035 VCC_1_DriveMode 3;
BA_ "GenSigSendType" SG_ 1075 VCC_2_ConfigurationMessageTrg 5;
BA_ "GenSigSendType" SG_ 1136 VCC_3_CRC 5;
BA_ "GenSigSendType" SG_ 1136 VCC_3_RollgCntr 5;
BA_ "GenSigSendType" SG_ 1136 VCC_3_Resd1 5;
BA_ "GenSigStartValue" SG_ 1136 VCC_3_SN 1;
BA_ "GenSigSendType" SG_ 1136 VCC_3_SN 5;
BA_ "GenSigSendType" SG_ 1196 TDL_SwitchSts 0;
BA_ "GenSigSendType" SG_ 1196 TDL_ColourModeSts 0;
BA_ "GenSigSendType" SG_ 1196 TDL_RhythmSwSts 0;
BA_ "GenSigSendType" SG_ 1196 TDL_ApiluminanceSts 0;
BA_ "GenSigSendType" SG_ 1196 TDL_VioceFunctionDone 0;
BA_ "GenSigSendType" SG_ 1196 TDL_FlowLightSwSts 0;
BA_ "GenSigSendType" SG_ 1196 TDL_FlowLightModeSts 0;
BA_ "GenSigSendType" SG_ 1196 TDL_RhythmModeSts 0;
BA_ "GenSigSendType" SG_ 1196 TDL_DOWWarningSts 0;
BA_ "GenSigSendType" SG_ 1196 TDL_AssociatedDrivingModeSts 0;
BA_ "GenSigStartValue" SG_ 1196 TDL_256ColourSts 127;
BA_ "GenSigSendType" SG_ 1196 TDL_256ColourSts 0;
BA_ "GenSigSendType" SG_ 1177 FuelTankLidSts 0;
BA_ "GenSigSendType" SG_ 1177 FuelTankLidLockFailureSts 0;
BA_ "GenSigSendType" SG_ 1177 FuelTankLidSensorFailureSts 0;
BA_ "GenSigSendType" SG_ 2015 Diag_Functional_REQ 2;
BA_ "GenSigSendType" SG_ 1109 CWC_1_CRC1 0;
BA_ "GenSigSendType" SG_ 1109 CWC_1_RollgCntr1 0;
BA_ "GenSigSendType" SG_ 1109 CWC_1_Resd1 0;
BA_ "GenSigSendType" SG_ 1109 CWC_ChargingSts 0;
BA_ "GenSigStartValue" SG_ 1109 CWC_workingSts 1;
BA_ "GenSigSendType" SG_ 1109 CWC_workingSts 0;
BA_ "GenSigSendType" SG_ 1109 CWC_Phoneforgotten 0;
BA_ "GenSigStartValue" SG_ 1109 CWC_Phoneforgotten_ON_OFF_Sts 1;
BA_ "GenSigSendType" SG_ 1109 CWC_Phoneforgotten_ON_OFF_Sts 0;
BA_ "GenSigSendType" SG_ 1109 CWC_1_ChrgFlt 0;
BA_ "GenSigSendType" SG_ 1109 CWC_ChargingSts_R 0;
BA_ "GenSigStartValue" SG_ 1109 CWC_workingSts_R 1;
BA_ "GenSigSendType" SG_ 1109 CWC_workingSts_R 0;
BA_ "GenSigSendType" SG_ 1109 CWC_Phoneforgotten_R 0;
BA_ "GenSigStartValue" SG_ 1109 CWC_Phoneforgotten_ON_OFF_Sts_R 1;
BA_ "GenSigSendType" SG_ 1109 CWC_Phoneforgotten_ON_OFF_Sts_R 0;
BA_ "GenSigSendType" SG_ 1109 CWC_1_ChrgFlt_R 0;
BA_ "GenSigSendType" SG_ 1288 CurrentTimeYear_508h 0;
BA_ "GenSigStartValue" SG_ 1288 CurrentTimeMonth_508h 1;
BA_ "GenSigSendType" SG_ 1288 CurrentTimeMonth_508h 0;
BA_ "GenSigStartValue" SG_ 1288 CurrentTimeDay_508h 1;
BA_ "GenSigSendType" SG_ 1288 CurrentTimeDay_508h 0;
BA_ "GenSigSendType" SG_ 1288 CurrentTimeHour_508h 0;
BA_ "GenSigSendType" SG_ 1288 CurrentTimeMinute_508h 0;
BA_ "GenSigSendType" SG_ 1288 CurrentTimeSecond_508h 0;
BA_ "GenSigSendType" SG_ 1063 TBOX_PetmodeSwitch 5;
BA_ "GenSigSendType" SG_ 1063 TBOX_SentinelModeSw 5;
BA_ "GenSigSendType" SG_ 1148 TBOX_GPSSwitchSts 0;
BA_ "GenSigSendType" SG_ 1148 TBOX_KeepWarmStrtMin 0;
BA_ "GenSigSendType" SG_ 1148 TimeToStartSentinelDayFed_47Ch 0;
BA_ "GenSigStartValue" SG_ 1148 TimeToStartSentinelHourFed_47Ch 30;
BA_ "GenSigInvalidValue" SG_ 1148 TimeToStartSentinelHourFed_47Ch 31;
BA_ "GenSigSendType" SG_ 1148 TimeToStartSentinelHourFed_47Ch 0;
BA_ "GenSigStartValue" SG_ 1148 TimeToStartSentinelMinutFed_47Ch 62;
BA_ "GenSigInvalidValue" SG_ 1148 TimeToStartSentinelMinutFed_47Ch 63;
BA_ "GenSigSendType" SG_ 1148 TimeToStartSentinelMinutFed_47Ch 0;
BA_ "GenSigStartValue" SG_ 1148 TimeToStopSentinelHourFed_47Ch 30;
BA_ "GenSigInvalidValue" SG_ 1148 TimeToStopSentinelHourFed_47Ch 31;
BA_ "GenSigSendType" SG_ 1148 TimeToStopSentinelHourFed_47Ch 0;
BA_ "GenSigStartValue" SG_ 1148 TimeToStopSentinelMinutFed_47Ch 62;
BA_ "GenSigInvalidValue" SG_ 1148 TimeToStopSentinelMinutFed_47Ch 63;
BA_ "GenSigSendType" SG_ 1148 TimeToStopSentinelMinutFed_47Ch 0;
BA_ "GenSigSendType" SG_ 1148 ReservationSentinelSts_Fed_47Ch 0;
BA_ "GenSigSendType" SG_ 1162 ONEBOX_1_G_CRC 0;
BA_ "GenSigSendType" SG_ 1162 ONEBOX_1_G_RollgCntr 0;
BA_ "GenSigInvalidValue" SG_ 1162 VehicleSpeedVSOSig 8191;
BA_ "GenSigSendType" SG_ 1162 VehicleSpeedVSOSig 0;
BA_ "ASIL" SG_ 1162 VehicleSpeedVSOSig 3;
BA_ "GenSigStartValue" SG_ 1162 VehicleSpeedVSOSigValidData 1;
BA_ "GenSigSendType" SG_ 1162 VehicleSpeedVSOSigValidData 0;
BA_ "ASIL" SG_ 1162 VehicleSpeedVSOSigValidData 3;
BA_ "GenSigSendType" SG_ 1162 ESPSwitchStatus 0;
BA_ "ASIL" SG_ 1162 ESPSwitchStatus 3;
BA_ "GenSigSendType" SG_ 1162 ABSActive 0;
BA_ "ASIL" SG_ 1162 ABSActive 3;
BA_ "GenSigSendType" SG_ 1162 ABSFailSts 0;
BA_ "ASIL" SG_ 1162 ABSFailSts 3;
BA_ "GenSigSendType" SG_ 1162 EBDFailSts 0;
BA_ "ASIL" SG_ 1162 EBDFailSts 3;
BA_ "GenSigSendType" SG_ 1162 TCSFailSts 0;
BA_ "ASIL" SG_ 1162 TCSFailSts 3;
BA_ "GenSigSendType" SG_ 1162 VDCFailSts 0;
BA_ "ASIL" SG_ 1162 VDCFailSts 3;
BA_ "GenSigSendType" SG_ 1162 TCSActive 0;
BA_ "ASIL" SG_ 1162 TCSActive 3;
BA_ "GenSigSendType" SG_ 1162 VDCActive 0;
BA_ "ASIL" SG_ 1162 VDCActive 3;
BA_ "GenSigSendType" SG_ 1162 BLRequestController 0;
BA_ "GenSigStartValue" SG_ 1202 FuelRollingCounter 255;
BA_ "GenSigInvalidValue" SG_ 1202 FuelRollingCounter 255;
BA_ "GenSigSendType" SG_ 1202 FuelRollingCounter 0;
BA_ "GenSigStartValue" SG_ 1202 MILSts 2;
BA_ "GenSigSendType" SG_ 1202 MILSts 0;
BA_ "GenSigSendType" SG_ 1202 GPFWarning 0;
BA_ "GenSigInvalidValue" SG_ 1202 EngineSpeed 2047;
BA_ "GenSigSendType" SG_ 1202 EngineSpeed 0;
BA_ "GenSigSendType" SG_ 1202 EngineSpeedValidData 0;
BA_ "GenSigStartValue" SG_ 1202 EPCSts 1;
BA_ "GenSigSendType" SG_ 1202 EPCSts 0;
BA_ "GenSigSendType" SG_ 1202 EMS_1_G_EngineSts 0;
BA_ "GenSigSendType" SG_ 1202 EMS_EngineSts_Actual 0;
BA_ "GenSigSendType" SG_ 1202 OilPressureWarningLamp 0;
BA_ "GenSigSendType" SG_ 1202 Activeheatingmode 0;
BA_ "ASIL" SG_ 1202 Activeheatingmode 1;
BA_ "GenSigSendType" SG_ 683 RHFDoorSts 0;
BA_ "ASIL" SG_ 683 RHFDoorSts 2;
BA_ "GenSigSendType" SG_ 683 FRZCU_1_ParkLightSts 0;
BA_ "GenSigStartValue" SG_ 683 FRWinPosn 127;
BA_ "GenSigInvalidValue" SG_ 683 FRWinPosn 127;
BA_ "GenSigSendType" SG_ 683 FRWinPosn 0;
BA_ "GenSigStartValue" SG_ 683 RRWinPosn 127;
BA_ "GenSigInvalidValue" SG_ 683 RRWinPosn 127;
BA_ "GenSigSendType" SG_ 683 RRWinPosn 0;
BA_ "GenSigSendType" SG_ 683 RHRDoorSts 0;
BA_ "ASIL" SG_ 683 RHRDoorSts 2;
BA_ "GenSigStartValue" SG_ 33 ACU_3_LongitudinalAcceleration 2000;
BA_ "GenSigInvalidValue" SG_ 33 ACU_3_LongitudinalAcceleration 65535;
BA_ "GenSigSendType" SG_ 33 ACU_3_LongitudinalAcceleration 0;
BA_ "ASIL" SG_ 33 ACU_3_LongitudinalAcceleration 3;
BA_ "GenSigStartValue" SG_ 33 ACU_3_LongitudinalAccelerationVD 3;
BA_ "GenSigSendType" SG_ 33 ACU_3_LongitudinalAccelerationVD 0;
BA_ "ASIL" SG_ 33 ACU_3_LongitudinalAccelerationVD 3;
BA_ "GenSigSendType" SG_ 33 ACU_3_CrashOutputSts 0;
BA_ "ASIL" SG_ 33 ACU_3_CrashOutputSts 3;
BA_ "GenSigStartValue" SG_ 1217 ASU_SysFailrSts_4C1h 1;
BA_ "GenSigSendType" SG_ 1217 ASU_SysFailrSts_4C1h 0;
BA_ "ASIL" SG_ 1217 ASU_SysFailrSts_4C1h 3;
BA_ "GenSigSendType" SG_ 1217 ASU_SuspCurrentLvl_4C1h 0;
BA_ "ASIL" SG_ 1217 ASU_SuspCurrentLvl_4C1h 3;
BA_ "GenSigSendType" SG_ 1217 ASU_ECASSysSts_4C1h 0;
BA_ "ASIL" SG_ 1217 ASU_ECASSysSts_4C1h 3;
BA_ "GenSigSendType" SG_ 1217 ASU_ECASErrSts_4C1h 0;
BA_ "ASIL" SG_ 1217 ASU_ECASErrSts_4C1h 3;
BA_ "GenSigSendType" SG_ 1217 ASU_SuspTarLvl_4C1h 0;
BA_ "ASIL" SG_ 1217 ASU_SuspTarLvl_4C1h 3;
BA_ "GenSigSendType" SG_ 1217 ASU_EasyEntryEna_4C1h 0;
BA_ "ASIL" SG_ 1217 ASU_EasyEntryEna_4C1h 3;
BA_ "GenSigSendType" SG_ 1217 ASU_CDCErrSts_4C1h 0;
BA_ "ASIL" SG_ 1217 ASU_CDCErrSts_4C1h 3;
BA_ "GenSigSendType" SG_ 1217 ASU_RearaxlewithTaildoorFb_4C1h 0;
BA_ "GenSigSendType" SG_ 1217 ASU_Overheat_warning_4C1h 0;
BA_ "GenSigSendType" SG_ 1217 ASU_MaintainMod_4C1h 0;
BA_ "ASIL" SG_ 1217 ASU_MaintainMod_4C1h 3;
BA_ "GenSigSendType" SG_ 1217 ASU_drivemodeheightlevFb_4C1h 0;
BA_ "GenSigSendType" SG_ 1217 ASU_HMIFailFb_4C1h 0;
BA_ "GenSigSendType" SG_ 1217 ASU_AssistPass_4C1h 0;
BA_ "GenSigInvalidValue" SG_ 1316 LHFTireTemperature 255;
BA_ "GenSigSendType" SG_ 1316 LHFTireTemperature 0;
BA_ "GenSigInvalidValue" SG_ 1316 RHFTireTemperature 255;
BA_ "GenSigSendType" SG_ 1316 RHFTireTemperature 0;
BA_ "GenSigInvalidValue" SG_ 1316 LHRTireTemperature 255;
BA_ "GenSigSendType" SG_ 1316 LHRTireTemperature 0;
BA_ "GenSigInvalidValue" SG_ 1316 LHFTirePressure 255;
BA_ "GenSigSendType" SG_ 1316 LHFTirePressure 0;
BA_ "GenSigInvalidValue" SG_ 1316 RHFTirePressure 255;
BA_ "GenSigSendType" SG_ 1316 RHFTirePressure 0;
BA_ "GenSigInvalidValue" SG_ 1316 LHRTirePressure 255;
BA_ "GenSigSendType" SG_ 1316 LHRTirePressure 0;
BA_ "GenSigInvalidValue" SG_ 1316 RHRTirePressure 255;
BA_ "GenSigSendType" SG_ 1316 RHRTirePressure 0;
BA_ "GenSigInvalidValue" SG_ 1316 RHRTireTemperature 255;
BA_ "GenSigSendType" SG_ 1316 RHRTireTemperature 0;
BA_ "GenSigSendType" SG_ 1324 TirePositionWarning_LHFTire 0;
BA_ "GenSigSendType" SG_ 1324 TirePositionWarning_RHFTire 0;
BA_ "GenSigSendType" SG_ 1324 TirePositionWarning_LHRTire 0;
BA_ "GenSigSendType" SG_ 1324 TirePositionWarning_RHRTire 0;
BA_ "GenSigSendType" SG_ 1324 TirePressureWarningLampSts 0;
BA_ "ASIL" SG_ 1324 TirePressureWarningLampSts 3;
BA_ "GenSigSendType" SG_ 1324 TirePressureSystemFailSts 0;
BA_ "ASIL" SG_ 1324 TirePressureSystemFailSts 3;
BA_ "GenSigSendType" SG_ 991 TMS_MotorLoopErrorLevel 0;
BA_ "GenSigSendType" SG_ 991 TMS_BatteryLoopErrorLevel 0;
BA_ "GenSigSendType" SG_ 1188 FrontDeforestDisplaySts 0;
BA_ "GenSigSendType" SG_ 1188 TMS_DisplayActive 0;
BA_ "GenSigSendType" SG_ 1188 TMS_ZoneSelectionDisplaySts 0;
BA_ "GenSigSendType" SG_ 1188 TMS_AutoDisplaySts 0;
BA_ "GenSigSendType" SG_ 1188 TMS_FiltertchangeDisplaySts 0;
BA_ "GenSigSendType" SG_ 1188 TMS_AUTODefrostOnSts 0;
BA_ "GenSigSendType" SG_ 1188 TMS_AUTODefrostDisplaySts 0;
BA_ "GenSigSendType" SG_ 1188 TMS_RefInSufDispSts 0;
BA_ "GenSigSendType" SG_ 1188 TMS_CooltInSufDispSts 0;
BA_ "GenSigSendType" SG_ 1188 TMS_DLOnOffSts 0;
BA_ "GenSigSendType" SG_ 1188 TMS_DROnOffSts 0;
BA_ "GenSigSendType" SG_ 1188 TMS_PLOnOffSts 0;
BA_ "GenSigSendType" SG_ 1188 WorkingSts 0;
BA_ "GenSigSendType" SG_ 1188 TMS_PROnOffSts 0;
BA_ "GenSigSendType" SG_ 1188 TMS_DCOnOffSts 0;
BA_ "GenSigSendType" SG_ 1188 TMS_ACFastCool 0;
BA_ "GenSigSendType" SG_ 1188 TMS_ACFastHeat 0;
BA_ "GenSigSendType" SG_ 1188 TMS_LoveRemind 0;
BA_ "GenSigSendType" SG_ 1188 TMS_InteCleanCar 0;
BA_ "GenSigSendType" SG_ 1188 TMS_ACVentilationSts 0;
BA_ "GenSigSendType" SG_ 1188 TMS_AutoAirCleanSts 0;
BA_ "GenSigSendType" SG_ 1188 PM25Sts 0;
BA_ "GenSigSendType" SG_ 1188 TMS_ACModeCustomSts 0;
BA_ "GenSigSendType" SG_ 1188 TMS_ACRequestDisplaySts 0;
BA_ "GenSigSendType" SG_ 1188 TMS_AUTODefLevelSts 0;
BA_ "GenSigSendType" SG_ 1188 TMS_KeepWarm 0;
BA_ "GenSigSendType" SG_ 1188 TMS_DSwingSts 0;
BA_ "GenSigSendType" SG_ 1188 TMS_PSwingSts 0;
BA_ "GenSigSendType" SG_ 1188 TMS_TuisongDispSts 0;
BA_ "GenSigStartValue" SG_ 1188 TMS_SetTemperature_L_C 31;
BA_ "GenSigInvalidValue" SG_ 1188 TMS_SetTemperature_L_C 31;
BA_ "GenSigSendType" SG_ 1188 TMS_SetTemperature_L_C 0;
BA_ "GenSigStartValue" SG_ 1188 TMS_SetTemperature_R_C 31;
BA_ "GenSigInvalidValue" SG_ 1188 TMS_SetTemperature_R_C 31;
BA_ "GenSigSendType" SG_ 1188 TMS_SetTemperature_R_C 0;
BA_ "GenSigStartValue" SG_ 1188 TMS_ModeAdjustDisplaySts 5;
BA_ "GenSigSendType" SG_ 1188 TMS_ModeAdjustDisplaySts 0;
BA_ "GenSigStartValue" SG_ 1188 TMS_CirculationModeDisplaySts 1;
BA_ "GenSigSendType" SG_ 1188 TMS_CirculationModeDisplaySts 0;
BA_ "GenSigStartValue" SG_ 1188 TMS_IncarTemp 254;
BA_ "GenSigSendType" SG_ 1188 TMS_IncarTemp 0;
BA_ "GenSigSendType" SG_ 1188 TMS_FliterLife 0;
BA_ "GenSigInvalidValue" SG_ 1188 TMS_DLSwingUpDwnWPosn 127;
BA_ "GenSigSendType" SG_ 1188 TMS_DLSwingUpDwnWPosn 0;
BA_ "GenSigInvalidValue" SG_ 1188 TMS_DLSwingLeRiWPosn 127;
BA_ "GenSigSendType" SG_ 1188 TMS_DLSwingLeRiWPosn 0;
BA_ "GenSigInvalidValue" SG_ 1188 TMS_DRSwingUpDwnWPosn 127;
BA_ "GenSigSendType" SG_ 1188 TMS_DRSwingUpDwnWPosn 0;
BA_ "GenSigInvalidValue" SG_ 1188 TMS_DRSwingLeRiWPosn 127;
BA_ "GenSigSendType" SG_ 1188 TMS_DRSwingLeRiWPosn 0;
BA_ "GenSigInvalidValue" SG_ 1188 TMS_PLSwingUpDwnWPosn 127;
BA_ "GenSigSendType" SG_ 1188 TMS_PLSwingUpDwnWPosn 0;
BA_ "GenSigInvalidValue" SG_ 1188 TMS_PLSwingLeRiWPosn 127;
BA_ "GenSigSendType" SG_ 1188 TMS_PLSwingLeRiWPosn 0;
BA_ "GenSigInvalidValue" SG_ 1188 TMS_PRSwingUpDwnWPosn 127;
BA_ "GenSigSendType" SG_ 1188 TMS_PRSwingUpDwnWPosn 0;
BA_ "GenSigInvalidValue" SG_ 1188 TMS_PRSwingLeRiWPosn 127;
BA_ "GenSigSendType" SG_ 1188 TMS_PRSwingLeRiWPosn 0;
BA_ "GenSigInvalidValue" SG_ 1188 TMS_DCSwingLeRiWPosn 127;
BA_ "GenSigSendType" SG_ 1188 TMS_DCSwingLeRiWPosn 0;
BA_ "GenSigSendType" SG_ 1188 AirSwingSts 0;
BA_ "GenSigSendType" SG_ 1188 TemperatureUnit 0;
BA_ "GenSigSendType" SG_ 1188 BlowAdvanceOnSts 0;
BA_ "GenSigSendType" SG_ 1188 BlowDelayOffSts 0;
BA_ "GenSigSendType" SG_ 1188 TMS_PM25_ExtSts 0;
BA_ "GenSigSendType" SG_ 1188 TMS_PM25_IncarSts 0;
BA_ "GenSigSendType" SG_ 1188 TMS_AQS_Sts 0;
BA_ "GenSigSendType" SG_ 1188 PM25overproofDisplaySts 0;
BA_ "GenSigSendType" SG_ 1188 AQSDisplaySts 0;
BA_ "GenSigSendType" SG_ 1188 PM25AutoRunSts 0;
BA_ "GenSigSendType" SG_ 1188 PM25AutoRunSetSts 0;
BA_ "GenSigSendType" SG_ 1188 FragranceWelcomeModeSts 0;
BA_ "GenSigSendType" SG_ 1188 FragranceDisplaysts 0;
BA_ "GenSigSendType" SG_ 1188 TMS_AQS_Level 0;
BA_ "GenSigSendType" SG_ 1188 ACRequestCommand 0;
BA_ "GenSigSendType" SG_ 1188 PM25_Outcar_Level 0;
BA_ "GenSigSendType" SG_ 1188 PM25_Incar_Level 0;
BA_ "GenSigStartValue" SG_ 1188 SetTemperature_L_F 31;
BA_ "GenSigInvalidValue" SG_ 1188 SetTemperature_L_F 31;
BA_ "GenSigSendType" SG_ 1188 SetTemperature_L_F 0;
BA_ "GenSigStartValue" SG_ 1188 SetTemperature_R_F 31;
BA_ "GenSigInvalidValue" SG_ 1188 SetTemperature_R_F 31;
BA_ "GenSigSendType" SG_ 1188 SetTemperature_R_F 0;
BA_ "GenSigSendType" SG_ 1188 TMS_PM25_incar 0;
BA_ "GenSigSendType" SG_ 1188 TMS_PM25_ext 0;
BA_ "GenSigSendType" SG_ 1188 TMS_KeepWarmMemoryFb 0;
BA_ "GenSigSendType" SG_ 612 CRC1_264h 0;
BA_ "GenSigSendType" SG_ 612 RollgCntr1_264h 0;
BA_ "GenSigSendType" SG_ 612 FltLamp_264h 0;
BA_ "GenSigSendType" SG_ 612 ParkLamp_264h 0;
BA_ "GenSigSendType" SG_ 612 ActrSt_264h 0;
BA_ "GenSigSendType" SG_ 612 RWUSt_264h 0;
BA_ "GenSigSendType" SG_ 612 TextDisp_264h 0;
BA_ "GenSigSendType" SG_ 612 IPB_EPBErrorStatus 0;
BA_ "GenSigSendType" SG_ 1193 AVHWarningMessage 0;
BA_ "GenSigSendType" SG_ 1193 CDPActive 0;
BA_ "GenSigSendType" SG_ 1193 HDCFailSts 0;
BA_ "GenSigSendType" SG_ 1193 HDCCtrlSts 0;
BA_ "GenSigSendType" SG_ 1193 AVHSts 0;
BA_ "GenSigSendType" SG_ 1193 AVHFailSts 0;
BA_ "GenSigSendType" SG_ 1193 FWAWarningSts 0;
BA_ "GenSigSendType" SG_ 1193 BrakeFluidSts 0;
BA_ "ASIL" SG_ 1193 BrakeFluidSts 3;
BA_ "GenSigSendType" SG_ 1193 BrakesystemFailSts 0;
BA_ "ASIL" SG_ 1193 BrakesystemFailSts 3;
BA_ "GenSigStartValue" SG_ 1197 CST_Status 1;
BA_ "GenSigSendType" SG_ 1197 CST_Status 0;
BA_ "GenSigSendType" SG_ 1197 BrakepedalFeelSts 0;
BA_ "GenSigStartValue" SG_ 1197 CST_SensitivitySts 2;
BA_ "GenSigSendType" SG_ 1197 CST_SensitivitySts 0;
BA_ "GenSigStartValue" SG_ 1200 SOC 255;
BA_ "GenSigInvalidValue" SG_ 1200 SOC 255;
BA_ "GenSigSendType" SG_ 1200 SOC 0;
BA_ "GenSigSendType" SG_ 1061 DriverSeatMsgStr_LvlSts 0;
BA_ "GenSigSendType" SG_ 1061 DriverSeatMsg_ModeSts 0;
BA_ "GenSigSendType" SG_ 1065 LeftSeatMsgStr_LvlSts 0;
BA_ "GenSigSendType" SG_ 1065 LeftSeatMsg_ModeSts 0;
BA_ "GenSigSendType" SG_ 1069 PassSeatMsgStr_LvlSts 0;
BA_ "GenSigSendType" SG_ 1069 PassSeatMsg_ModeSts 0;
BA_ "GenSigSendType" SG_ 1087 RightSeatMsgStr_LvlSts 0;
BA_ "GenSigSendType" SG_ 1087 RightSeatMsg_ModeSts 0;
BA_ "GenSigSendType" SG_ 1189 SRF_OperateSts 0;
BA_ "GenSigSendType" SG_ 1189 SRF_PositionSts 0;
BA_ "GenSigSendType" SG_ 1189 SRF_OverHeatProtect 0;
BA_ "GenSigSendType" SG_ 1189 SRF_Sunshade_OperateSts 0;
BA_ "GenSigSendType" SG_ 1189 Sunshade_OverHeatProtect 0;
BA_ "GenSigSendType" SG_ 1192 SRF_Sunroof_ActualSts 0;
BA_ "GenSigSendType" SG_ 1192 SRF_Sunshade_ActualSts 0;
BA_ "GenSigSendType" SG_ 1192 SRF_Sunshade_PositionSts 0;
BA_ "GenSigSendType" SG_ 1235 EPS_2_Steer_ReturnRmd_Sts 0;
BA_ "GenSigSendType" SG_ 1235 EPS_2_Steer_ReturnRmd 0;
BA_ "GenSigSendType" SG_ 1235 EPS_2_MFS_ShakeSts 0;
BA_ "GenSigSendType" SG_ 1330 DWD_TextDisp 0;
BA_ "GenSigSendType" SG_ 1330 DWD_SoundIndcn 0;
BA_ "GenSigSendType" SG_ 1330 LSensorFailSts 0;
BA_ "GenSigSendType" SG_ 1330 RSensorFailSts 0;
BA_ "GenSigSendType" SG_ 1330 DWD_Distance 0;
BA_ "GenSigSendType" SG_ 1330 DWD_Switch 0;
BA_ "GenSigSendType" SG_ 1328 RADAR_1_RadarDetectSts 0;
BA_ "GenSigSendType" SG_ 1328 RADAR_1_RadarWorkSts 0;
BA_ "GenSigSendType" SG_ 1328 RADAR_1_Resd1 0;
BA_ "GenSigStartValue" SG_ 1328 RADAR_1_LHRRadarSensorDistance 62;
BA_ "GenSigSendType" SG_ 1328 RADAR_1_LHRRadarSensorDistance 0;
BA_ "GenSigStartValue" SG_ 1328 RADAR_1_RHMRRadarSensorDistance 62;
BA_ "GenSigSendType" SG_ 1328 RADAR_1_RHMRRadarSensorDistance 0;
BA_ "GenSigStartValue" SG_ 1328 RADAR_1_LHMRRadarSensorDistance 62;
BA_ "GenSigSendType" SG_ 1328 RADAR_1_LHMRRadarSensorDistance 0;
BA_ "GenSigStartValue" SG_ 1328 RADAR_1_RHRRadarSensorDistance 62;
BA_ "GenSigSendType" SG_ 1328 RADAR_1_RHRRadarSensorDistance 0;
BA_ "GenSigStartValue" SG_ 1328 RADAR_1_LHFRadarSensorDistance 30;
BA_ "GenSigSendType" SG_ 1328 RADAR_1_LHFRadarSensorDistance 0;
BA_ "GenSigStartValue" SG_ 1328 RADAR_1_RHFRadarSensorDistance 30;
BA_ "GenSigSendType" SG_ 1328 RADAR_1_RHFRadarSensorDistance 0;
BA_ "GenSigSendType" SG_ 1328 RADAR_1_ParkingRadarSwSts 0;
BA_ "GenSigStartValue" SG_ 1328 RADAR_1_RHMFRadarSensorDistance 30;
BA_ "GenSigSendType" SG_ 1328 RADAR_1_RHMFRadarSensorDistance 0;
BA_ "GenSigStartValue" SG_ 1328 RADAR_1_LHMFRadarSensorDistance 30;
BA_ "GenSigSendType" SG_ 1328 RADAR_1_LHMFRadarSensorDistance 0;
BA_ "GenSigSendType" SG_ 1328 RADAR_1_AudibleBeepRate 0;
BA_ "GenSigInvalidValue" SG_ 1234 FRZCU_FRSeatHeiFb 127;
BA_ "GenSigSendType" SG_ 1234 FRZCU_FRSeatHeiFb 0;
BA_ "GenSigInvalidValue" SG_ 1234 FRZCU_FRSeatLvlFb 127;
BA_ "GenSigSendType" SG_ 1234 FRZCU_FRSeatLvlFb 0;
BA_ "GenSigInvalidValue" SG_ 1234 FRZCU_FRSeatBackAgFb 127;
BA_ "GenSigSendType" SG_ 1234 FRZCU_FRSeatBackAgFb 0;
BA_ "GenSigInvalidValue" SG_ 1234 FRZCU_FRSeatLegSpprtFb 127;
BA_ "GenSigSendType" SG_ 1234 FRZCU_FRSeatLegSpprtFb 0;
BA_ "GenSigSendType" SG_ 1234 FRZCU_FRWinSts 0;
BA_ "GenSigSendType" SG_ 1234 FRZCU_RRWinSts 0;
BA_ "GenSigInvalidValue" SG_ 1234 FRZCU_FRSeatLegRestAngleFb 127;
BA_ "GenSigSendType" SG_ 1234 FRZCU_FRSeatLegRestAngleFb 0;
BA_ "GenSigInvalidValue" SG_ 1234 FRZCU_FRSeatCushFb 127;
BA_ "GenSigSendType" SG_ 1234 FRZCU_FRSeatCushFb 0;
BA_ "GenSigSendType" SG_ 1234 FRZCU_FRSeatNeedMemory 0;
BA_ "GenSigSendType" SG_ 1234 FRZCU_FRMemoryFb 0;
BA_ "GenSigSendType" SG_ 1234 FRZCU_FRRecoverFb 0;
BA_ "GenSigSendType" SG_ 1234 FRZCU_EasyEntryExitFb 0;
BA_ "GenSigSendType" SG_ 1234 FRZCU_EnjoyableSeatWarning 0;
BA_ "GenSigSendType" SG_ 1234 FRZCU_EnjoyableSeatSts 0;
BA_ "GenSigSendType" SG_ 1234 SeatHeatLevelsFR_4D2h 0;
BA_ "GenSigSendType" SG_ 1234 SeatVentLevelsFR_4D2h 0;
BA_ "GenSigSendType" SG_ 1234 SeatHeatLevelsRR 0;
BA_ "GenSigSendType" SG_ 1234 SeatVentLevelsRR 0;
BA_ "GenSigSendType" SG_ 1234 NonPwrOffSwtSts_4D2h 0;
BA_ "GenSigInvalidValue" SG_ 1234 FRZCU_FRSeatFoldFb 127;
BA_ "GenSigSendType" SG_ 1234 FRZCU_FRSeatFoldFb 0;
BA_ "GenSigSendType" SG_ 517 MFSR_UP_SW 0;
BA_ "GenSigSendType" SG_ 517 MFSR_DW_SW 0;
BA_ "GenSigSendType" SG_ 517 MFSR_Left_SW 0;
BA_ "GenSigSendType" SG_ 517 MFSR_Right_SW 0;
BA_ "GenSigSendType" SG_ 517 MFSR_OK_SW 0;
BA_ "GenSigSendType" SG_ 517 MFSR_MENU_SW 0;
BA_ "GenSigSendType" SG_ 517 MFSR_Voice_SW 0;
BA_ "GenSigSendType" SG_ 517 MFSR_Customize 0;
BA_ "GenSigSendType" SG_ 1096 TMS_AirPurgeReminderSts 0;
BA_ "GenSigSendType" SG_ 1096 TMS_BT_Reduce_Wind_SpeedSts 0;
BA_ "GenSigSendType" SG_ 1096 TMS_First_BlowingSts 0;
BA_ "GenSigSendType" SG_ 1096 TMS_CirculationInTunnelsSts 0;
BA_ "GenSigSendType" SG_ 1096 TMS_crosscountry_coolingSts 0;
BA_ "GenSigSendType" SG_ 1096 TMS_ParkingAirConditioningStatus 0;
BA_ "GenSigSendType" SG_ 1096 TMS_CoolantFillSts 0;
BA_ "GenSigSendType" SG_ 1096 TMS_UVC_ControlSts 0;
BA_ "GenSigSendType" SG_ 1096 TMS_UVC_LuminanceSts 0;
BA_ "GenSigSendType" SG_ 1096 TMS_ICC_Lightoff_Sts 0;
BA_ "GenSigSendType" SG_ 1096 TMS_ICC_Memoff_Sts 0;
BA_ "GenSigSendType" SG_ 1096 TMS_keepwarmSet_TemperatureSts 0;
BA_ "GenSigSendType" SG_ 1096 TMS_AutoDefogActiveSts 0;
BA_ "GenSigSendType" SG_ 1096 TMS_BiochemicalFuncSts 0;
BA_ "GenSigSendType" SG_ 1096 TMS_TimedVentilationSts 0;
BA_ "GenSigSendType" SG_ 1240 TMS_CFSSwitchFb 0;
BA_ "GenSigStartValue" SG_ 1240 TDU_CFSPosOneType 15;
BA_ "GenSigSendType" SG_ 1240 TDU_CFSPosOneType 0;
BA_ "GenSigStartValue" SG_ 1240 TDU_CFSPosTwoType 15;
BA_ "GenSigSendType" SG_ 1240 TDU_CFSPosTwoType 0;
BA_ "GenSigStartValue" SG_ 1240 TDU_CFSPosThreeType 15;
BA_ "GenSigSendType" SG_ 1240 TDU_CFSPosThreeType 0;
BA_ "GenSigStartValue" SG_ 1240 TDU_CFSRunOut 15;
BA_ "GenSigSendType" SG_ 1240 TDU_CFSRunOut 0;
BA_ "GenSigStartValue" SG_ 1240 TMS_CFSShortWarn 15;
BA_ "GenSigSendType" SG_ 1240 TMS_CFSShortWarn 0;
BA_ "GenSigSendType" SG_ 1240 TMS_CFSLevelSetFb 0;
BA_ "GenSigSendType" SG_ 1240 TMS_CFSPosSetFb 0;
BA_ "GenSigInvalidValue" SG_ 1240 TMS_CFSPosOneLife 255;
BA_ "GenSigSendType" SG_ 1240 TMS_CFSPosOneLife 0;
BA_ "GenSigInvalidValue" SG_ 1240 TMS_CFSPosTwoLife 255;
BA_ "GenSigSendType" SG_ 1240 TMS_CFSPosTwoLife 0;
BA_ "GenSigInvalidValue" SG_ 1240 TMS_CFSPosThreeLife 255;
BA_ "GenSigSendType" SG_ 1240 TMS_CFSPosThreeLife 0;
BA_ "GenSigSendType" SG_ 1240 TMS_PM25SwitchFb 0;
BA_ "GenSigStartValue" SG_ 1240 TMS_ThrModeStsFb 7;
BA_ "GenSigSendType" SG_ 1240 TMS_ThrModeStsFb 0;
BA_ "GenSigStartValue" SG_ 1240 TMS_ThrSetTempFb_C 31;
BA_ "GenSigInvalidValue" SG_ 1240 TMS_ThrSetTempFb_C 31;
BA_ "GenSigSendType" SG_ 1240 TMS_ThrSetTempFb_C 0;
BA_ "GenSigSendType" SG_ 1240 TMS_ThrCLMSwitchFb 0;
BA_ "GenSigSendType" SG_ 1240 TMS_ThrAutoSwitchFb 0;
BA_ "GenSigSendType" SG_ 1240 TMS_ThrBlowSpeedLevelKeyStsFb 0;
BA_ "GenSigSendType" SG_ 638 FRZCU_HoodSts 0;
BA_ "ASIL" SG_ 638 FRZCU_HoodSts 2;
BA_ "GenSigSendType" SG_ 638 FRZCU_AuthenResult 0;
BA_ "GenSigSendType" SG_ 638 FRZCU_9_PowerMode 0;
BA_ "GenSigSendType" SG_ 638 FRZCU_TrunkSts 0;
BA_ "GenSigSendType" SG_ 638 FRZCU_HandleSwitchStsFL 0;
BA_ "GenSigSendType" SG_ 638 FRZCU_HandleSwitchStsFR 0;
BA_ "GenSigSendType" SG_ 638 FRZCU_HandleSwitchStsRR 0;
BA_ "GenSigSendType" SG_ 638 FRZCU_HandleSwitchStsRL 0;
BA_ "GenSigSendType" SG_ 638 SeatLength_target_Passenger 0;
BA_ "GenSigSendType" SG_ 638 SeatBackrest_target_Passenger 0;
BA_ "GenSigStartValue" SG_ 638 FRZCU_TrunkLockSts 3;
BA_ "GenSigSendType" SG_ 638 FRZCU_TrunkLockSts 0;
BA_ "GenSigStartValue" SG_ 638 FRZCU_HoodLockSts 3;
BA_ "GenSigSendType" SG_ 638 FRZCU_HoodLockSts 0;
BA_ "GenSigSendType" SG_ 638 FrontBackSpeedAdj_Cmd 0;
BA_ "GenSigSendType" SG_ 638 FRZCU_GloveboxSW 0;
BA_ "GenSigSendType" SG_ 638 FRZCU_FRReleaseLockSts 0;
BA_ "GenSigSendType" SG_ 638 FRZCU_RRReleaseLockSts 0;
BA_ "GenSigSendType" SG_ 638 FRZCU_PELockInKeyWarning 0;
BA_ "GenSigSendType" SG_ 638 FRZCU_PowerOFFWarning 0;
BA_ "GenSigSendType" SG_ 638 FRZCU_KeylessWarning 0;
BA_ "GenSigSendType" SG_ 638 FRZCU_OTAPwrDwnReqFb 0;
BA_ "GenSigSendType" SG_ 638 FRZCU_OTAPwrOnReqFb 0;
BA_ "GenSigSendType" SG_ 949 PEPS_InformationSource 0;
BA_ "GenSigSendType" SG_ 949 PEPS_OrderInformation 0;
BA_ "GenSigSendType" SG_ 949 PEPS_IDInformation 0;
BA_ "GenSigSendType" SG_ 949 PEPS_KeySts 0;
BA_ "GenSigSendType" SG_ 949 PEPS_ETRUnLockReq 4;
BA_ "GenSigSendType" SG_ 1028 PEPS_WelcomeON 4;
BA_ "GenSigSendType" SG_ 1028 PEPS_VehicleSearchReq 4;
BA_ "GenSigSendType" SG_ 1028 PEPS_SATOReminder 4;
BA_ "GenSigSendType" SG_ 1028 PEPS_PLGUnlockReq 4;
BA_ "GenSigSendType" SG_ 1028 PEPS_RKETrunkSts 0;
BA_ "GenSigSendType" SG_ 1028 PEPS_SSBInhibitCWCSts 0;
BA_ "GenSigSendType" SG_ 1028 PEPS_WirelessChargingCtrSts 0;
BA_ "GenSigSendType" SG_ 1028 PEPS_EmgyShutdown 0;
BA_ "GenSigSendType" SG_ 1028 PEPS_SSBInputFailure 0;
BA_ "GenSigSendType" SG_ 1028 PEPS_SmartSystemWarning1_1 0;
BA_ "GenSigSendType" SG_ 1028 PEPS_SmartSystemWarning2_2 0;
BA_ "GenSigSendType" SG_ 1028 PEPS_SmartSystemWarning3_1 0;
BA_ "GenSigSendType" SG_ 1028 PEPS_SmartSystemWarning3_2 0;
BA_ "GenSigSendType" SG_ 1028 PEPS_SmartSystemWarning4_2 0;
BA_ "GenSigSendType" SG_ 1028 PEPS_SmartSystemWarning4_3 0;
BA_ "GenSigSendType" SG_ 1028 PEPS_SystemWarning 0;
BA_ "GenSigSendType" SG_ 1028 PEPS_BLTKeyPESts 0;
BA_ "GenSigSendType" SG_ 1104 RLCR_2_CRC1 0;
BA_ "GenSigSendType" SG_ 1104 RLCR_2_RollgCntr1 0;
BA_ "GenSigSendType" SG_ 1104 RLCR_2_Resd1 0;
BA_ "GenSigSendType" SG_ 1104 RLCR_2_RCWWarn 0;
BA_ "GenSigSendType" SG_ 1104 RLCR_2_RCTAWarn 0;
BA_ "GenSigSendType" SG_ 1104 RLCR_2_BSDLCWONOFFSts 0;
BA_ "GenSigSendType" SG_ 1104 RLCR_2_DOWONOFFSts 0;
BA_ "GenSigSendType" SG_ 1104 RLCR_2_RCWONOFFSts 0;
BA_ "GenSigSendType" SG_ 1104 RLCR_2_RCTARCTBONOFFSts 0;
BA_ "GenSigSendType" SG_ 1271 RRCR_2_CRC1 0;
BA_ "GenSigSendType" SG_ 1271 RRCR_2_RollgCntr1 0;
BA_ "GenSigSendType" SG_ 1271 RRCR_2_Resd1 0;
BA_ "GenSigSendType" SG_ 1271 RRCR_2_RCWWarn 0;
BA_ "GenSigSendType" SG_ 1271 RRCR_2_RCTAWarn 0;
BA_ "GenSigSendType" SG_ 1271 RRCR_2_BSDLCWONOFFSts 0;
BA_ "GenSigSendType" SG_ 1271 RRCR_2_DOWONOFFSts 0;
BA_ "GenSigSendType" SG_ 1271 RRCR_2_RCWONOFFSts 0;
BA_ "GenSigSendType" SG_ 1271 RRCR_2_RCTARCTBONOFFSts 0;
BA_ "GenSigInvalidValue" SG_ 587 ONEBOX_4_LHFWheelSpeedRPM 65535;
BA_ "GenSigSendType" SG_ 587 ONEBOX_4_LHFWheelSpeedRPM 0;
BA_ "ASIL" SG_ 587 ONEBOX_4_LHFWheelSpeedRPM 5;
BA_ "GenSigInvalidValue" SG_ 587 ONEBOX_4_RHFWheelSpeedRPM 65535;
BA_ "GenSigSendType" SG_ 587 ONEBOX_4_RHFWheelSpeedRPM 0;
BA_ "ASIL" SG_ 587 ONEBOX_4_RHFWheelSpeedRPM 5;
BA_ "GenSigInvalidValue" SG_ 587 LHRWheelSpeedRPM 65535;
BA_ "GenSigSendType" SG_ 587 LHRWheelSpeedRPM 0;
BA_ "ASIL" SG_ 587 LHRWheelSpeedRPM 3;
BA_ "GenSigInvalidValue" SG_ 587 RHRWheelSpeedRPM 65535;
BA_ "GenSigSendType" SG_ 587 RHRWheelSpeedRPM 0;
BA_ "ASIL" SG_ 587 RHRWheelSpeedRPM 3;
BA_ "GenSigSendType" SG_ 587 LHRPulseCounterFailSts 0;
BA_ "ASIL" SG_ 587 LHRPulseCounterFailSts 3;
BA_ "GenSigSendType" SG_ 587 LHRPulseCounter 0;
BA_ "ASIL" SG_ 587 LHRPulseCounter 3;
BA_ "GenSigSendType" SG_ 587 RHRPulseCounterFailSts 0;
BA_ "ASIL" SG_ 587 RHRPulseCounterFailSts 3;
BA_ "GenSigSendType" SG_ 587 RHRPulseCounter 0;
BA_ "ASIL" SG_ 587 RHRPulseCounter 3;
BA_ "GenSigSendType" SG_ 587 RHFPulseCounterFailSts 0;
BA_ "ASIL" SG_ 587 RHFPulseCounterFailSts 3;
BA_ "GenSigSendType" SG_ 587 RHFPulseCounter 0;
BA_ "ASIL" SG_ 587 RHFPulseCounter 3;
BA_ "GenSigSendType" SG_ 587 LHFPulseCounterFailSts 0;
BA_ "ASIL" SG_ 587 LHFPulseCounterFailSts 3;
BA_ "GenSigSendType" SG_ 587 LHFPulseCounter 0;
BA_ "ASIL" SG_ 587 LHFPulseCounter 3;
BA_ "GenSigInvalidValue" SG_ 587 LHFWheelDriveDirection 4;
BA_ "GenSigSendType" SG_ 587 LHFWheelDriveDirection 0;
BA_ "ASIL" SG_ 587 LHFWheelDriveDirection 3;
BA_ "GenSigInvalidValue" SG_ 587 RHFWheelDriveDirection 4;
BA_ "GenSigSendType" SG_ 587 RHFWheelDriveDirection 0;
BA_ "ASIL" SG_ 587 RHFWheelDriveDirection 3;
BA_ "GenSigInvalidValue" SG_ 587 LHRWheelDriveDirection 4;
BA_ "GenSigSendType" SG_ 587 LHRWheelDriveDirection 0;
BA_ "ASIL" SG_ 587 LHRWheelDriveDirection 3;
BA_ "GenSigInvalidValue" SG_ 587 RHRWheelDriveDirection 4;
BA_ "GenSigSendType" SG_ 587 RHRWheelDriveDirection 0;
BA_ "ASIL" SG_ 587 RHRWheelDriveDirection 3;
BA_ "GenSigSendType" SG_ 1180 ACU_1_CRC1 0;
BA_ "GenSigSendType" SG_ 1180 ACU_1_RollgCntr1 0;
BA_ "GenSigSendType" SG_ 1180 ACU_1_Resd1 0;
BA_ "GenSigStartValue" SG_ 1180 ACU_1_AirBagFailSts 3;
BA_ "GenSigSendType" SG_ 1180 ACU_1_AirBagFailSts 0;
BA_ "GenSigSendType" SG_ 1180 ACU_1_ThdRowLBeltWarning 0;
BA_ "GenSigSendType" SG_ 1180 ACU_1_ThdRowRBeltWarning 0;
BA_ "GenSigSendType" SG_ 1180 ACU_1_PsngrSeatBeltWarning 0;
BA_ "GenSigSendType" SG_ 1180 ACU_1_SecRowLBeltWarning 0;
BA_ "GenSigSendType" SG_ 1180 ACU_1_SecRowMBeltWarning 0;
BA_ "GenSigSendType" SG_ 1180 ACU_1_SecRowRBeltWarning 0;
BA_ "GenSigSendType" SG_ 1180 ABM_1_Rollover_Status 0;
BA_ "ASIL" SG_ 1180 ABM_1_Rollover_Status 2;
BA_ "GenSigSendType" SG_ 1180 ACU_1_PsngrSeatOccupiedSts 0;
BA_ "GenSigSendType" SG_ 1269 LISDShowCMDSts 0;
BA_ "GenSigSendType" SG_ 1269 LISDShowModeSts 0;
BA_ "GenSigSendType" SG_ 1269 LISDTransmitStatus 0;
BA_ "GenSigSendType" SG_ 1269 LISDDisplayStatus 0;
BA_ "GenSigSendType" SG_ 1269 LISD_ParkingShowModSts 0;
BA_ "GenSigSendType" SG_ 1269 LISD_ParkingShowCMDSts 0;
BA_ "GenSigSendType" SG_ 1233 RISDShowCMDSts 0;
BA_ "GenSigSendType" SG_ 1233 RISDShowModeSts 0;
BA_ "GenSigSendType" SG_ 1233 RISD_TransmitStatus 0;
BA_ "GenSigSendType" SG_ 1233 RISD_DisplayStatus 0;
BA_ "GenSigSendType" SG_ 1233 RISD_ParkingShowModSts 0;
BA_ "GenSigSendType" SG_ 1233 RISD_ParkingShowCMDSts 0;
BA_ "GenSigSendType" SG_ 1169 LC_DIYMusicShowModSts 0;
BA_ "GenSigSendType" SG_ 1169 LC_RandomMusicShowSts 0;
BA_ "GenSigSendType" SG_ 1169 LC_LiShowModSts 0;
BA_ "GenSigStartValue" SG_ 1427 ILCF_1_LogoParkingSts 1;
BA_ "GenSigSendType" SG_ 1427 ILCF_1_LogoParkingSts 0;
BA_ "GenSigSendType" SG_ 1427 ILCF_1_LogoChargingSts 0;
BA_ "GenSigSendType" SG_ 1427 ILCF_1_DIYMusicShowModSts 0;
BA_ "GenSigSendType" SG_ 1427 ILCF_1_RandomMusicShowSts 0;
BA_ "GenSigStartValue" SG_ 1427 ILCF_1_LogoColorAdjSts 117;
BA_ "GenSigSendType" SG_ 1427 ILCF_1_LogoColorAdjSts 0;
BA_ "GenSigSendType" SG_ 821 ADS_5_CRC1 0;
BA_ "GenSigSendType" SG_ 821 ADS_5_RollgCntr1 0;
BA_ "GenSigSendType" SG_ 821 ADS_5_Resd1 0;
BA_ "GenSigSendType" SG_ 821 ADS_5_ILOASts 0;
BA_ "GenSigSendType" SG_ 821 ADS_5_ICAQuitReason 0;
BA_ "GenSigSendType" SG_ 821 ADS_5_ISLISt 0;
BA_ "GenSigSendType" SG_ 821 ADS_5_ILOATextInfo 0;
BA_ "GenSigSendType" SG_ 821 ADS_5_ILOAActdirection 0;
BA_ "GenSigSendType" SG_ 821 ADS_5_LKS_warning 0;
BA_ "GenSigSendType" SG_ 821 ADS_5_ISLIOverSpeedWarn 0;
BA_ "GenSigSendType" SG_ 821 ADS_5_ISLISpeedLimitSign 0;
BA_ "GenSigSendType" SG_ 821 ADS_5_EgoLeftLineHeatgAg 0;
BA_ "GenSigSendType" SG_ 821 ADS_5_EgoLeLineID 0;
BA_ "GenSigSendType" SG_ 821 ADS_5_EgoLeLineColor 0;
BA_ "GenSigSendType" SG_ 821 ADS_5_EgoLeLineTyp 0;
BA_ "GenSigSendType" SG_ 821 ADS_5_EgoLeLineHozlDst 0;
BA_ "GenSigSendType" SG_ 821 ADS_5_CRC2 0;
BA_ "GenSigSendType" SG_ 821 ADS_5_RollgCntr2 0;
BA_ "GenSigSendType" SG_ 821 ADS_5_Resd2 0;
BA_ "GenSigSendType" SG_ 821 ADS_5_NeborLeLineID 0;
BA_ "GenSigSendType" SG_ 821 ADS_5_NeborLeLineColor 0;
BA_ "GenSigSendType" SG_ 821 ADS_5_NeborLeLineTyp 0;
BA_ "GenSigSendType" SG_ 821 ADS_5_EgoLeLineCrvt 0;
BA_ "GenSigSendType" SG_ 821 ADS_5_NeborLeLineHozlDst 0;
BA_ "GenSigSendType" SG_ 821 ADS_5_NeborRiLineID 0;
BA_ "GenSigSendType" SG_ 821 ADS_5_NeborRiLineColor 0;
BA_ "GenSigSendType" SG_ 821 ADS_5_NeborRiLineTyp 0;
BA_ "GenSigSendType" SG_ 821 ADS_5_NeborLeLineCrvt 0;
BA_ "GenSigSendType" SG_ 821 ADS_5_NeborRiLineHozlDst 0;
BA_ "GenSigSendType" SG_ 821 ADS_5_CRC3 0;
BA_ "GenSigSendType" SG_ 821 ADS_5_RollgCntr3 0;
BA_ "GenSigSendType" SG_ 821 ADS_5_Resd3 0;
BA_ "GenSigSendType" SG_ 821 ADS_5_ELKSettingSt 0;
BA_ "GenSigSendType" SG_ 821 ADS_5_LDWLDPSnvtySet 0;
BA_ "GenSigSendType" SG_ 821 ADS_5_LDWWarnType 0;
BA_ "GenSigSendType" SG_ 821 ADS_5_NeborRiLineCrvt 0;
BA_ "GenSigSendType" SG_ 821 ADS_5_IESSwtSet 0;
BA_ "GenSigSendType" SG_ 821 ADS_5_IHCSettingSt 0;
BA_ "GenSigSendType" SG_ 821 ADS_5_ISLIWarningMod 0;
BA_ "GenSigSendType" SG_ 821 ADS_5_ICAEnableBtnSts 0;
BA_ "GenSigSendType" SG_ 821 ADS_5_FCM_Camera_textinfo 0;
BA_ "GenSigSendType" SG_ 821 ADS_5_EgoRiLineID 0;
BA_ "GenSigSendType" SG_ 821 ADS_5_EgoRiLineTyp 0;
BA_ "GenSigSendType" SG_ 821 ADS_5_EgoRiLineColor 0;
BA_ "GenSigInvalidValue" SG_ 821 ADS_5_EgoRiLineHozlDst 511;
BA_ "GenSigSendType" SG_ 821 ADS_5_EgoRiLineHozlDst 0;
BA_ "GenSigSendType" SG_ 821 ADS_5_CRC4 0;
BA_ "GenSigSendType" SG_ 821 ADS_5_RollgCntr4 0;
BA_ "GenSigSendType" SG_ 821 ADS_5_Resd4 0;
BA_ "GenSigInvalidValue" SG_ 821 ADS_5_EgoRightLineHeatgAg 511;
BA_ "GenSigSendType" SG_ 821 ADS_5_EgoRightLineHeatgAg 0;
BA_ "GenSigInvalidValue" SG_ 821 ADS_5_EgoRiLineCrvt 1023;
BA_ "GenSigSendType" SG_ 821 ADS_5_EgoRiLineCrvt 0;
BA_ "GenSigInvalidValue" SG_ 821 ADS_5_NeborLeftLineHeatgAg 511;
BA_ "GenSigSendType" SG_ 821 ADS_5_NeborLeftLineHeatgAg 0;
BA_ "GenSigInvalidValue" SG_ 821 ADS_5_NeborRightLineHeatgAg 511;
BA_ "GenSigSendType" SG_ 821 ADS_5_NeborRightLineHeatgAg 0;
VAL_ 1211 FLZCU_SeatNeedMemory 0 "NO Request" 1 "Request" ;
VAL_ 1211 FLZCU_MemoryFb 0 "Not Active" 1 "Success" 2 "Fail" 3 "Ongoing" ;
VAL_ 1211 FLZCU_RecoverFb 0 "Not Active" 1 "Success" 2 "Fail" 3 "Ongoing" ;
VAL_ 1211 FLZCU_DriverSeatMovFailCause 0 "Not active" 1 "Not Learned" 2 "Antipinch event" 3 "Hard Switch Not Released" 4 "Gear Not P" 5 "Motor Circuit Failure" 6 "Low Priority" ;
VAL_ 1211 FLZCU_CurrSeatMemoryPos 0 "Not Active" 1 "ID1_Pos1" 2 "ID1_Pos2" 3 "ID1_Pos3" 4 "ID2_Pos1" 5 "ID2_Pos2" 6 "ID2_Pos3" 7 "ID3_Pos1" 8 "ID3_Pos2" 9 "ID3_Pos3" 10 "ID4_Pos1" 11 "ID4_Pos2" 12 "ID4 Pos3" 13 "ID5 Pos1" 14 "ID5_Pos2" 15 "ID5_Pos3" 16 "NOID_Pos1" 17 "NOID_Pos2" 18 "NOID_Pos3" ;
VAL_ 1072 LHFdoorSts_430h 0 "Close" 1 "Ajar" 2 "full_open" 3 "Reserved" ;
VAL_ 1072 LHFSeatBeltSW_430h 0 "Not Active" 1 "Active" ;
VAL_ 1072 TrunkSts_430h 0 "Close" 1 "Ajar" 2 "full_open" 3 "Reserved" ;
VAL_ 1072 RLWinPosn_430h 127 "Invalid" ;
VAL_ 1072 SeatHeatLevelsFL_430h 0 "OFF" 1 "Level1" 2 "Level2" 3 "Level3" ;
VAL_ 1072 SeatHeatLevelsRL_430h 0 "OFF" 1 "Level1" 2 "Level2" 3 "Level3" ;
VAL_ 1072 SeatVentLevelsFL_430h 0 "OFF" 1 "Level1" 2 "Level2" 3 "Level3" ;
VAL_ 1072 SeatVentLevelsRL_430h 0 "OFF" 1 "Level1" 2 "Level2" 3 "Level3" ;
VAL_ 1072 FLWinPosn_430h 127 "Invalid" ;
VAL_ 1072 FLZCU_FrontWiperMaintenanceSts 0 "Not Active" 1 "ON" 2 "OFF" ;
VAL_ 1072 FLZCU_RearWiperMaintenanceSts 0 "Not Active" 1 "ON" 2 "OFF" ;
VAL_ 1043 EBS_U_BATT 16383 "Invalid" ;
VAL_ 1022 FLZCU_CarMode 0 "Normal Mode" 1 "Factory Mode" 2 "Transport Mode" 3 "Exhibition Mode" 4 "Reserved" 5 "Reserved" 6 "Reserved" 7 "Not active" ;
VAL_ 1022 FLZCU_SteerWhlposSts 0 "Not Active" 1 "Elongation regulation" 2 "Shortening in regulation" 3 "Angle elevation" 4 "Angle centering" ;
VAL_ 1022 FLZCU_MedStatusFb 0 "Not Active" 1 "ON" 2 "OFF" ;
VAL_ 1022 FLZCU_MedFailCause 0 "Not Active" 1 "Gear Not P" 2 "Vehicle Speed#0km/h" 3 "Hood Unlock" 4 "Trunk Unlock" 5 "FLDoor Unlock" 6 "FRDoor Unlock" 7 "RLDoor Unlock" 8 "RRDoor Unlock" 9 "Low Voltage Battery Voltage Low" 10 "High Voltage Battery Low" 11 "Brake Pedal Depressed" 12 "PowerMode Not Comfortable" ;
VAL_ 1022 FLZCU_MedAreaFb 0 "Not Active" 1 "Front Left" 2 "Front Right" 3 "Front Left and Right" 4 "2Row Left" 5 "2Row Right" 6 "2Row Left and 2Row Right" 7 "Front Left and 2Row Right" 8 "Front Right and 2Row Left" 9 "Front Left and 2Row Left" 10 "Front Right and 2Row Right" ;
VAL_ 1022 FLZCU_MedClosePrompt 0 "Not Active" 1 "Low Voltage Battery Low" 2 "High Voltage Battery Low" ;
VAL_ 1022 FLZCU_NapArea2Fb 0 "Not Active" 1 "2Row Left" 2 "2Row Right" 3 "2Row Left and Right" 4 "Front Left and 2Row Right" 5 "Front Right and 2Row Left" 6 "Front Left and 2Row Left" 7 "Front Right and 2Row Right" ;
VAL_ 1022 FLZCU_FLWinThermalStatus 0 "Normal" 1 "Thermal protection" ;
VAL_ 1022 FLZCU_RLWinThermalStatus 0 "Normal" 1 "Thermal protection" ;
VAL_ 1022 FLZCU_MonoAmbLigSts 0 "OFF" 1 "ON" ;
VAL_ 1022 FLZCU_LogoChargingSts 0 "Not Active" 1 "ON" 2 "OFF" 3 "Reserved" ;
VAL_ 1022 FLZCU_SeatVentLvlFL2 0 "Not Active" 1 "OFF" 2 "Level1" 3 "Level2" 4 "Level3" 5 "Level4" 6 "Level5" 7 "Level6" 8 "Level7" 9 "Level8" 10 "Level9" ;
VAL_ 1022 FLZCU_SeatVentLvlRL2 0 "Not Active" 1 "OFF" 2 "Level1" 3 "Level2" 4 "Level3" 5 "Level4" 6 "Level5" 7 "Level6" 8 "Level7" 9 "Level8" 10 "Level9" ;
VAL_ 1022 FLZCU_SeatHeatLvlFL2 0 "Not Active" 1 "OFF" 2 "Level1" 3 "Level2" 4 "Level3" 5 "Level4" 6 "Level5" 7 "Level6" 8 "Level7" 9 "Level8" 10 "Level9" ;
VAL_ 1022 FLZCU_SeatHeatLvlRL2 0 "Not Active" 1 "OFF" 2 "Level1" 3 "Level2" 4 "Level3" 5 "Level4" 6 "Level5" 7 "Level6" 8 "Level7" 9 "Level8" 10 "Level9" ;
VAL_ 1022 FLZCU_FLSitPosnSts 0 "Not Active" 1 "Location1" 2 "Location2" 3 "Location3" 4 "FaceID" ;
VAL_ 1022 FLZCU_SteerOverHeatWarn 0 "Not Active" 1 "Active" ;
VAL_ 1022 FLZCU_FLogolightInhibitSts 0 "Permit" 1 "Inhibit" ;
VAL_ 1022 MaintenanceOdometer_Backup_3FEh 16777215 "Invalid" ;
VAL_ 1020 BMSH_MaxChgPwrPeak 4095 "Invalid" ;
VAL_ 1020 BMSH_MaxDchgPwrPeak 4095 "Invalid" ;
VAL_ 1020 FMCU_8_ISGF_SpdAct 65535 "Invalid" ;
VAL_ 1020 RMCU_1_Speed 65535 "Invalid" ;
VAL_ 1020 CSA_2_AllWarningInfo 0 "No error" 1 "First grade failure of gear shift mechanism" 2 "Second grade failure of gear shift mechanism" 3 "Third grade failure of gear shift mechanism(Reserved)" 4 "Please check the position of the gear shift" 5 "Reserved" 6 "Reserved" 7 "Reserved" ;
VAL_ 1020 RMCU_1_TCURErrLvlDis 0 "No Error" 1 "Err_Level1" 2 "Err_Level2" 3 "Err_Level3" 4 "Err_Level4" ;
VAL_ 1020 ASU_2_sensorErrorSts 0 "all four sensors no fault" 1 "RR sensor faulty" 2 "LR sensor faulty" 3 "RR and LR sensors faulty" 4 "RF sensor faulty" 5 "RF and RR sensor fault" 6 "RF and LR sensors  faulty" 7 "RF LR and RR sensors  faulty" 8 "LF sensor fault" 9 "LF and RR sensor fault" 10 "LF and LR sensor fault" 11 "LF LR and RR sensors are faulty" 12 "LF and RF sensor fault" 13 "LF RF and RR sensors are faulty" 14 "LF RF and LR sensors are faulty" 15 "four sensors are faulty" ;
VAL_ 1020 ASU_2_LFHeight 4095 "Invalid" ;
VAL_ 1020 ASU_2_RFHeight 4095 "Invalid" ;
VAL_ 1020 ASU_2_LRHeight 4095 "Invalid" ;
VAL_ 1020 ASU_2_RRHeight 4095 "Invalid" ;
VAL_ 1020 CSA_2_WiprFrntCmd 0 "OFF" 1 "AUTO" 2 "LOW" 3 "HIGH" ;
VAL_ 1035 VCC_1_OTASts 0 "Normal Status" 1 "OTA Status" 2 "Reserved" 3 "Reserved" ;
VAL_ 1035 VCC_1_DriveMode 0 "Not Active" 1 "ECO" 2 "Normal" 3 "Sport" 4 "Snow" 5 "Off Road" 6 "Individual" 7 "Energy-saving hybrid" 8 "Sand" 9 "AI" 10 "Wade" 11 "Rock" 12 "Mud" 13 "Smart" ;
VAL_ 1075 VCC_2_ConfigurationMessageTrg 0 "not active" 1 "active" ;
VAL_ 1196 TDL_SwitchSts 0 "Not_Active" 1 "ON" 2 "OFF" 3 "reserved" ;
VAL_ 1196 TDL_ColourModeSts 0 "Not_Active" 1 "Monochrome" 2 "panchromatic" 3 "OFF" 4 "Reserved" 5 "Reserved" 6 "Reserved" 7 "Reserved" ;
VAL_ 1196 TDL_RhythmSwSts 0 "Not_Active" 1 "ON" 2 "OFF" 3 "reserved" ;
VAL_ 1196 TDL_ApiluminanceSts 0 "Not_Active" 1 "Level1" 2 "Level2" 3 "Level3" 4 "Level4" 5 "Level5" 6 "Level6" 7 "Level7" 8 "Level8" 9 "Reserved" 10 "Reserved" 11 "Reserved" 12 "Reserved" 13 "Reserved" 14 "Reserved" 15 "Reserved" ;
VAL_ 1196 TDL_VioceFunctionDone 0 "Not_Active" 1 "success" 2 "fail" 3 "reserved" ;
VAL_ 1196 TDL_FlowLightSwSts 0 "Not_Active" 1 "ON" 2 "OFF" 3 "reserved" ;
VAL_ 1196 TDL_FlowLightModeSts 0 "Not Active" 1 "mode1" 2 "mode2" 3 "mode3" 4 "mode4" 5 "mode5" 6 "mode6" 7 "Reserved" ;
VAL_ 1196 TDL_RhythmModeSts 0 "Not_Active" 1 "Mode1" 2 "Mode2" 3 "Mode3" 4 "Mode4" 5 "Mode5" 6 "Mode6" 7 "Reserved" ;
VAL_ 1196 TDL_DOWWarningSts 0 "Not_Active" 1 "ON" 2 "OFF" 3 "Reserved" ;
VAL_ 1196 TDL_AssociatedDrivingModeSts 0 "Not_Active" 1 "ON" 2 "OFF" 3 "Reserved" ;
VAL_ 1177 FuelTankLidSts 0 "Close" 1 "Open" ;
VAL_ 1177 FuelTankLidLockFailureSts 0 "No failure" 1 "Failure" ;
VAL_ 1177 FuelTankLidSensorFailureSts 0 "No failure" 1 "Failure" ;
VAL_ 1109 CWC_ChargingSts 0 "No charging" 1 "Charging" 2 "Charging completed" 3 "Charging fault" ;
VAL_ 1109 CWC_workingSts 0 "CWC OFF" 1 "CWC ON" ;
VAL_ 1109 CWC_Phoneforgotten 0 "phone not forgotten" 1 "phone forgotten" ;
VAL_ 1109 CWC_Phoneforgotten_ON_OFF_Sts 0 "Function OFF" 1 "Function ON" ;
VAL_ 1109 CWC_1_ChrgFlt 0 "Not active" 1 "Low_Volf" 2 "High_Volf" 3 "High_Temp" 4 "Foreign_matter_detected" 5 "NFC_card_protect_L" 6 "Reserved" 7 "Reserved" ;
VAL_ 1109 CWC_ChargingSts_R 0 "No charging" 1 "Charging" 2 "Charging completed" 3 "Charging fault" ;
VAL_ 1109 CWC_workingSts_R 0 "CWC OFF" 1 "CWC ON" ;
VAL_ 1109 CWC_Phoneforgotten_R 0 "phone not forgotten" 1 "phone forgotten" ;
VAL_ 1109 CWC_Phoneforgotten_ON_OFF_Sts_R 0 "Function OFF" 1 "Function ON" ;
VAL_ 1109 CWC_1_ChrgFlt_R 0 "Not active" 1 "Low_Volf" 2 "High_Volf" 3 "High_Temp" 4 "Foreign_matter_detected_R" 5 "NFC_card_protect_R" 6 "Reserved" 7 "Reserved" ;
VAL_ 1063 TBOX_PetmodeSwitch 0 "Not Active" 1 "ON" 2 "OFF" 3 "Reserved" ;
VAL_ 1063 TBOX_SentinelModeSw 0 "Not Active" 1 "ON" 2 "OFF" ;
VAL_ 1148 TBOX_GPSSwitchSts 0 "Not Active" 1 "On" 2 "Off" 3 "Not Used" ;
VAL_ 1148 TimeToStartSentinelDayFed_47Ch 0 "No_active" 1 "Toady" 2 "Tomorrow" ;
VAL_ 1148 TimeToStartSentinelHourFed_47Ch 0 "Hour_0" 1 "Hour_1" 2 "Hour_2" 3 "Hour_3" 4 "Hour_4" 5 "Hour_5" 6 "Hour_6" 7 "Hour_7" 8 "Hour_8" 9 "Hour_9" 10 "Hour_10" 11 "Hour_11" 12 "Hour_12" 13 "Hour_13" 14 "Hour_14" 15 "Hour_15" 16 "Hour_16" 17 "Hour_17" 18 "Hour_18" 19 "Hour_19" 20 "Hour_20" 21 "Hour_21" 22 "Hour_22" 23 "Hour_23" 24 "Reserved" 25 "Reserved" 26 "Reserved" 27 "Reserved" 28 "Reserved" 29 "Reserved" 30 "Inactive" 31 "Invalid" ;
VAL_ 1148 TimeToStartSentinelMinutFed_47Ch 0 "Minute_0" 1 "Minute_1" 2 "Minute_2" 3 "Minute_3" 4 "Minute_4" 5 "Minute_5" 6 "Minute_6" 7 "Minute_7" 8 "Minute_8" 9 "Minute_9" 10 "Minute_10" 11 "Minute_11" 12 "Minute_12" 13 "Minute_13" 14 "Minute_14" 15 "Minute_15" 16 "Minute_16" 17 "Minute_17" 18 "Minute_18" 19 "Minute_19" 20 "Minute_20" 21 "Minute_21" 22 "Minute_22" 23 "Minute_23" 24 "Minute_24" 25 "Minute_25" 26 "Minute_26" 27 "Minute_27" 28 "Minute_28" 29 "Minute_29" 30 "Minute_30" 31 "Minute_31" 32 "Minute_32" 33 "Minute_33" 34 "Minute_34" 35 "Minute_35" 36 "Minute_36" 37 "Minute_37" 38 "Minute_38" 39 "Minute_39" 40 "Minute_40" 41 "Minute_41" 42 "Minute_42" 43 "Minute_43" 44 "Minute_44" 45 "Minute_45" 46 "Minute_46" 47 "Minute_47" 48 "Minute_48" 49 "Minute_49" 50 "Minute_50" 51 "Minute_51" 52 "Minute_52" 53 "Minute_53" 54 "Minute_54" 55 "Minute_55" 56 "Minute_56" 57 "Minute_57" 58 "Minute_58" 59 "Minute_59" 60 "Reserved" 61 "Reserved" 62 "Inactive" 63 "Invalid" ;
VAL_ 1148 TimeToStopSentinelHourFed_47Ch 0 "Hour_0" 1 "Hour_1" 2 "Hour_2" 3 "Hour_3" 4 "Hour_4" 5 "Hour_5" 6 "Hour_6" 7 "Hour_7" 8 "Hour_8" 9 "Hour_9" 10 "Hour_10" 11 "Hour_11" 12 "Hour_12" 13 "Hour_13" 14 "Hour_14" 15 "Hour_15" 16 "Hour_16" 17 "Hour_17" 18 "Hour_18" 19 "Hour_19" 20 "Hour_20" 21 "Hour_21" 22 "Hour_22" 23 "Hour_23" 24 "Reserved" 25 "Reserved" 26 "Reserved" 27 "Reserved" 28 "Reserved" 29 "Reserved" 30 "Inactive" 31 "Invalid" ;
VAL_ 1148 TimeToStopSentinelMinutFed_47Ch 0 "Minute_0" 1 "Minute_1" 2 "Minute_2" 3 "Minute_3" 4 "Minute_4" 5 "Minute_5" 6 "Minute_6" 7 "Minute_7" 8 "Minute_8" 9 "Minute_9" 10 "Minute_10" 11 "Minute_11" 12 "Minute_12" 13 "Minute_13" 14 "Minute_14" 15 "Minute_15" 16 "Minute_16" 17 "Minute_17" 18 "Minute_18" 19 "Minute_19" 20 "Minute_20" 21 "Minute_21" 22 "Minute_22" 23 "Minute_23" 24 "Minute_24" 25 "Minute_25" 26 "Minute_26" 27 "Minute_27" 28 "Minute_28" 29 "Minute_29" 30 "Minute_30" 31 "Minute_31" 32 "Minute_32" 33 "Minute_33" 34 "Minute_34" 35 "Minute_35" 36 "Minute_36" 37 "Minute_37" 38 "Minute_38" 39 "Minute_39" 40 "Minute_40" 41 "Minute_41" 42 "Minute_42" 43 "Minute_43" 44 "Minute_44" 45 "Minute_45" 46 "Minute_46" 47 "Minute_47" 48 "Minute_48" 49 "Minute_49" 50 "Minute_50" 51 "Minute_51" 52 "Minute_52" 53 "Minute_53" 54 "Minute_54" 55 "Minute_55" 56 "Minute_56" 57 "Minute_57" 58 "Minute_58" 59 "Minute_59" 60 "Reserved" 61 "Reserved" 62 "Inactive" 63 "Invalid" ;
VAL_ 1148 ReservationSentinelSts_Fed_47Ch 0 "No_active" 1 "ON" 2 "OFF" ;
VAL_ 1162 VehicleSpeedVSOSigValidData 0 "Valid" 1 "Not valid" ;
VAL_ 1162 ESPSwitchStatus 0 "On" 1 "Disable" ;
VAL_ 1162 ABSActive 0 "Not active" 1 "Active" ;
VAL_ 1162 ABSFailSts 0 "Fail not present" 1 "Fail present (lamp on)" ;
VAL_ 1162 EBDFailSts 0 "Fail not present" 1 "Fail present (lamp on)" ;
VAL_ 1162 TCSFailSts 0 "Fail not present" 1 "Fail present (lamp on)" ;
VAL_ 1162 VDCFailSts 0 "Fail not present" 1 "Fail present (lamp on)" ;
VAL_ 1162 TCSActive 0 "Not active" 1 "Active(blinking lamp)" ;
VAL_ 1162 VDCActive 0 "Not active" 1 "Active(blinking lamp)" ;
VAL_ 1162 BLRequestController 0 "Not illuminate" 1 "Illuminate" ;
VAL_ 1202 FuelRollingCounter 255 "Invalid" ;
VAL_ 1202 MILSts 0 "Off" 1 "Not used" 2 "Active" 3 "Not used" ;
VAL_ 1202 GPFWarning 0 "No GPF warning" 1 "GPF Full" 2 "GPF Overlimited" 3 "Reserved" ;
VAL_ 1202 EngineSpeed 2047 "Invalid" ;
VAL_ 1202 EngineSpeedValidData 0 "Valid" 1 "Not valid" ;
VAL_ 1202 EPCSts 0 "Off" 1 "Active" ;
VAL_ 1202 EMS_1_G_EngineSts 0 "Not Run" 1 "Run" ;
VAL_ 1202 EMS_EngineSts_Actual 0 "Not Run" 1 "Run" ;
VAL_ 1202 OilPressureWarningLamp 0 "Off" 1 "On" ;
VAL_ 1202 Activeheatingmode 0 "Notactive" 1 "active" ;
VAL_ 683 RHFDoorSts 0 "Close" 1 "Ajar_" 2 "full_open" 3 "Reserved" ;
VAL_ 683 FRZCU_1_ParkLightSts 0 "Close" 1 "Open" ;
VAL_ 683 RHRDoorSts 0 "Close" 1 "Ajar_" 2 "full_open" 3 "Reserved" ;
VAL_ 33 ACU_3_LongitudinalAcceleration 65535 "Invalid" ;
VAL_ 33 ACU_3_LongitudinalAccelerationVD 0 "Valid" 1 "Reserved" 2 "Invalid" 3 "Initialize" ;
VAL_ 33 ACU_3_CrashOutputSts 0 "No crash" 1 "Belt Crash" 2 "Front Crash" 4 "Left Side Crash" 8 "Right Side Crash" 16 "Rear Crash" 32 "Roll Crash" ;
VAL_ 1217 ASU_SysFailrSts_4C1h 0 "No Fail" 1 "LimpupMode" 2 "Fail" 3 "Reserved" ;
VAL_ 1217 ASU_SuspCurrentLvl_4C1h 0 "Invalid" 1 "High 3 level" 2 "Between high3 and high2 level" 3 "High 2 level" 4 "Between high2 and high1 level" 5 "High 1 level" 6 "Between high1 and normal level" 7 "Normal level" 8 "Between normal and low level" 9 "Low level" 10 "Between low and very low level" 11 "Very low level" 12 "easy Entry Enable level" 13 "easy Loading level" 14 "Reserved" 15 "Reserved" ;
VAL_ 1217 ASU_ECASSysSts_4C1h 0 "InValid" 1 "AxisLifting" 2 "AxisLowering" 3 "AxisHolding" 4 "Function Shutdown" ;
VAL_ 1217 ASU_ECASErrSts_4C1h 0 "no error" 1 "fault priority 1(minor)" 2 "fault priority 2(seriously)" 3 "fault priority 3(Very seriously)" ;
VAL_ 1217 ASU_SuspTarLvl_4C1h 0 "No requirement" 1 "Very high level" 2 "high level" 3 "normal level" 4 "low level" 5 "very low level" 6 "easy Entry Enable level" 7 "easy Loading level" ;
VAL_ 1217 ASU_EasyEntryEna_4C1h 0 "Not Enable" 1 "Enable" ;
VAL_ 1217 ASU_CDCErrSts_4C1h 0 "no error" 1 "error" ;
VAL_ 1217 ASU_RearaxlewithTaildoorFb_4C1h 0 "Not Enable" 1 "Enable" ;
VAL_ 1217 ASU_Overheat_warning_4C1h 0 "No failure" 1 "Warnig for overheat" ;
VAL_ 1217 ASU_MaintainMod_4C1h 0 "Initializing" 1 "ON,susp is in MaintainMod" 2 "OFF, susp isnot in MaintainMod" 3 "MaintainModexitReq" ;
VAL_ 1217 ASU_drivemodeheightlevFb_4C1h 0 "Not Active" 1 "High3" 2 "High2" 3 "High1" 4 "Standard" 5 "Low" 6 "Very Low" 7 "easy Entry Enable level" 8 "easy Loading level" 9 "Reserved" 10 "Reserved" 11 "Reserved" 12 "Reserved" 13 "Reserved" 14 "Reserved" 15 "Reserved" ;
VAL_ 1217 ASU_HMIFailFb_4C1h 0 "Work Normally" 1 "Non-P file" 2 "ASUSysFailrStsFail" 3 "Car running" 4 "Door is open" 5 "Slope is steep" 6 "Warnig for overheat" 7 "susp is in MaintainMod" 8 "susp is in Lifting Mod" 9 "CC connect" 10 "Low Battery" 11 "In Crash state" 12 "Airbag pressure too high" 13 "Unadjustable" 14 "AssistPassOut" 15 "Reserved" ;
VAL_ 1217 ASU_AssistPass_4C1h 0 "Inactive" 1 "Active" ;
VAL_ 1324 TirePositionWarning_LHFTire 0 "Normal" 1 "Rapid_Air_Loss(Reserved)" 2 "Low_Pressure" 3 "Low Batter" 4 "High_Pressure(Reserved)" 5 "High_Temperature" 6 "Error_Mode" 7 "Not_used(Reserved)" ;
VAL_ 1324 TirePositionWarning_RHFTire 0 "Normal" 1 "Rapid_Air_Loss(Reserved)" 2 "Low_Pressure" 3 "Low Batter" 4 "High_Pressure(Reserved)" 5 "High_Temperature" 6 "Error_Mode" 7 "Not_used(Reserved)" ;
VAL_ 1324 TirePositionWarning_LHRTire 0 "Normal" 1 "Rapid_Air_Loss(Reserved)" 2 "Low_Pressure" 3 "Low Batter" 4 "High_Pressure(Reserved)" 5 "High_Temperature" 6 "Error_Mode" 7 "Not_used(Reserved)" ;
VAL_ 1324 TirePositionWarning_RHRTire 0 "Normal" 1 "Rapid_Air_Loss(Reserved)_" 2 "Low_Pressure" 3 "Low Batter" 4 "High_Pressure(Reserved)" 5 "High_Temperature" 6 "Error_Mode" 7 "Not_used(Reserved)" ;
VAL_ 1324 TirePressureWarningLampSts 0 "Lamp_Off" 1 "Lamp_Flashing(Reserved)" 2 "Lamp_On" 3 "Not_used" ;
VAL_ 1324 TirePressureSystemFailSts 0 "Fail_Not_Present" 1 "Fail_Present" ;
VAL_ 991 TMS_MotorLoopErrorLevel 0 "No Error" 1 "Derating function" 2 "Disabler" 3 "ShutDown" 4 "Reserved" 5 "Reserved" 6 "Reserved" 7 "Reserved" ;
VAL_ 991 TMS_BatteryLoopErrorLevel 0 "No Error（无差错）" 1 "Derating function（降额功能）" 2 "Disabler（解除）" 3 "ShutDown（关闭）" 4 "Reserved（保留）" 5 "Reserved（保留）" 6 "Reserved（保留）" 7 "Reserved（保留）" ;
VAL_ 1188 FrontDeforestDisplaySts 0 "Not_Active" 1 "Active" ;
VAL_ 1188 TMS_DisplayActive 0 "Off" 1 "On" ;
VAL_ 1188 TMS_ZoneSelectionDisplaySts 0 "Single_zone_mode" 1 "Dual_zone_mode" ;
VAL_ 1188 TMS_AutoDisplaySts 0 "Auto_Off" 1 "Auto_On" ;
VAL_ 1188 TMS_FiltertchangeDisplaySts 0 "Off" 1 "On" ;
VAL_ 1188 TMS_AUTODefrostOnSts 0 "Off" 1 "On" ;
VAL_ 1188 TMS_AUTODefrostDisplaySts 0 "Off" 1 "On" ;
VAL_ 1188 TMS_RefInSufDispSts 0 "Off" 1 "On" ;
VAL_ 1188 TMS_CooltInSufDispSts 0 "Off" 1 "On" ;
VAL_ 1188 TMS_DLOnOffSts 0 "Off" 1 "On" ;
VAL_ 1188 TMS_DROnOffSts 0 "Off" 1 "On" ;
VAL_ 1188 TMS_PLOnOffSts 0 "Off" 1 "On" ;
VAL_ 1188 WorkingSts 0 "Not_Active" 1 "Active" ;
VAL_ 1188 TMS_PROnOffSts 0 "Off" 1 "On" ;
VAL_ 1188 TMS_DCOnOffSts 0 "Off" 1 "On" ;
VAL_ 1188 TMS_ACFastCool 0 "Off" 1 "On" ;
VAL_ 1188 TMS_ACFastHeat 0 "Off" 1 "On" ;
VAL_ 1188 TMS_LoveRemind 0 "Off" 1 "On" ;
VAL_ 1188 TMS_InteCleanCar 0 "Off" 1 "On" ;
VAL_ 1188 TMS_ACVentilationSts 0 "Off" 1 "On" ;
VAL_ 1188 TMS_AutoAirCleanSts 0 "Off" 1 "On" ;
VAL_ 1188 PM25Sts 0 "Not_Active" 1 "Active" ;
VAL_ 1188 TMS_ACModeCustomSts 0 "Not_active" 1 "ECO" 2 "Comfortable" 3 "Strong________________________________________________________" ;
VAL_ 1188 TMS_ACRequestDisplaySts 0 "Off" 1 "On" ;
VAL_ 1188 TMS_AUTODefLevelSts 0 "Not_Active" 1 "OFF" 2 "Low" 3 "Medium" 4 "High" ;
VAL_ 1188 TMS_KeepWarm 0 "Not_active" 1 "Open_AC_" 2 "Open_NotAC" 3 "Closed" ;
VAL_ 1188 TMS_DSwingSts 0 "Not_active" 1 "AllZone_Swing" 2 "Single_Swing" 3 "Mirro_Swing" 4 "Free_Swing" ;
VAL_ 1188 TMS_PSwingSts 0 "Not_active" 1 "AllZone_Swing" 2 "Single_Swing" 3 "Mirro_Swing" 4 "Free_Swing" ;
VAL_ 1188 TMS_TuisongDispSts 0 "Not_Request" 1 "Avoid_fog" 2 "Enhanced_Def" 3 "Enhanced_Purification" 4 "Swing_Operation" ;
VAL_ 1188 TMS_ModeAdjustDisplaySts 0 "BlowFace" 1 "BlowFaceAndBlowFoot" 2 "BlowFoot" 3 "BlowFootAndBlowWindow" 4 "BlowWindow" 5 "Not Active" 6 "BlowFaceAndBlowWindow" 7 "BlowFaceAndBlowFootAndBlowWindow" 8 "Auto" ;
VAL_ 1188 TMS_CirculationModeDisplaySts 0 "Recirculation_mode" 1 "Air_circulation_mode" 2 "Two-Layer_Flow_Mode" 3 "Reserved" ;
VAL_ 1188 AirSwingSts 0 "Off" 1 "On" ;
VAL_ 1188 TemperatureUnit 0 "Centigrade(℃)" 1 "Fahrenheit(℉)" ;
VAL_ 1188 BlowAdvanceOnSts 0 "AdvanceOn" 1 "Not_AdvanceOn" ;
VAL_ 1188 BlowDelayOffSts 0 "DelayOff" 1 "Not_DelayOff" ;
VAL_ 1188 TMS_PM25_ExtSts 0 "Normal" 1 "failure" ;
VAL_ 1188 TMS_PM25_IncarSts 0 "Normal" 1 "failure" ;
VAL_ 1188 TMS_AQS_Sts 0 "Normal" 1 "failure" ;
VAL_ 1188 PM25overproofDisplaySts 0 "Off" 1 "On" ;
VAL_ 1188 AQSDisplaySts 0 "Off" 1 "On" ;
VAL_ 1188 PM25AutoRunSts 0 "Off" 1 "On" ;
VAL_ 1188 PM25AutoRunSetSts 0 "Off" 1 "On" ;
VAL_ 1188 FragranceWelcomeModeSts 0 "Off" 1 "On" ;
VAL_ 1188 FragranceDisplaysts 0 "Off" 1 "On" ;
VAL_ 1188 TMS_AQS_Level 0 "Good" 1 "Light_pollution" 2 "Moderate_pollution" 3 "High_levels_of_pollution" ;
VAL_ 1188 ACRequestCommand 0 "Not_Active" 1 "Cooling" 2 "Heating" 3 "Venting" 4 "Auto" ;
VAL_ 1188 PM25_Outcar_Level 0 "Good" 1 "Favorable_pollution" 2 "Light_pollution" 3 "Moderate_pollution" 4 "High_levels_of_pollution" 5 "Serious_pollution" 6 "Reserved" 7 "Reserved" ;
VAL_ 1188 PM25_Incar_Level 0 "Good" 1 "Favorable_pollution" 2 "Light_pollution" 3 "Moderate_pollution" 4 "High_levels_of_pollution" 5 "Serious_pollution" 6 "Reserved" 7 "Reserved" ;
VAL_ 1188 TMS_KeepWarmMemoryFb 0 "Not_Active" 1 "Memory_On" 2 "Memory_Off" 3 "Not_Used" ;
VAL_ 612 FltLamp_264h 0 "Lamp OFF" 1 "Lamp ON" 2 "Lamp Flash" 3 "Reserved" ;
VAL_ 612 ParkLamp_264h 0 "Lamp OFF" 1 "Lamp ON" 2 "Lamp Flash" 3 "Reserved" ;
VAL_ 612 ActrSt_264h 0 "Unknow" 1 "Applied" 2 "Released" 3 "Applying" 4 "Releasing" 5 "CompletelyReleased" 6 "Half Applied" 7 "Reserved" ;
VAL_ 612 RWUSt_264h 0 "No active" 1 "active" ;
VAL_ 612 TextDisp_264h 0 "NO text message" 1 "Gradient too high" 2 "Clampforce not enough" 3 "fasten seatbelt" 4 "Press brake pedal" 5 "No_Release_Tip_for_Shift" 6 "Reserved" 7 "Reserved" 8 "Reserved" 9 "Reserved" 10 "Reserved" 11 "Reserved" 12 "Reserved" 13 "Reserved" 14 "Reserved" 15 "Reserved" ;
VAL_ 612 IPB_EPBErrorStatus 0 "No_Error" 1 "Error" ;
VAL_ 1193 AVHWarningMessage 0 "Off" 1 "Fasten DriverSeatBelt and Close the LHF door" ;
VAL_ 1193 CDPActive 0 "Not active" 1 "Active" ;
VAL_ 1193 HDCFailSts 0 "Fail not present" 1 "Fail present (lamp on)" ;
VAL_ 1193 HDCCtrlSts 0 "OFF" 1 "not active braking(lamp on)" 2 "On active braking(flash)" 3 "Not used" ;
VAL_ 1193 AVHSts 0 "Off" 1 "Standby" 2 "Active" 3 "Not Used" ;
VAL_ 1193 AVHFailSts 0 "Fail not present" 1 "Fail present (lamp on)" ;
VAL_ 1193 FWAWarningSts 0 "No failure" 1 "BrakeSys High Temperature Leve1" 2 "BrakeSys High Temperature Leve2" 3 "Not used" ;
VAL_ 1193 BrakeFluidSts 0 "Normal" 1 "Empty" 2 "Electric_error" 3 "Not used" ;
VAL_ 1193 BrakesystemFailSts 0 "Fail not present" 1 "Fail present" ;
VAL_ 1197 CST_Status 0 "CST is disabled" 1 "CST is Standby" 2 "CST is Active" 3 "CST is Failure" ;
VAL_ 1197 BrakepedalFeelSts 0 "Comfort" 1 "Sport" 2 "Offroad" 3 "Reserved" ;
VAL_ 1197 CST_SensitivitySts 0 "Not Active" 1 "Comfort Low" 2 "Comfort Middle" 3 "Comfort High" ;
VAL_ 1061 DriverSeatMsgStr_LvlSts 0 "OFF/Intial" 1 "Low" 2 "Middle" 3 "High" ;
VAL_ 1061 DriverSeatMsg_ModeSts 0 "NotActive" 1 "PulseMode" 2 "WaveMode" 3 "CatPawMode" 4 "SigleRowMode" 5 "CrossMode" 6 "ButterflyMode" 7 "WaistMode" 8 "SnakeMode" 9 "Special 1" 10 "Special 2" 11 "Special 3" 12 "Special 4" ;
VAL_ 1065 LeftSeatMsgStr_LvlSts 0 "OFF/Intial" 1 "Low" 2 "Middle" 3 "High" 4 "Reserved" 5 "Reserved" 6 "Reserved" 7 "Reserved" ;
VAL_ 1065 LeftSeatMsg_ModeSts 0 "NotActive" 1 "PulseMode" 2 "WaveMode" 3 "CatPawMode" 4 "SigleRowMode" 5 "CrossMode" 6 "ButterflyMode" 7 "WaistMode" 8 "SnakeMode" 9 "Special 1" 10 "Special 2" 11 "Special 3" 12 "Special 4" ;
VAL_ 1069 PassSeatMsgStr_LvlSts 0 "OFF/Intial" 1 "Low" 2 "Middle" 3 "High" 4 "Reserved" 5 "Reserved" 6 "Reserved" 7 "Reserved" ;
VAL_ 1069 PassSeatMsg_ModeSts 0 "NotActive" 1 "PulseMode" 2 "WaveMode" 3 "CatPawMode" 4 "SigleRowMode" 5 "CrossMode" 6 "ButterflyMode" 7 "WaistMode" 8 "SnakeMode" 9 "Special 1" 10 "Special 2" 11 "Special 3" 12 "Special 4" ;
VAL_ 1087 RightSeatMsgStr_LvlSts 0 "OFF/Intial" 1 "Low" 2 "Middle" 3 "High" 4 "Reserved" 5 "Reserved" 6 "Reserved" 7 "Reserved" ;
VAL_ 1087 RightSeatMsg_ModeSts 0 "NotActive" 1 "PulseMode" 2 "WaveMode" 3 "CatPawMode" 4 "SigleRowMode" 5 "CrossMode" 6 "ButterflyMode" 7 "WaistMode" 8 "SnakeMode" 9 "Special 1" 10 "Special 2" 11 "Special 3" 12 "Special 4" ;
VAL_ 1189 SRF_OperateSts 0 "Not Active" 1 "Tilt" 2 "Close" 3 "Opening" 4 "Stop" 5 "Closing" 6 "Open" 7 "Comfort_open" ;
VAL_ 1189 SRF_PositionSts 0 "Not Active" 1 "0%" 2 "10%" 3 "20%" 4 "30%" 5 "40%" 6 "50%" 7 "60%" 8 "70%" 9 "80%" 10 "90%" 11 "100%" 12 "Tilt" ;
VAL_ 1189 SRF_OverHeatProtect 0 "No_Error_Inactive" 1 "Active" ;
VAL_ 1189 SRF_Sunshade_OperateSts 0 "Not Active" 1 "Close" 2 "Opening" 3 "Stop" 4 "Closing" 5 "Open" 6 "Half_Open" 7 "Reserved" ;
VAL_ 1189 Sunshade_OverHeatProtect 0 "No_Error_Inactive" 1 "Active" ;
VAL_ 1192 SRF_Sunroof_ActualSts 0 "Not Active" 1 "Open" 2 "Close" 3 "Tilt" 4 "Reserved" 5 "Reserved" 6 "Reserved" 7 "Error" ;
VAL_ 1192 SRF_Sunshade_ActualSts 0 "Not Active" 1 "Open" 2 "Close" 3 "Tilt" 4 "Reserved" 5 "Reserved" 6 "Reserved" 7 "Error" ;
VAL_ 1192 SRF_Sunshade_PositionSts 0 "Not Active" 1 "0%" 2 "10%" 3 "20%" 4 "30%" 5 "40%" 6 "50%" 7 "60%" 8 "70%" 9 "80%" 10 "90%" 11 "100%" 12 "Reserved" ;
VAL_ 1235 EPS_2_Steer_ReturnRmd_Sts 0 "No_Active" 1 "ON" 2 "OFF" 3 "Reserved" ;
VAL_ 1235 EPS_2_Steer_ReturnRmd 0 "No Tip" 1 "Tip return finish" 2 "Tip return left" 3 "Tip return right" ;
VAL_ 1235 EPS_2_MFS_ShakeSts 0 "No_Active" 1 "ON" 2 "OFF" 3 "reserved" ;
VAL_ 1330 DWD_TextDisp 0 "No Active" 1 "Speed exceed 10km/h" 2 "Speed exceed 5km/h" 3 "Controller pedal undeploy" 4 "Slope exceed 10°" 5 "Driving mode is snow、mud、sand" 6 "Keep low speed" 7 "Out rearview mirror undeploy" 8 "Doors are open" 9 "Trunk are open" 10 "System is fail" 11 "System is not available" 12 "Sys exit" ;
VAL_ 1330 DWD_SoundIndcn 0 "No warning" 1 "Long beep" 2 "3Hz" 3 "1.5Hz" ;
VAL_ 1330 LSensorFailSts 0 "Sensor normal" 1 "Sensor fault" ;
VAL_ 1330 RSensorFailSts 0 "Sensor normal" 1 "Sensor fault" ;
VAL_ 1330 DWD_Distance 0 "No object" 1 "Object in zone 1, 0~5cm" 2 "Object in zone 2, 6~10cm" 3 "Object in zone 3, 11~15cm" 4 "Object in zone 4, 16~20cm" 5 "Object in zone 5, 21~25cm" 6 "Object in zone 6, 26~30cm" 7 "Object in zone 7, 31~35cm" 8 "Object in zone 8, 36~40cm" 9 "Object in zone 9, 41~45cm" 10 "Object in zone 10, 46~50cm" 11 "Object in zone 11, 51~55cm" 12 "Object in zone 12, 56~60cm" 13 "Object in zone 13, 61~65cm" 14 "Object in zone 14, 66~70cm" 15 "Object in zone 15, 71~75cm" 16 "Object in zone 16, 76~80cm" 17 "Object in zone 17, 81~85cm" 18 "Object in zone 18, 86~90cm" 19 "Object in zone 19, 91~95cm" 20 "Object in zone 20, 96~100cm" 21 "Object in zone 21, 101~105cm" 22 "Object in zone 22, 105~110cm" 23 "Object in zone 23, 111~115cm" 24 "Object in zone 24, 116~120cm" 25 "Object in zone 25, 121~125cm" 26 "Object in zone 26, 126~130cm" 27 "Object in zone 27, 131~135cm" 28 "Object in zone 28, 136~140cm" 29 "Object in zone 29, 141~145cm" 30 "Object in zone 30, 146~150cm" ;
VAL_ 1330 DWD_Switch 0 "Not Active" 1 "ON" 2 "OFF" 3 "Reserved" ;
VAL_ 1328 RADAR_1_RadarDetectSts 0 "No_Detecting_Startup" 1 "Front_Radar_Detecting" 2 "Rear_Radar_Detecting" 3 "Not_Used" ;
VAL_ 1328 RADAR_1_RadarWorkSts 0 "Not_Active" 1 "Active" ;
VAL_ 1328 RADAR_1_LHRRadarSensorDistance 63 "Sensor_Err" 62 "Startup" ;
VAL_ 1328 RADAR_1_RHMRRadarSensorDistance 63 "Sensor_Err" 62 "Startup" ;
VAL_ 1328 RADAR_1_LHMRRadarSensorDistance 63 "Sensor_Err" 62 "Startup" ;
VAL_ 1328 RADAR_1_RHRRadarSensorDistance 63 "Sensor_Err" 62 "Startup" ;
VAL_ 1328 RADAR_1_LHFRadarSensorDistance 31 "Sensor_Err" 30 "Startup" ;
VAL_ 1328 RADAR_1_RHFRadarSensorDistance 31 "Sensor_Err" 28 "Not_Used" 29 "Not_Used" 30 "Startup" ;
VAL_ 1328 RADAR_1_ParkingRadarSwSts 0 "Off" 1 "On" ;
VAL_ 1328 RADAR_1_RHMFRadarSensorDistance 31 "Sensor_Err" 30 "Startup" ;
VAL_ 1328 RADAR_1_LHMFRadarSensorDistance 31 "Sensor_Err" 30 "Startup" ;
VAL_ 1328 RADAR_1_AudibleBeepRate 0 "Off" 1 "On" 2 "4Hz" 3 "2Hz" 4 "1Hz" ;
VAL_ 1234 FRZCU_FRWinSts 0 "Not Active" 1 "Comfort" 2 "Close" 3 "Open" 4 "Other Position" 5 "Closing" 6 "Opening" 7 "Reserved" ;
VAL_ 1234 FRZCU_RRWinSts 0 "Not Active" 1 "Comfort" 2 "Close" 3 "Open" 4 "Other Position" 5 "Closing" 6 "Opening" 7 "Reserved" ;
VAL_ 1234 FRZCU_FRSeatNeedMemory 0 "No Request" 1 "Request" ;
VAL_ 1234 FRZCU_FRMemoryFb 0 "Not Active" 1 "Success" 2 "Fail" 3 "Ongoing" ;
VAL_ 1234 FRZCU_FRRecoverFb 0 "Not Active" 1 "Success" 2 "Fail" 3 "Ongoing" ;
VAL_ 1234 FRZCU_EasyEntryExitFb 0 "Not Active" 1 "ON" 2 "OFF" 3 "Not Used" ;
VAL_ 1234 FRZCU_EnjoyableSeatWarning 0 "Not Active" 1 "Buckle tied" 2 "Occupied" ;
VAL_ 1234 FRZCU_EnjoyableSeatSts 0 "Not Active" 1 "Forward Moving" 2 "Backward Moving" ;
VAL_ 1234 SeatHeatLevelsFR_4D2h 0 "OFF" 1 "Level1" 2 "Level2" 3 "Level3" 4 "AUTO(Reserved)" ;
VAL_ 1234 SeatVentLevelsFR_4D2h 0 "OFF" 1 "Level1" 2 "Level2" 3 "Level3" ;
VAL_ 1234 SeatHeatLevelsRR 0 "OFF" 1 "Level1" 2 "Level2" 3 "Level3" 4 "AUTO(Reserved)" ;
VAL_ 1234 SeatVentLevelsRR 0 "OFF" 1 "Level1" 2 "Level2" 3 "Level3" ;
VAL_ 1234 NonPwrOffSwtSts_4D2h 0 "Not Active" 1 "ON" 2 "OFF" 3 "Not Used" ;
VAL_ 517 MFSR_UP_SW 0 "Not_action" 1 "Pressed" 2 "Stuck" 3 "invalid" ;
VAL_ 517 MFSR_DW_SW 0 "Not_action" 1 "Pressed" 2 "Stuck" 3 "invalid" ;
VAL_ 517 MFSR_Left_SW 0 "Not_action" 1 "Pressed" 2 "Stuck" 3 "invalid" ;
VAL_ 517 MFSR_Right_SW 0 "Not_action" 1 "Pressed" 2 "Stuck" 3 "invalid" ;
VAL_ 517 MFSR_OK_SW 0 "Not_action" 1 "Pressed" 2 "Stuck" 3 "invalid" ;
VAL_ 517 MFSR_MENU_SW 0 "Not_action" 1 "Pressed" 2 "Stuck" 3 "invalid" ;
VAL_ 517 MFSR_Voice_SW 0 "Not_action" 1 "Pressed" 2 "Stuck" 3 "invalid" ;
VAL_ 517 MFSR_Customize 0 "Not_action" 1 "Pressed" 2 "Stuck" 3 "invalid" ;
VAL_ 1096 TMS_AirPurgeReminderSts 0 "Not_Active" 1 "ON" 2 "OFF" 3 "Not_Used" ;
VAL_ 1096 TMS_BT_Reduce_Wind_SpeedSts 0 "Off" 1 "Active" ;
VAL_ 1096 TMS_First_BlowingSts 0 "Off" 1 "Active" ;
VAL_ 1096 TMS_CirculationInTunnelsSts 0 "Off" 1 "Active" ;
VAL_ 1096 TMS_crosscountry_coolingSts 0 "No_Request" 1 "Active" 2 "Not_Active" ;
VAL_ 1096 TMS_ParkingAirConditioningStatus 0 "Inactive" 1 "AUTO" 2 "ventilate" ;
VAL_ 1096 TMS_CoolantFillSts 0 "No_Request" 1 "Request" ;
VAL_ 1096 TMS_UVC_ControlSts 0 "No_Request" 1 "Close_Request" 2 "Open_Request" 3 "AUTO" ;
VAL_ 1096 TMS_UVC_LuminanceSts 0 "No_Request" 1 "level_1" 2 "level_2" 3 "Reserved" 4 "Reserved" 5 "Reserved" 6 "Reserved" 7 "Reserved" ;
VAL_ 1096 TMS_ICC_Lightoff_Sts 0 "No_Request" 1 "FraganceLight_on_Sts" 2 "FraganceLight_off_Sts" 3 "Reserved" ;
VAL_ 1096 TMS_ICC_Memoff_Sts 0 "No_Request" 1 "FraganceMem_on" 2 "FraganceMem_off" 3 "Reserved" ;
VAL_ 1096 TMS_keepwarmSet_TemperatureSts 0 "Temperature_20°C" 1 "Temperature_25°C" 2 "Temperature_30°C" 3 "Temperature_35°C" 4 "Temperature_40°C" 5 "Temperature_45°C" 6 "Temperature_50°C" 7 "Temperature_55°C" 8 "Temperature_60°C" 9 "reserved" 10 "reserved" 11 "reserved" 12 "reserved" 13 "reserved" 14 "reserved" 15 "reserved" 16 "reserved" 17 "reserved" 18 "reserved" 19 "reserved" 20 "reserved" 21 "reserved" 22 "reserved" 23 "reserved" 24 "reserved" 25 "reserved" 26 "reserved" 27 "reserved" 28 "reserved" 29 "reserved" 30 "reserved" 31 "reserved" 32 "reserved" 33 "reserved" 34 "reserved" 35 "reserved" 36 "reserved" 37 "reserved" 38 "reserved" 39 "reserved" 40 "reserved" 41 "reserved" 42 "reserved" 43 "reserved" 44 "reserved" 45 "reserved" 46 "reserved" 47 "reserved" 48 "reserved" 49 "reserved" 50 "reserved" 51 "reserved" 52 "reserved" 53 "reserved" 54 "reserved" 55 "reserved" 56 "reserved" 57 "reserved" 58 "reserved" 59 "reserved" 60 "reserved" 61 "reserved" 62 "reserved" 63 "reserved" 64 "reserved" 65 "reserved" 66 "reserved" 67 "reserved" 68 "reserved" 69 "reserved" 70 "reserved" 71 "reserved" 72 "reserved" 73 "reserved" 74 "reserved" 75 "reserved" 76 "reserved" 77 "reserved" 78 "reserved" 79 "reserved" 80 "reserved" 81 "reserved" 82 "reserved" 83 "reserved" 84 "reserved" 85 "reserved" 86 "reserved" 87 "reserved" 88 "reserved" 89 "reserved" 90 "reserved" 91 "reserved" 92 "reserved" 93 "reserved" 94 "reserved" 95 "reserved" 96 "reserved" 97 "reserved" 98 "reserved" 99 "reserved" 100 "reserved" 101 "reserved" 102 "reserved" 103 "reserved" 104 "reserved" 105 "reserved" 106 "reserved" 107 "reserved" 108 "reserved" 109 "reserved" 110 "reserved" 111 "reserved" 112 "reserved" 113 "reserved" 114 "reserved" 115 "reserved" 116 "reserved" 117 "reserved" 118 "reserved" 119 "reserved" 120 "reserved" 121 "reserved" 122 "reserved" 123 "reserved" 124 "reserved" 125 "reserved" 126 "reserved" 127 "reserved" 128 "reserved" 129 "reserved" 130 "reserved" 131 "reserved" 132 "reserved" 133 "reserved" 134 "reserved" 135 "reserved" 136 "reserved" 137 "reserved" 138 "reserved" 139 "reserved" 140 "reserved" 141 "reserved" 142 "reserved" 143 "reserved" 144 "reserved" 145 "reserved" 146 "reserved" 147 "reserved" 148 "reserved" 149 "reserved" 150 "reserved" 151 "reserved" 152 "reserved" 153 "reserved" 154 "reserved" 155 "reserved" 156 "reserved" 157 "reserved" 158 "reserved" 159 "reserved" 160 "reserved" 161 "reserved" 162 "reserved" 163 "reserved" 164 "reserved" 165 "reserved" 166 "reserved" 167 "reserved" 168 "reserved" 169 "reserved" 170 "reserved" 171 "reserved" 172 "reserved" 173 "reserved" 174 "reserved" 175 "reserved" 176 "reserved" 177 "reserved" 178 "reserved" 179 "reserved" 180 "reserved" 181 "reserved" 182 "reserved" 183 "reserved" 184 "reserved" 185 "reserved" 186 "reserved" 187 "reserved" 188 "reserved" 189 "reserved" 190 "reserved" 191 "reserved" 192 "reserved" 193 "reserved" 194 "reserved" 195 "reserved" 196 "reserved" 197 "reserved" 198 "reserved" 199 "reserved" 200 "reserved" 201 "reserved" 202 "reserved" 203 "reserved" 204 "reserved" 205 "reserved" 206 "reserved" 207 "reserved" 208 "reserved" 209 "reserved" 210 "reserved" 211 "reserved" 212 "reserved" 213 "reserved" 214 "reserved" 215 "reserved" 216 "reserved" 217 "reserved" 218 "reserved" 219 "reserved" 220 "reserved" 221 "reserved" 222 "reserved" 223 "reserved" 224 "reserved" 225 "reserved" 226 "reserved" 227 "reserved" 228 "reserved" 229 "reserved" 230 "reserved" 231 "reserved" 232 "reserved" 233 "reserved" 234 "reserved" 235 "reserved" 236 "reserved" 237 "reserved" 238 "reserved" 239 "reserved" 240 "reserved" 241 "reserved" 242 "reserved" 243 "reserved" 244 "reserved" 245 "reserved" 246 "reserved" 247 "reserved" 248 "reserved" 249 "reserved" 250 "reserved" 251 "reserved" 252 "reserved" 253 "reserved" 254 "reserved" ;
VAL_ 1096 TMS_AutoDefogActiveSts 0 "Off" 1 "On" ;
VAL_ 1096 TMS_BiochemicalFuncSts 0 "Not Active" 1 "ON" 2 "OFF" 3 "Reserved" ;
VAL_ 1096 TMS_TimedVentilationSts 0 "Not Active" 1 "ON" 2 "OFF" 3 "Reserved" ;
VAL_ 1240 TMS_CFSSwitchFb 0 "OFF" 1 "ON" ;
VAL_ 1240 TDU_CFSPosOneType 0 "No Frag" 1 "Type 1" 2 "Type 2" 3 "Type 3" 4 "Type 4" 5 "Type 5" 6 "Unfilled" 7 "Position one active" 8 "Type 6" 9 "Type7" 10 "Type8" 11 "Type9" 12 "Type10" 13 "Type11" 14 "Type12" 15 "Not Active" ;
VAL_ 1240 TDU_CFSPosTwoType 0 "No Frag" 1 "Type 1" 2 "Type 2" 3 "Type 3" 4 "Type 4" 5 "Type 5" 6 "Unfilled" 7 "Position one active" 8 "Type 6" 9 "Type7" 10 "Type8" 11 "Type9" 12 "Type10" 13 "Type11" 14 "Type12" 15 "Not Active" ;
VAL_ 1240 TDU_CFSPosThreeType 0 "No Frag" 1 "Type 1" 2 "Type 2" 3 "Type 3" 4 "Type 4" 5 "Type 5" 6 "Unfilled" 7 "Position one active" 8 "Type 6" 9 "Type7" 10 "Type8" 11 "Type9" 12 "Type10" 13 "Type11" 14 "Type12" 15 "Not Active" ;
VAL_ 1240 TDU_CFSRunOut 0 "No Unset" 1 "Position One Runout" 2 "Position Two Runout" 3 "Position One and Two Runout" 4 "Position Three Runout" 5 "Position One and Three Runout" 6 "Position Two and Three Runout" 7 "Position One and Two and Three Runout" 8 "Reserved" 9 "Reserved" 10 "Reserved" 11 "Reserved" 12 "Reserved" 13 "Reserved" 14 "Reserved" 15 "Not Active" ;
VAL_ 1240 TMS_CFSShortWarn 0 "No Unset" 1 "Position One ShortWarn" 2 "Position Two ShortWarn" 3 "Position One and Two ShortWarn" 4 "Position Three ShortWarn" 5 "Position One and Three ShortWarn" 6 "Position Two and Three ShortWarn" 7 "Position One and Two and Three ShortWarn" 8 "Reserved" 9 "Reserved" 10 "Reserved" 11 "Reserved" 12 "Reserved" 13 "Reserved" 14 "Reserved" 15 "Not Active" ;
VAL_ 1240 TMS_CFSLevelSetFb 0 "Not Active" 1 "Level 1" 2 "Level 2" 3 "Level 3" 4 "Reserved" 5 "Reserved" 6 "Reserved" 7 "Reserved" 8 "Reserved" 9 "Reserved" 10 "Reserved" 11 "Reserved" 12 "Reserved" 13 "Reserved" 14 "Reserved" 15 "Reserved" ;
VAL_ 1240 TMS_CFSPosSetFb 0 "Not Active" 1 "Position One" 2 "Position Two" 3 "Position Three" ;
VAL_ 1240 TMS_PM25SwitchFb 0 "OFF" 1 "On" ;
VAL_ 1240 TMS_ThrModeStsFb 0 "Blow Face" 1 "Blow Face and Blow Foot" 2 "Blow Foot" 3 "Auto" 4 "Reserved" 5 "Reserved" 6 "Reserved" 7 "Not Active" ;
VAL_ 1240 TMS_ThrSetTempFb_C 31 "Not active" ;
VAL_ 1240 TMS_ThrCLMSwitchFb 0 "OFF" 1 "On" ;
VAL_ 1240 TMS_ThrAutoSwitchFb 0 "Auto OFF" 1 "Auto On" ;
VAL_ 1240 TMS_ThrBlowSpeedLevelKeyStsFb 0 "Not Active" 1 "Level  1" 2 "Level  2" 3 "Level  3" 4 "Level  4" 5 "Level  5" 6 "Level  6" 7 "Level  7" 8 "Level  0" 9 "Reserved" 10 "Reserved" 11 "Reserved" 12 "Reserved" 13 "Reserved" 14 "Reserved" 15 "Reserved" ;
VAL_ 638 FRZCU_HoodSts 0 "Close" 1 "Ajar_" 2 "full_open" 3 "Reserved" ;
VAL_ 638 FRZCU_AuthenResult 0 "not_success" 1 "success_" ;
VAL_ 638 FRZCU_9_PowerMode 0 "Off" 1 "Comfortable" 2 "ON" 3 "Reserved" ;
VAL_ 638 FRZCU_TrunkSts 0 "Close" 1 "Ajar_" 2 "full_open" 3 "Reserved" ;
VAL_ 638 FRZCU_HandleSwitchStsFL 0 "Not_Active" 1 "Outside" 2 "Inside" 3 "Bothside" ;
VAL_ 638 FRZCU_HandleSwitchStsFR 0 "Not_Active" 1 "Outside" 2 "Inside" 3 "Bothside" ;
VAL_ 638 FRZCU_HandleSwitchStsRR 0 "Not_Active" 1 "Outside" 2 "Inside" 3 "Bothside" ;
VAL_ 638 FRZCU_HandleSwitchStsRL 0 "Not_Active" 1 "Outside" 2 "Inside" 3 "Bothside" ;
VAL_ 638 SeatLength_target_Passenger 0 "Not_active" 1 "0" 2 "10%" 3 "20%" 4 "30%" 5 "40%" 6 "50%" 7 "60%" 8 "70%" 9 "80%" 10 "90%" 11 "100%" 12 "Reserved" 13 "Reserved" 14 "Reserved" 15 "Reserved" ;
VAL_ 638 SeatBackrest_target_Passenger 0 "Not_active" 1 "0" 2 "5%" 3 "10%" 4 "15%" 5 "20%" 6 "25%" 7 "30%" 8 "35%" 9 "40%" 10 "45%" 11 "50%" 12 "55%" 13 "60%" 14 "65%" 15 "70%" 16 "75%" 17 "80%" 18 "85%" 19 "90%" 20 "95%" 21 "100%" 22 "Reserved" 23 "Reserved" 24 "Reserved" 25 "Reserved" 26 "Reserved" 27 "Reserved" 28 "Reserved" 29 "Reserved" 30 "Reserved" 31 "Reserved" ;
VAL_ 638 FRZCU_TrunkLockSts 0 "Locked" 1 "Unlocked" 2 "Superlocked" 3 "Unknown" ;
VAL_ 638 FRZCU_HoodLockSts 0 "Locked" 1 "Unlocked" 2 "Superlocked" 3 "Unknown" ;
VAL_ 638 FrontBackSpeedAdj_Cmd 0 "No_Request" 1 "Low" 2 "Medium" 3 "High" 4 "Reserved" 5 "Reserved" 6 "Reserved" 7 "invalid" ;
VAL_ 638 FRZCU_GloveboxSW 0 "OFF" 1 "ON" ;
VAL_ 638 FRZCU_FRReleaseLockSts 0 "None" 1 "Releasing" 2 "Released" 3 "Reset" 4 "Resetting" 5 "Reserved" 6 "Reserved" 7 "Reserved" ;
VAL_ 638 FRZCU_RRReleaseLockSts 0 "None" 1 "Releasing" 2 "Released" 3 "Reset" 4 "Resetting" 5 "Reserved" 6 "Reserved" 7 "Reserved" ;
VAL_ 638 FRZCU_PELockInKeyWarning 0 "Not_Active" 1 "Active" ;
VAL_ 638 FRZCU_PowerOFFWarning 0 "Not_Active" 1 "Active" ;
VAL_ 638 FRZCU_KeylessWarning 0 "Not_Active" 1 "Active" ;
VAL_ 638 FRZCU_OTAPwrDwnReqFb 0 "No_Command" 1 "Success" 2 "Fail" 3 "Resrved" ;
VAL_ 638 FRZCU_OTAPwrOnReqFb 0 "No_Command" 1 "Success" 2 "Fail" 3 "Resrved" ;
VAL_ 949 PEPS_InformationSource 0 "Not_Active" 1 "Smart_Information" 2 "RKE_Information" 3 "Near_Access" ;
VAL_ 949 PEPS_OrderInformation 0 "OFF" 1 "Lock" 2 "Unlock" 4 "Trunk" 5 "Welcome_On" 6 "Welcome_Off" 7 "RKE_Search_Car" 8 "Power_Slide_Door_Left" ;
VAL_ 949 PEPS_IDInformation 0 "Not_Active" 1 "Transmitter_1" 2 "Transmitter_2" 3 "Transmitter_3" 4 "Transmitter_4" 5 "Transmitter_BLT1" 6 "Transmitter_BLT2" 7 "Transmitter_BLT3" 8 "Transmitter_NFC1" 9 "Transmitter_NFC2" 10 "Transmitter_NFC3" ;
VAL_ 949 PEPS_KeySts 0 "Not_Active" 1 "PEPS_Key_In" 2 "PEPS_Key_Near_Flant" 3 "PEPS_Key_Near_Frant" 4 "PEPS_Key_Near_Trunkant" 5 "Unknow" ;
VAL_ 949 PEPS_ETRUnLockReq 0 "Not_Request" 1 "Request" ;
VAL_ 1028 PEPS_WelcomeON 0 "Default_value" 1 "Welcome_light_OFF" 2 "Welcome_light_ON" 3 "Reserved" ;
VAL_ 1028 PEPS_VehicleSearchReq 0 "No_Request" 1 "Request" 2 "Reseved" 3 "Reseved" ;
VAL_ 1028 PEPS_SATOReminder 0 "No_Command" 1 "Remind_stop" 2 "Remind_start" 3 "Reseved" ;
VAL_ 1028 PEPS_PLGUnlockReq 0 "Not_Request" 1 "Request" 2 "Reseved" 3 "Reseved" ;
VAL_ 1028 PEPS_RKETrunkSts 0 "Not_Active" 1 "Long_Press" 2 "Short_Press" 3 "Not_Used" ;
VAL_ 1028 PEPS_SSBInhibitCWCSts 0 "Default" 1 "Disable" 2 "Reseved" 3 "Reseved" ;
VAL_ 1028 PEPS_WirelessChargingCtrSts 0 "Default" 1 "Disable" 2 "Reseved" 3 "Reseved" ;
VAL_ 1028 PEPS_EmgyShutdown 0 "No_Happen" 1 "Happen" 2 "Reseved" 3 "Reseved" ;
VAL_ 1028 PEPS_SSBInputFailure 0 "Not_Fail" 1 "Fail" 2 "Reseved" 3 "Reseved" ;
VAL_ 1028 PEPS_SmartSystemWarning1_1 0 "Normal" 1 "Identifier_is_out_of_vehicle" 2 "Reseved" 3 "Reseved" ;
VAL_ 1028 PEPS_SmartSystemWarning2_2 0 "Normal" 1 "Identifier_is_out_of_vehicle_range_when_vehicle_starts_running" 2 "Reseved" 3 "Reseved" ;
VAL_ 1028 PEPS_SmartSystemWarning3_1 0 "Normal" 1 "Identifier_low_battery_detected" 2 "Reseved" 3 "Reseved" ;
VAL_ 1028 PEPS_SmartSystemWarning3_2 0 "Normal" 1 "Engine_start_not_possible_if_gear_box_not_in_P_or_N_position" 2 "Reseved" 3 "Reseved" ;
VAL_ 1028 PEPS_SmartSystemWarning4_2 0 "Normal_" 1 "Engine_start_attempted_without_pressing_clutch/brake_pedal" 2 "Reseved" 3 "Reseved" ;
VAL_ 1028 PEPS_SmartSystemWarning4_3 0 "Normal" 1 "Switching_OFF_while_Gear_box_not_in_P_position" 2 "Reseved" 3 "Reseved" ;
VAL_ 1028 PEPS_SystemWarning 0 "Normal" 1 "Fault" 2 "Reseved" 3 "Reseved" ;
VAL_ 1028 PEPS_BLTKeyPESts 0 "OFF" 1 "ON" 2 "Reseved" 3 "Reseved" ;
VAL_ 1104 RLCR_2_RCWWarn 0 "No Warning" 1 "Level1 Warning" 2 "Level2 Warning" 3 "Not Used" ;
VAL_ 1104 RLCR_2_RCTAWarn 0 "No Warning" 1 "Warning" ;
VAL_ 1104 RLCR_2_BSDLCWONOFFSts 0 "Not active" 1 "OFF" 2 "ON" 3 "Reserved" ;
VAL_ 1104 RLCR_2_DOWONOFFSts 0 "Not active" 1 "OFF" 2 "ON" 3 "Reserved" ;
VAL_ 1104 RLCR_2_RCWONOFFSts 0 "Not active" 1 "OFF" 2 "ON" 3 "Reserved" ;
VAL_ 1104 RLCR_2_RCTARCTBONOFFSts 0 "OFF" 1 "warning" 2 "Reserved" 3 "Reserved" ;
VAL_ 1271 RRCR_2_RCWWarn 0 "No Warning" 1 "Level1 Warning" 2 "Level2 Warning" 3 "Not Used" ;
VAL_ 1271 RRCR_2_RCTAWarn 0 "No Warning" 1 "Warning" ;
VAL_ 1271 RRCR_2_BSDLCWONOFFSts 0 "Not active" 1 "OFF" 2 "ON" 3 "Reserved" ;
VAL_ 1271 RRCR_2_DOWONOFFSts 0 "Not active" 1 "OFF" 2 "ON" 3 "Reserved" ;
VAL_ 1271 RRCR_2_RCWONOFFSts 0 "Not active" 1 "OFF" 2 "ON" 3 "Reserved" ;
VAL_ 1271 RRCR_2_RCTARCTBONOFFSts 0 "OFF" 1 "warning" 2 "Reserved" 3 "Reserved" ;
VAL_ 587 LHRPulseCounterFailSts 0 "Fail Not Present" 1 "Fail Present" ;
VAL_ 587 RHRPulseCounterFailSts 0 "Fail Not Present" 1 "Fail Present" ;
VAL_ 587 RHFPulseCounterFailSts 0 "Fail Not Present" 1 "Fail Present" ;
VAL_ 587 LHFPulseCounterFailSts 0 "Fail Not Present" 1 "Fail Present" ;
VAL_ 587 LHFWheelDriveDirection 0 "Init" 1 "Forward" 2 "Backward" 3 "Stop" 4 "Invalid" 5 "reserved" 6 "reserved" 7 "reserved" ;
VAL_ 587 RHFWheelDriveDirection 0 "Init" 1 "Forward" 2 "Backward" 3 "Stop" 4 "Invalid" 5 "reserved" 6 "reserved" 7 "reserved" ;
VAL_ 587 LHRWheelDriveDirection 0 "Init" 1 "Forward" 2 "Backward" 3 "Stop" 4 "Invalid" 5 "reserved" 6 "reserved" 7 "reserved" ;
VAL_ 587 RHRWheelDriveDirection 0 "Init" 1 "Forward" 2 "Backward" 3 "Stop" 4 "Invalid" 5 "reserved" 6 "reserved" 7 "reserved" ;
VAL_ 1180 ACU_1_AirBagFailSts 0 "Fail no present, lamp off" 1 "Fail no present, lamp flashing" 2 "Fail present, lamp on" 3 "Lamp on, but no warning information displaying on the LCD" ;
VAL_ 1180 ACU_1_ThdRowLBeltWarning 0 "No Warning" 1 "Warning" ;
VAL_ 1180 ACU_1_ThdRowRBeltWarning 0 "No Warning" 1 "Warning" ;
VAL_ 1180 ACU_1_PsngrSeatBeltWarning 0 "Not warning" 1 "Reserve" 2 "Warning" 3 "Not used" ;
VAL_ 1180 ACU_1_SecRowLBeltWarning 0 "No Warning" 1 "Warning" ;
VAL_ 1180 ACU_1_SecRowMBeltWarning 0 "No Warning" 1 "Warning" ;
VAL_ 1180 ACU_1_SecRowRBeltWarning 0 "No Warning" 1 "Warning" ;
VAL_ 1180 ABM_1_Rollover_Status 0 "RolloverEnable 翻滚点爆不抑制" 1 "RolloverDisable 翻滚点爆被抑制" ;
VAL_ 1180 ACU_1_PsngrSeatOccupiedSts 0 "not occupied" 1 "occupied" 2 "open circuit" 3 "short circuit" ;
VAL_ 1269 LISDShowCMDSts 0 "OFF" 1 "ON" ;
VAL_ 1269 LISDShowModeSts 0 "Default value" 1 "BatteryCharging" 2 "Brand" 3 "TiresPressures" 4 "Weather" 5 "Greetings" 6 "Package" 7 "Panda" 8 "PredestrianCrossing" 9 "PingPong" 10 "Kite" 11 "Coffee" 12 "Reserved" 13 "Reserved" 14 "Reserved" 15 "Reserved" ;
VAL_ 1269 LISDTransmitStatus 0 "Default value" 1 "Success" 2 "Fail" 3 "Idle" ;
VAL_ 1269 LISDDisplayStatus 0 "Not Active" 1 "ON" 2 "OFF" 3 "Reserved" ;
VAL_ 1269 LISD_ParkingShowModSts 0 "Default value" 1 "Mode1" 2 "Mode2" 3 "Mode3" 4 "Mode4" 5 "Reserved" 6 "Reserved" 7 "Reserved" 8 "Reserved" 9 "Reserved" 10 "Reserved" 11 "Reserved" 12 "Reserved" 13 "Reserved" 14 "Reserved" 15 "Reserved" ;
VAL_ 1269 LISD_ParkingShowCMDSts 0 "Not Active" 1 "ON" 2 "OFF" 3 "Reserved" ;
VAL_ 1233 RISDShowCMDSts 0 "OFF" 1 "ON" ;
VAL_ 1233 RISDShowModeSts 0 "Default value" 1 "BatteryCharging" 2 "Brand" 3 "TiresPressures" 4 "Weather" 5 "Greetings" 6 "Package" 7 "Panda" 8 "PredestrianCrossing" 9 "PingPong" 10 "Kite" 11 "Coffee" 12 "Reserved" 13 "Reserved" 14 "Reserved" 15 "Reserved" ;
VAL_ 1233 RISD_TransmitStatus 0 "Default value" 1 "Success" 2 "Fail" 3 "Idle" ;
VAL_ 1233 RISD_DisplayStatus 0 "Not Active" 1 "ON" 2 "OFF" ;
VAL_ 1233 RISD_ParkingShowModSts 0 "Default value" 1 "Mode1" 2 "Mode2" 3 "Mode3" 4 "Mode4" 5 "Reserved" 6 "Reserved" 7 "Reserved" 8 "Reserved" 9 "Reserved" 10 "Reserved" 11 "Reserved" 12 "Reserved" 13 "Reserved" 14 "Reserved" 15 "Reserved" ;
VAL_ 1233 RISD_ParkingShowCMDSts 0 "Not Active" 1 "ON" 2 "OFF" ;
VAL_ 1169 LC_DIYMusicShowModSts 0 "Not Active" 1 "Mode1" 2 "Mode2" 3 "Reserved" ;
VAL_ 1169 LC_RandomMusicShowSts 0 "Not Active" 1 "Active" 2 "Reserved" 3 "Reserved" ;
VAL_ 1169 LC_LiShowModSts 0 "Not Active" 1 "OFF" 2 "Mode1" 3 "Mode2" 4 "Mode3" 5 "Mode4(Reserved)" 6 "Mode5(Reserved)" ;
VAL_ 1427 ILCF_1_LogoParkingSts 0 "Not Active" 1 "ON" 2 "OFF" 3 "Reserved" ;
VAL_ 1427 ILCF_1_LogoChargingSts 0 "Not Active" 1 "ON" 2 "OFF" 3 "Reserved" ;
VAL_ 1427 ILCF_1_DIYMusicShowModSts 0 "Not Active" 1 "Mode1" 2 "Mode2" 3 "Mode3" ;
VAL_ 1427 ILCF_1_RandomMusicShowSts 0 "Not Active" 1 "Active" 2 "Reserved" 3 "Reserved" ;
VAL_ 1427 ILCF_1_LogoColorAdjSts 0 "Not Active" ;
VAL_ 821 ADS_5_ILOASts 0 "Off" 1 "On" 2 "Evasioning" 3 "Retreat" 4 "Evasion finished" 5 "None" 6 "Reserved" 7 "Reserved" ;
VAL_ 821 ADS_5_ICAQuitReason 0 "None" 1 "Bad Weather" 2 "Large curve" 3 "ODD not meet" 4 "reserved" 5 "reserved" 6 "reserved" 7 "reserved" ;
VAL_ 821 ADS_5_ISLISt 0 "OFF" 1 "ON" 2 "failure" 3 "Reserved" ;
VAL_ 821 ADS_5_ILOATextInfo 0 "None" 1 "Evading oversized vehicle" 2 "Avoiding obstacles" 3 "Reserved" ;
VAL_ 821 ADS_5_ILOAActdirection 0 "Not active" 1 "Left" 2 "Right" 3 "Reserved" ;
VAL_ 821 ADS_5_LKS_warning 0 "no warning" 1 "warning" ;
VAL_ 821 ADS_5_ISLIOverSpeedWarn 0 "No warning" 1 "Waning1" 2 "Waning2" 3 "Waning3" ;
VAL_ 821 ADS_5_ISLISpeedLimitSign 0 "No display" 1 "Cancellation sign" 2 "5" 3 "10" 4 "15" 5 "20" 6 "25" 7 "30" 8 "35" 9 "40" 10 "45" 11 "50" 12 "55" 13 "60" 14 "65" 15 "70" 16 "75" 17 "80" 18 "85" 19 "90" 20 "95" 21 "100" 22 "105" 23 "110" 24 "115" 25 "120" 26 "125" 27 "130" 28 "135" 29 "140" 30 "145" 31 "150" 32 "155" 33 "160" 34 "165" 35 "170" 36 "175" 37 "180" 38 "185" 39 "190" 40 "195" 41 "200" 42 "Reserved" 43 "Reserved" 44 "Reserved" 45 "Reserved" 46 "Reserved" 47 "Reserved" 48 "Reserved" 49 "Reserved" 50 "Reserved" 51 "Reserved" 52 "Reserved" 53 "Reserved" 54 "Reserved" 55 "Reserved" 56 "Reserved" 57 "Reserved" 58 "Reserved" 59 "Reserved" 60 "Reserved" 61 "Reserved" 62 "Reserved" 63 "Reserved" 64 "Reserved" 65 "Reserved" 66 "Reserved" 67 "Reserved" 68 "Reserved" 69 "Reserved" 70 "Reserved" 71 "Reserved" 72 "Reserved" 73 "Reserved" 74 "Reserved" 75 "Reserved" 76 "Reserved" 77 "Reserved" 78 "Reserved" 79 "Reserved" 80 "Reserved" 81 "Reserved" 82 "Reserved" 83 "Reserved" 84 "Reserved" 85 "Reserved" 86 "Reserved" 87 "Reserved" 88 "Reserved" 89 "Reserved" 90 "Reserved" 91 "Reserved" 92 "Reserved" 93 "Reserved" 94 "Reserved" 95 "Reserved" 96 "Reserved" 97 "Reserved" 98 "Reserved" 99 "Reserved" 100 "Reserved" 101 "Reserved" 102 "Reserved" 103 "Reserved" 104 "Reserved" 105 "Reserved" 106 "Reserved" 107 "Reserved" 108 "Reserved" 109 "Reserved" 110 "Reserved" 111 "Reserved" 112 "Reserved" 113 "Reserved" 114 "Reserved" 115 "Reserved" 116 "Reserved" 117 "Reserved" 118 "Reserved" 119 "Reserved" 120 "Reserved" 121 "Reserved" 122 "Reserved" 123 "Reserved" 124 "Reserved" 125 "Reserved" 126 "Reserved" 127 "Reserved" 128 "Reserved" 129 "Reserved" 130 "Reserved" 131 "Reserved" 132 "Reserved" 133 "Reserved" 134 "Reserved" 135 "Reserved" 136 "Reserved" 137 "Reserved" 138 "Reserved" 139 "Reserved" 140 "Reserved" 141 "Reserved" 142 "Reserved" 143 "Reserved" 144 "Reserved" 145 "Reserved" 146 "Reserved" 147 "Reserved" 148 "Reserved" 149 "Reserved" 150 "Reserved" 151 "Reserved" 152 "Reserved" 153 "Reserved" 154 "Reserved" 155 "Reserved" 156 "Reserved" 157 "Reserved" 158 "Reserved" 159 "Reserved" 160 "Reserved" 161 "Reserved" 162 "Reserved" 163 "Reserved" 164 "Reserved" 165 "Reserved" 166 "Reserved" 167 "Reserved" 168 "Reserved" 169 "Reserved" 170 "Reserved" 171 "Reserved" 172 "Reserved" 173 "Reserved" 174 "Reserved" 175 "Reserved" 176 "Reserved" 177 "Reserved" 178 "Reserved" 179 "Reserved" 180 "Reserved" 181 "Reserved" 182 "Reserved" 183 "Reserved" 184 "Reserved" 185 "Reserved" 186 "Reserved" 187 "Reserved" 188 "Reserved" 189 "Reserved" 190 "Reserved" 191 "Reserved" 192 "Reserved" 193 "Reserved" 194 "Reserved" 195 "Reserved" 196 "Reserved" 197 "Reserved" 198 "Reserved" 199 "Reserved" 200 "Reserved" 201 "Reserved" 202 "Reserved" 203 "Reserved" 204 "Reserved" 205 "Reserved" 206 "Reserved" 207 "Reserved" 208 "Reserved" 209 "Reserved" 210 "Reserved" 211 "Reserved" 212 "Reserved" 213 "Reserved" 214 "Reserved" 215 "Reserved" 216 "Reserved" 217 "Reserved" 218 "Reserved" 219 "Reserved" 220 "Reserved" 221 "Reserved" 222 "Reserved" 223 "Reserved" 224 "Reserved" 225 "Reserved" 226 "Reserved" 227 "Reserved" 228 "Reserved" 229 "Reserved" 230 "Reserved" 231 "Reserved" 232 "Reserved" 233 "Reserved" 234 "Reserved" 235 "Reserved" 236 "Reserved" 237 "Reserved" 238 "Reserved" 239 "Reserved" 240 "Reserved" 241 "Reserved" 242 "Reserved" 243 "Reserved" 244 "Reserved" 245 "Reserved" 246 "Reserved" 247 "Reserved" 248 "Reserved" 249 "Reserved" 250 "Reserved" 251 "Reserved" 252 "Reserved" 253 "Reserved" 254 "Reserved" 255 "Reserved" ;
VAL_ 821 ADS_5_EgoLeftLineHeatgAg 511 "Invalid" ;
VAL_ 821 ADS_5_EgoLeLineID 0 "Invalid" 1 "Valid" ;
VAL_ 821 ADS_5_EgoLeLineColor 0 "No display" 1 "Color_Unknown" 2 "Color_White" 3 "Color_Yellow" ;
VAL_ 821 ADS_5_EgoLeLineTyp 0 "No display" 1 "Type_Unknown" 2 "Type_Solid_Line" 3 "Type_Dashed_Line" ;
VAL_ 821 ADS_5_EgoLeLineHozlDst 511 "Invalid" ;
VAL_ 821 ADS_5_NeborLeLineID 0 "Invalid" 1 "Valid" ;
VAL_ 821 ADS_5_NeborLeLineColor 0 "No display" 1 "Color_Unknown" 2 "Color_White" 3 "Color_Yellow" ;
VAL_ 821 ADS_5_NeborLeLineTyp 0 "No display" 1 "Type_Unknown" 2 "Type_Solid_Line" 3 "Type_Dashed_Line" ;
VAL_ 821 ADS_5_EgoLeLineCrvt 1023 "Invalid" ;
VAL_ 821 ADS_5_NeborLeLineHozlDst 511 "Invalid" ;
VAL_ 821 ADS_5_NeborRiLineID 0 "Invalid" 1 "Valid" ;
VAL_ 821 ADS_5_NeborRiLineColor 0 "No display" 1 "Color_Unknown" 2 "Color_White" 3 "Color_Yellow" ;
VAL_ 821 ADS_5_NeborRiLineTyp 0 "No display" 1 "Type_Unknown" 2 "Type_Solid_Line" 3 "Type_Dashed_Line" ;
VAL_ 821 ADS_5_NeborLeLineCrvt 1023 "Invalid" ;
VAL_ 821 ADS_5_NeborRiLineHozlDst 511 "Invalid" ;
VAL_ 821 ADS_5_ELKSettingSt 0 "None" 1 "On" 2 "Off" 3 "reserved" ;
VAL_ 821 ADS_5_LDWLDPSnvtySet 0 "None" 1 "high" 2 "low" 3 "reserved" ;
VAL_ 821 ADS_5_LDWWarnType 0 "None" 1 "warning only" 2 "vibration  only" 3 "warning and vibration" ;
VAL_ 821 ADS_5_NeborRiLineCrvt 1023 "Invalid" ;
VAL_ 821 ADS_5_IESSwtSet 0 "None" 1 "ON" 2 "Off" 3 "reserved" ;
VAL_ 821 ADS_5_IHCSettingSt 0 "None" 1 "ON" 2 "OFF" 3 "reserved" ;
VAL_ 821 ADS_5_ISLIWarningMod 0 "None" 1 "Display warning;" 2 "Sound+display warning" 3 "Off" ;
VAL_ 821 ADS_5_ICAEnableBtnSts 0 "None" 1 "ON" 2 "Off" 3 "reserved" ;
VAL_ 821 ADS_5_FCM_Camera_textinfo 0 "Camera normal" 1 "Camera failure" 2 "Camera blocked" 3 "Camera high temperature" ;
VAL_ 821 ADS_5_EgoRiLineID 0 "Invalid" 1 "Valid" ;
VAL_ 821 ADS_5_EgoRiLineTyp 0 "No display" 1 "Type_Unknown" 2 "Type_Solid_Line" 3 "Type_Dashed_Line" ;
VAL_ 821 ADS_5_EgoRiLineColor 0 "No display" 1 "Color_Unknown" 2 "Color_White" 3 "Color_Yellow" ;
